VERSION ""

NS_ :

BS_:

BU_: PowertrainControlModule AtmosphericSensor SafetyRestraintSystem2 Aftertreatment_2_GasOutlet Aftertreatment_2_GasIntake DieselPartFilterControl Turbocharger SafetyRestraintSystem1 CabDisplay2 Aftertreatment_1_GasOutlet Aftertreatment_1_GasIntake OnBoardDataLogger OffBoardDiagnosticTool2 OffBoardDiagnosticTool1 FileServer ParkingBrakeController SeatController2 FanDriveController SteeringColumnUnit CommunicationUnitRadio CommunicationUnitSatellite CommunicationUnitCellular PropulsionBatteryCharger ChassisController2 ChassisController1 EngineValveControl AuxiliaryHeater2 AuxiliaryHeater1 ClutchUnit RampControl InformationSystem1 SuspensionSystemController2 OilSensor VehicleDynamicStability ExhaustEmissionController TransmissionDisplay2 TransmissionDisplay1 ClimateControl2 WaterPumpController RearAxleSteeringController LightingOperatorControl SeatController1 IgnitionController2 IgnitionController1 TirePressureController CabController2 CabController1 PneumaticSystemController SuspensionSystemController1 HydraulicPumpController EnduranceBrakingSystem RetarderExhaustEngine2 OnBoardDiagnosticUnit HeadwayController RetarderExhaustEngine1 CabDisplay1 ManagementComputer VirtualTerminal OffVehicleGateway PowerTakeOffFront HitchControl AuxiliaryValveControl BodyController TractorTrailerBridge1 StarterSystem ElectricalSystem VehicleSecurity VehicleNavigation AerodynamicControl ElectricalChargingSystem ClimateControl1 TripRecorder InstrumentCluster SuspensionDriveAxle2 SuspensionDriveAxle1 SuspensionSteerAxle SteeringController FuelSystem CruiseControl RetarderDriveline RetarderEngine BrakesDriveAxle2 BrakesDriveAxle1 BrakesSystemController BrakesSteerAxle AxleDrive2 AxleDrive1 AxleSteering PowerTakeOff ShiftConsoleSecondary ShiftConsolePrimary Transmission2 Transmission1 Engine2 Engine1

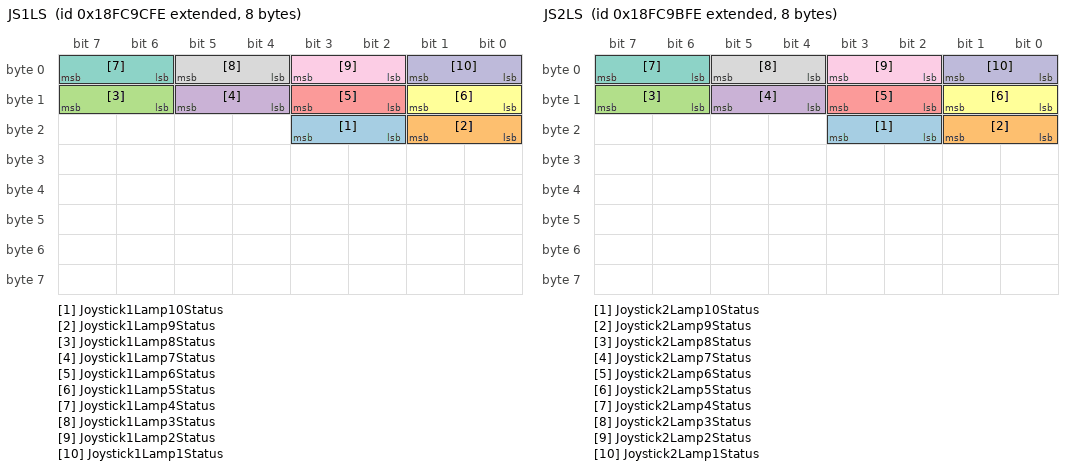
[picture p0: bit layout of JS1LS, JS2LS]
BO_ 2566692094 JS1LS: 8 Vector__XXX
 SG_ Joystick1Lamp10Status : 18|2@1+ (1,0) [0|3] "" Vector__XXX
 SG_ Joystick1Lamp9Status : 16|2@1+ (1,0) [0|3] "" Vector__XXX
 SG_ Joystick1Lamp8Status : 14|2@1+ (1,0) [0|3] "" Vector__XXX
 SG_ Joystick1Lamp7Status : 12|2@1+ (1,0) [0|3] "" Vector__XXX
 SG_ Joystick1Lamp6Status : 10|2@1+ (1,0) [0|3] "" Vector__XXX
 SG_ Joystick1Lamp5Status : 8|2@1+ (1,0) [0|3] "" Vector__XXX
 SG_ Joystick1Lamp4Status : 6|2@1+ (1,0) [0|3] "" Vector__XXX
 SG_ Joystick1Lamp3Status : 4|2@1+ (1,0) [0|3] "" Vector__XXX
 SG_ Joystick1Lamp2Status : 2|2@1+ (1,0) [0|3] "" Vector__XXX
 SG_ Joystick1Lamp1Status : 0|2@1+ (1,0) [0|3] "" Vector__XXX

BO_ 2566691838 JS2LS: 8 Vector__XXX
 SG_ Joystick2Lamp10Status : 18|2@1+ (1,0) [0|3] "" Vector__XXX
 SG_ Joystick2Lamp9Status : 16|2@1+ (1,0) [0|3] "" Vector__XXX
 SG_ Joystick2Lamp8Status : 14|2@1+ (1,0) [0|3] "" Vector__XXX
 SG_ Joystick2Lamp7Status : 12|2@1+ (1,0) [0|3] "" Vector__XXX
 SG_ Joystick2Lamp6Status : 10|2@1+ (1,0) [0|3] "" Vector__XXX
 SG_ Joystick2Lamp5Status : 8|2@1+ (1,0) [0|3] "" Vector__XXX
 SG_ Joystick2Lamp4Status : 6|2@1+ (1,0) [0|3] "" Vector__XXX
 SG_ Joystick2Lamp3Status : 4|2@1+ (1,0) [0|3] "" Vector__XXX
 SG_ Joystick2Lamp2Status : 2|2@1+ (1,0) [0|3] "" Vector__XXX
 SG_ Joystick2Lamp1Status : 0|2@1+ (1,0) [0|3] "" Vector__XXX

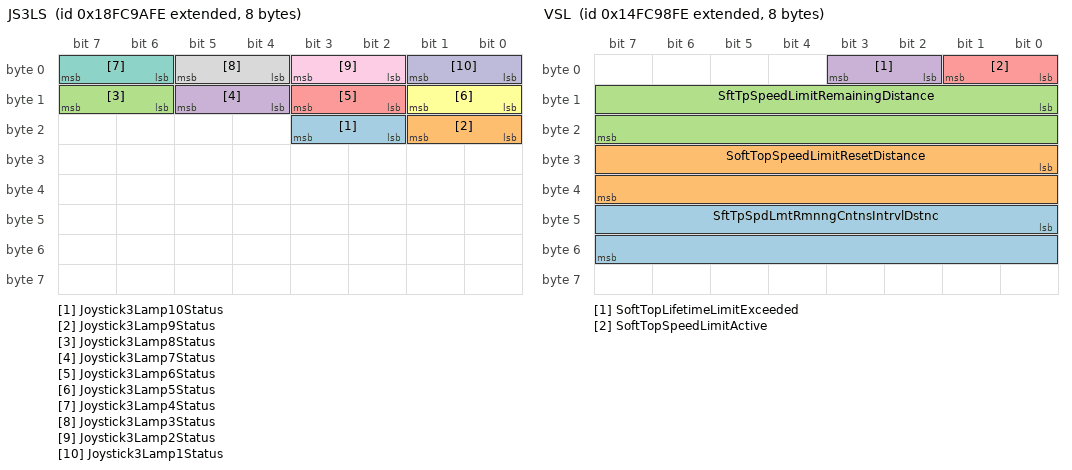
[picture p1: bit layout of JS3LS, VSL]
BO_ 2566691582 JS3LS: 8 Vector__XXX
 SG_ Joystick3Lamp10Status : 18|2@1+ (1,0) [0|3] "" Vector__XXX
 SG_ Joystick3Lamp9Status : 16|2@1+ (1,0) [0|3] "" Vector__XXX
 SG_ Joystick3Lamp8Status : 14|2@1+ (1,0) [0|3] "" Vector__XXX
 SG_ Joystick3Lamp7Status : 12|2@1+ (1,0) [0|3] "" Vector__XXX
 SG_ Joystick3Lamp6Status : 10|2@1+ (1,0) [0|3] "" Vector__XXX
 SG_ Joystick3Lamp5Status : 8|2@1+ (1,0) [0|3] "" Vector__XXX
 SG_ Joystick3Lamp4Status : 6|2@1+ (1,0) [0|3] "" Vector__XXX
 SG_ Joystick3Lamp3Status : 4|2@1+ (1,0) [0|3] "" Vector__XXX
 SG_ Joystick3Lamp2Status : 2|2@1+ (1,0) [0|3] "" Vector__XXX
 SG_ Joystick3Lamp1Status : 0|2@1+ (1,0) [0|3] "" Vector__XXX

BO_ 2566691326 AUI: 8 Vector__XXX
 SG_ AssemblyUnitIdentification : 8|8@1+ (1,0) [0|255] "" Vector__XXX
 SG_ NmbrOfAssmblyUntIdntfctionFields : 0|8@1+ (1,0) [0|250] "" Vector__XXX

BO_ 2499582206 VSL: 8 Vector__XXX
 SG_ SftTpSpdLmtRmnngCntnsIntrvlDstnc : 40|16@1+ (1,0) [0|64255] "km" Vector__XXX
 SG_ SoftTopSpeedLimitResetDistance : 24|16@1+ (1,0) [0|64255] "km" Vector__XXX
 SG_ SftTpSpeedLimitRemainingDistance : 8|16@1+ (1,0) [0|64255] "km" Vector__XXX
 SG_ SoftTopLifetimeLimitExceeded : 2|2@1+ (1,0) [0|3] "" Vector__XXX
 SG_ SoftTopSpeedLimitActive : 0|2@1+ (1,0) [0|3] "" Vector__XXX

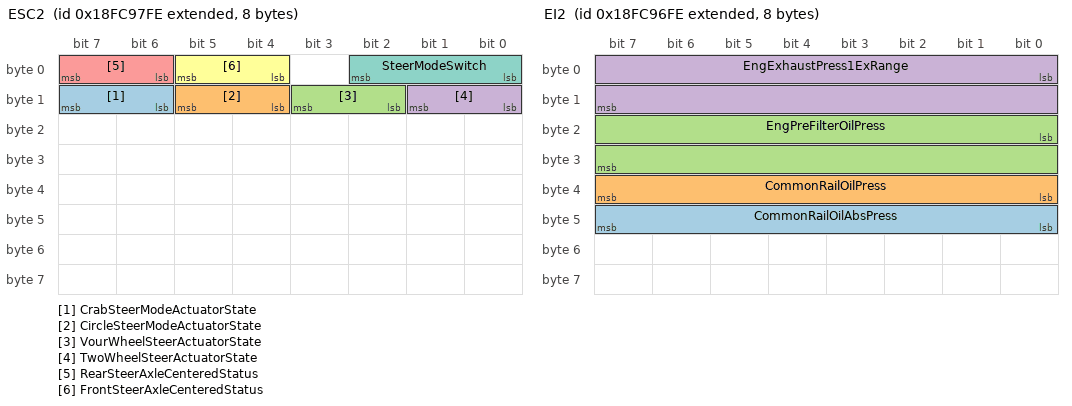
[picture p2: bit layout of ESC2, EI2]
BO_ 2566690814 ESC2: 8 Vector__XXX
 SG_ CrabSteerModeActuatorState : 14|2@1+ (1,0) [0|3] "" Vector__XXX
 SG_ CircleSteerModeActuatorState : 12|2@1+ (1,0) [0|3] "" Vector__XXX
 SG_ VourWheelSteerActuatorState : 10|2@1+ (1,0) [0|3] "" Vector__XXX
 SG_ TwoWheelSteerActuatorState : 8|2@1+ (1,0) [0|3] "" Vector__XXX
 SG_ RearSteerAxleCenteredStatus : 6|2@1+ (1,0) [0|3] "" Vector__XXX
 SG_ FrontSteerAxleCenteredStatus : 4|2@1+ (1,0) [0|3] "" Vector__XXX
 SG_ SteerModeSwitch : 0|3@1+ (1,0) [0|7] "" Vector__XXX

BO_ 2566690558 EI2: 8 Vector__XXX
 SG_ CommonRailOilAbsPress : 40|8@1+ (4,0) [0|1000] "kPa" Vector__XXX
 SG_ CommonRailOilPress : 32|8@1+ (4,0) [0|1000] "kPa" Vector__XXX
 SG_ EngPreFilterOilPress : 16|16@1+ (0.1,0) [0|6425.5] "kPa" Vector__XXX
 SG_ EngExhaustPress1ExRange : 0|16@1+ (0.125,0) [0|8031.875] "kPa" Vector__XXX

BO_ 2365363710 ECPMSI: 8 Vector__XXX
 SG_ EngCylPrssMonitor2PreliminaryFMI : 8|5@1+ (1,0) [0|31] "" Vector__XXX
 SG_ EngCylPrssMonitor1PreliminaryFMI : 0|5@1+ (1,0) [0|31] "" Vector__XXX

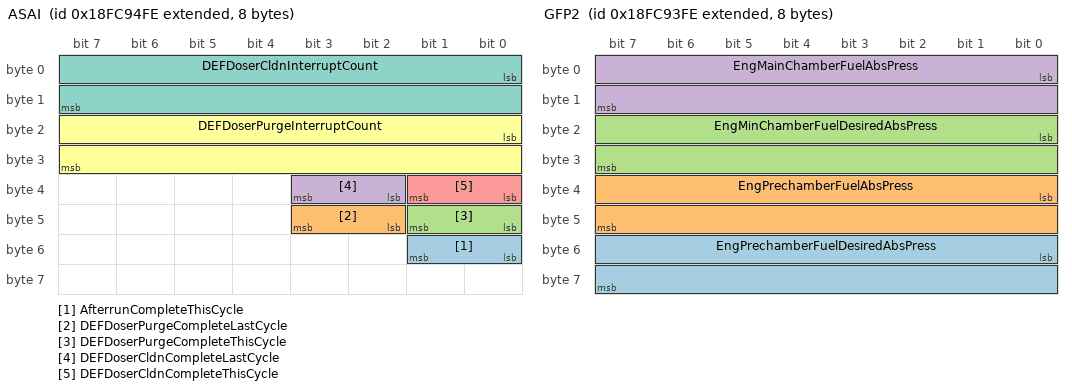
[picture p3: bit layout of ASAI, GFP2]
BO_ 2566690046 ASAI: 8 Vector__XXX
 SG_ AfterrunCompleteThisCycle : 48|2@1+ (1,0) [0|3] "" Vector__XXX
 SG_ DEFDoserPurgeCompleteLastCycle : 42|2@1+ (1,0) [0|3] "" Vector__XXX
 SG_ DEFDoserPurgeCompleteThisCycle : 40|2@1+ (1,0) [0|3] "" Vector__XXX
 SG_ DEFDoserCldnCompleteLastCycle : 34|2@1+ (1,0) [0|3] "" Vector__XXX
 SG_ DEFDoserCldnCompleteThisCycle : 32|2@1+ (1,0) [0|3] "" Vector__XXX
 SG_ DEFDoserPurgeInterruptCount : 16|16@1+ (1,0) [0|64255] "" Vector__XXX
 SG_ DEFDoserCldnInterruptCount : 0|16@1+ (1,0) [0|64255] "" Vector__XXX

BO_ 2566689790 GFP2: 8 Vector__XXX
 SG_ EngPrechamberFuelDesiredAbsPress : 48|16@1+ (0.1,0) [0|6425.5] "kPa" Vector__XXX
 SG_ EngPrechamberFuelAbsPress : 32|16@1+ (0.1,0) [0|6425.5] "kPa" Vector__XXX
 SG_ EngMinChamberFuelDesiredAbsPress : 16|16@1+ (0.1,0) [0|6425.5] "kPa" Vector__XXX
 SG_ EngMainChamberFuelAbsPress : 0|16@1+ (0.1,0) [0|6425.5] "kPa" Vector__XXX

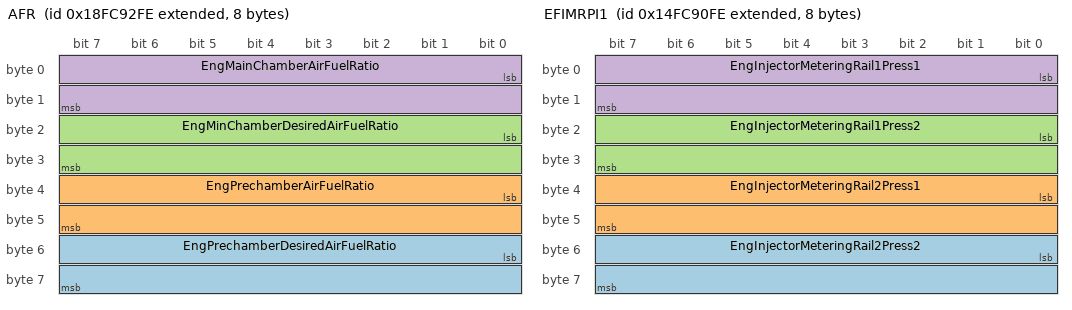
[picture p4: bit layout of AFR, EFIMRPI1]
BO_ 2566689534 AFR: 8 Vector__XXX
 SG_ EngPrechamberDesiredAirFuelRatio : 48|16@1+ (0.001,0) [0|64.255] "" Vector__XXX
 SG_ EngPrechamberAirFuelRatio : 32|16@1+ (0.001,0) [0|64.255] "" Vector__XXX
 SG_ EngMinChamberDesiredAirFuelRatio : 16|16@1+ (0.001,0) [0|64.255] "" Vector__XXX
 SG_ EngMainChamberAirFuelRatio : 0|16@1+ (0.001,0) [0|64.255] "" Vector__XXX

BO_ 2566689278 EEN: 8 Vector__XXX
 SG_ EngExhaustDesiredNOx : 16|16@1+ (0.05,-200) [-200|3012.75] "ppm" Vector__XXX
 SG_ EngExhaustNOx : 0|16@1+ (0.05,-200) [-200|3012.75] "ppm" Vector__XXX

BO_ 2499580158 EFIMRPI1: 8 Vector__XXX
 SG_ EngInjectorMeteringRail2Press2 : 48|16@1+ (0.00390625,0) [0|250.996] "MPa" Vector__XXX
 SG_ EngInjectorMeteringRail2Press1 : 32|16@1+ (0.00390625,0) [0|250.996] "MPa" Vector__XXX
 SG_ EngInjectorMeteringRail1Press2 : 16|16@1+ (0.00390625,0) [0|250.996] "MPa" Vector__XXX
 SG_ EngInjectorMeteringRail1Press1 : 0|16@1+ (0.00390625,0) [0|250.996] "MPa" Vector__XXX

BO_ 2432471038 AF3: 8 Vector__XXX
 SG_ GasFuelAccumulatorTemp : 24|8@1+ (1,-40) [-40|210] "°C" Vector__XXX
 SG_ EngFuelVaporizer1DischargeTemp : 16|8@1+ (1,-40) [-40|210] "°C" Vector__XXX
 SG_ EngGasFuelSupplyPress : 0|16@1+ (0.00390625,0) [0|250.996] "MPa" Vector__XXX

BO_ 2566688510 CFF: 8 Vector__XXX

BO_ 2566688254 PII: 8 Vector__XXX
 SG_ ProductIdentificationModel : 16|8@1+ (1,0) [0|0] "" Vector__XXX
 SG_ ProductIdentificationBrand : 8|8@1+ (1,0) [0|0] "" Vector__XXX
 SG_ ProductIdentificationCode : 0|8@1+ (1,0) [0|0] "" Vector__XXX

BO_ 2364567038 EGFVSOAC5: 8 Vector__XXX
 SG_ EngGsFlVlve20StartOfActuationCmd : 48|16@1+ (0.0078125,-400) [-400|101.99] "deg" Vector__XXX
 SG_ EngGsFlVlve19StartOfActuationCmd : 32|16@1+ (0.0078125,-400) [-400|101.99] "deg" Vector__XXX
 SG_ EngGsFlVlve18StartOfActuationCmd : 16|16@1+ (0.0078125,-400) [-400|101.99] "deg" Vector__XXX
 SG_ EngGsFlVlve17StartOfActuationCmd : 0|16@1+ (0.0078125,-400) [-400|101.99] "deg" Vector__XXX

BO_ 2364566782 EGFVSOAC4: 8 Vector__XXX
 SG_ EngGsFlVlve16StartOfActuationCmd : 48|16@1+ (0.0078125,-400) [-400|101.99] "deg" Vector__XXX
 SG_ EngGsFlVlve15StartOfActuationCmd : 32|16@1+ (0.0078125,-400) [-400|101.99] "deg" Vector__XXX
 SG_ EngGsFlVlve14StartOfActuationCmd : 16|16@1+ (0.0078125,-400) [-400|101.99] "deg" Vector__XXX
 SG_ EngGsFlVlve13StartOfActuationCmd : 0|16@1+ (0.0078125,-400) [-400|101.99] "deg" Vector__XXX

BO_ 2364566526 EGFVSOAC3: 8 Vector__XXX
 SG_ EngGsFlVlve12StartOfActuationCmd : 48|16@1+ (0.0078125,-400) [-400|101.99] "deg" Vector__XXX
 SG_ EngGsFlVlve11StartOfActuationCmd : 32|16@1+ (0.0078125,-400) [-400|101.99] "deg" Vector__XXX
 SG_ EngGsFlVlve10StartOfActuationCmd : 16|16@1+ (0.0078125,-400) [-400|101.99] "deg" Vector__XXX
 SG_ EngGsFlValve9StartOfActuationCmd : 0|16@1+ (0.0078125,-400) [-400|101.99] "deg" Vector__XXX

BO_ 2364566270 EGFVSOAC2: 8 Vector__XXX
 SG_ EngGsFlValve8StartOfActuationCmd : 48|16@1+ (0.0078125,-400) [-400|101.99] "deg" Vector__XXX
 SG_ EngGsFlValve7StartOfActuationCmd : 32|16@1+ (0.0078125,-400) [-400|101.99] "deg" Vector__XXX
 SG_ EngGsFlValve6StartOfActuationCmd : 16|16@1+ (0.0078125,-400) [-400|101.99] "deg" Vector__XXX
 SG_ EngGsFlValve5StartOfActuationCmd : 0|16@1+ (0.0078125,-400) [-400|101.99] "deg" Vector__XXX

BO_ 2364566014 EGFVSOAC1: 8 Vector__XXX
 SG_ EngGsFlValve4StartOfActuationCmd : 48|16@1+ (0.0078125,-400) [-400|101.99] "deg" Vector__XXX
 SG_ EngGsFlValve3StartOfActuationCmd : 32|16@1+ (0.0078125,-400) [-400|101.99] "deg" Vector__XXX
 SG_ EngGsFlValve2StartOfActuationCmd : 16|16@1+ (0.0078125,-400) [-400|101.99] "deg" Vector__XXX
 SG_ EngGsFlValve1StartOfActuationCmd : 0|16@1+ (0.0078125,-400) [-400|101.99] "deg" Vector__XXX

BO_ 2364565758 EGFVDC5: 8 Vector__XXX
 SG_ EngGasFuelValve20DurationCmd : 48|16@1+ (2,0) [0|128510] "µs" Vector__XXX
 SG_ EngGasFuelValve19DurationCmd : 32|16@1+ (2,0) [0|128510] "µs" Vector__XXX
 SG_ EngGasFuelValve18DurationCmd : 16|16@1+ (2,0) [0|128510] "µs" Vector__XXX
 SG_ EngGasFuelValve17DurationCmd : 0|16@1+ (2,0) [0|128510] "µs" Vector__XXX

BO_ 2364565502 EGFVDC4: 8 Vector__XXX
 SG_ EngGasFuelValve16DurationCmd : 48|16@1+ (2,0) [0|128510] "µs" Vector__XXX
 SG_ EngGasFuelValve15DurationCmd : 32|16@1+ (2,0) [0|128510] "µs" Vector__XXX
 SG_ EngGasFuelValve14DurationCmd : 16|16@1+ (2,0) [0|128510] "µs" Vector__XXX
 SG_ EngGasFuelValve13DurationCmd : 0|16@1+ (2,0) [0|128510] "µs" Vector__XXX

BO_ 2364565246 EGFVDC3: 8 Vector__XXX
 SG_ EngGasFuelValve12DurationCmd : 48|16@1+ (2,0) [0|128510] "µs" Vector__XXX
 SG_ EngGasFuelValve11DurationCmd : 32|16@1+ (2,0) [0|128510] "µs" Vector__XXX
 SG_ EngGasFuelValve10DurationCmd : 16|16@1+ (2,0) [0|128510] "µs" Vector__XXX
 SG_ EngGasFuelValve9DurationCmd : 0|16@1+ (2,0) [0|128510] "µs" Vector__XXX

BO_ 2364564990 EGFVDC2: 8 Vector__XXX
 SG_ EngGasFuelValve8DurationCmd : 48|16@1+ (2,0) [0|128510] "µs" Vector__XXX
 SG_ EngGasFuelValve7DurationCmd : 32|16@1+ (2,0) [0|128510] "µs" Vector__XXX
 SG_ EngGasFuelValve6DurationCmd : 16|16@1+ (2,0) [0|128510] "µs" Vector__XXX
 SG_ EngGasFuelValve5DurationCmd : 0|16@1+ (2,0) [0|128510] "µs" Vector__XXX

BO_ 2364564734 EGFVDC1: 8 Vector__XXX
 SG_ EngGasFuelValve4DurationCmd : 48|16@1+ (2,0) [0|128510] "µs" Vector__XXX
 SG_ EngGasFuelValve3DurationCmd : 32|16@1+ (2,0) [0|128510] "µs" Vector__XXX
 SG_ EngGasFuelValve2DurationCmd : 16|16@1+ (2,0) [0|128510] "µs" Vector__XXX
 SG_ EngGasFuelValve1DurationCmd : 0|16@1+ (2,0) [0|128510] "µs" Vector__XXX

BO_ 2364564478 GFI5: 8 Vector__XXX
 SG_ EngGsFlVlvNmnlStrtOfActuationCmd : 16|16@1+ (0.0078125,-400) [-400|101.99] "deg" Vector__XXX
 SG_ EngGsFuelValveNominalDurationCmd : 0|16@1+ (2,0) [0|128510] "µs" Vector__XXX

BO_ 2297455358 ETC12: 8 Vector__XXX
 SG_ TransDirectionalOutputShaftSpeed : 32|16@1+ (1,-32127) [-32127|32128] "rpm" Vector__XXX
 SG_ TransHydrostaticLoop2Press : 16|16@1+ (1,0) [0|64255] "kPa" Vector__XXX
 SG_ TransHydrostaticLoop1Press : 0|16@1+ (1,0) [0|64255] "kPa" Vector__XXX

BO_ 2498781694 ECCAI20: 8 Vector__XXX
 SG_ EngCyl20AvrageCombustionDuration : 48|16@1+ (0.0078125,0) [0|501.99] "deg" Vector__XXX
 SG_ EngCyl20AvrgCntrOfCmbstionTiming : 32|16@1+ (0.0078125,-250) [-250|250.992] "deg" Vector__XXX
 SG_ EngCyl20AvrgStrtOfCmbstionTiming : 16|16@1+ (0.0078125,-250) [-250|250.992] "deg" Vector__XXX
 SG_ EngCyl20IndctdMeanEffectivePress : 0|16@1+ (0.0001220703125,-1) [-1|6.84362793] "MPa" Vector__XXX

BO_ 2498781438 ECCAI19: 8 Vector__XXX
 SG_ EngCyl19AvrageCombustionDuration : 48|16@1+ (0.0078125,0) [0|501.99] "deg" Vector__XXX
 SG_ EngCyl19AvrgCntrOfCmbstionTiming : 32|16@1+ (0.0078125,-250) [-250|250.992] "deg" Vector__XXX
 SG_ EngCyl19AvrgStrtOfCmbstionTiming : 16|16@1+ (0.0078125,-250) [-250|250.992] "deg" Vector__XXX
 SG_ EngCyl19IndctdMeanEffectivePress : 0|16@1+ (0.0001220703125,-1) [-1|6.84362793] "MPa" Vector__XXX

BO_ 2498781182 ECCAI18: 8 Vector__XXX
 SG_ EngCyl18AvrageCombustionDuration : 48|16@1+ (0.0078125,0) [0|501.99] "deg" Vector__XXX
 SG_ EngCyl18AvrgCntrOfCmbstionTiming : 32|16@1+ (0.0078125,-250) [-250|250.992] "deg" Vector__XXX
 SG_ EngCyl18AvrgStrtOfCmbstionTiming : 16|16@1+ (0.0078125,-250) [-250|250.992] "deg" Vector__XXX
 SG_ EngCyl18IndctdMeanEffectivePress : 0|16@1+ (0.0001220703125,-1) [-1|6.84362793] "MPa" Vector__XXX

BO_ 2498780926 ECCAI17: 8 Vector__XXX
 SG_ EngCyl17AvrageCombustionDuration : 48|16@1+ (0.0078125,0) [0|501.99] "deg" Vector__XXX
 SG_ EngCyl17AvrgCntrOfCmbstionTiming : 32|16@1+ (0.0078125,-250) [-250|250.992] "deg" Vector__XXX
 SG_ EngCyl17AvrgStrtOfCmbstionTiming : 16|16@1+ (0.0078125,-250) [-250|250.992] "deg" Vector__XXX
 SG_ EngCyl17IndctdMeanEffectivePress : 0|16@1+ (0.0001220703125,-1) [-1|6.84362793] "MPa" Vector__XXX

BO_ 2498780670 ECCAI16: 8 Vector__XXX
 SG_ EngCyl16AvrageCombustionDuration : 48|16@1+ (0.0078125,0) [0|501.99] "deg" Vector__XXX
 SG_ EngCyl16AvrgCntrOfCmbstionTiming : 32|16@1+ (0.0078125,-250) [-250|250.992] "deg" Vector__XXX
 SG_ EngCyl16AvrgStrtOfCmbstionTiming : 16|16@1+ (0.0078125,-250) [-250|250.992] "deg" Vector__XXX
 SG_ EngCyl16IndctdMeanEffectivePress : 0|16@1+ (0.0001220703125,-1) [-1|6.84362793] "MPa" Vector__XXX

BO_ 2498780414 ECCAI15: 8 Vector__XXX
 SG_ EngCyl15AvrageCombustionDuration : 48|16@1+ (0.0078125,0) [0|501.99] "deg" Vector__XXX
 SG_ EngCyl15AvrgCntrOfCmbstionTiming : 32|16@1+ (0.0078125,-250) [-250|250.992] "deg" Vector__XXX
 SG_ EngCyl15AvrgStrtOfCmbstionTiming : 16|16@1+ (0.0078125,-250) [-250|250.992] "deg" Vector__XXX
 SG_ EngCyl15IndctdMeanEffectivePress : 0|16@1+ (0.0001220703125,-1) [-1|6.84362793] "MPa" Vector__XXX

BO_ 2498780158 ECCAI14: 8 Vector__XXX
 SG_ EngCyl14AvrageCombustionDuration : 48|16@1+ (0.0078125,0) [0|501.99] "deg" Vector__XXX
 SG_ EngCyl14AvrgCntrOfCmbstionTiming : 32|16@1+ (0.0078125,-250) [-250|250.992] "deg" Vector__XXX
 SG_ EngCyl14AvrgStrtOfCmbstionTiming : 16|16@1+ (0.0078125,-250) [-250|250.992] "deg" Vector__XXX
 SG_ EngCyl14IndctdMeanEffectivePress : 0|16@1+ (0.0001220703125,-1) [-1|6.84362793] "MPa" Vector__XXX

BO_ 2498779902 ECCAI13: 8 Vector__XXX
 SG_ EngCyl13AvrageCombustionDuration : 48|16@1+ (0.0078125,0) [0|501.99] "deg" Vector__XXX
 SG_ EngCyl13AvrgCntrOfCmbstionTiming : 32|16@1+ (0.0078125,-250) [-250|250.992] "deg" Vector__XXX
 SG_ EngCyl13AvrgStrtOfCmbstionTiming : 16|16@1+ (0.0078125,-250) [-250|250.992] "deg" Vector__XXX
 SG_ EngCyl13IndctdMeanEffectivePress : 0|16@1+ (0.0001220703125,-1) [-1|6.84362793] "MPa" Vector__XXX

BO_ 2498779646 ECCAI12: 8 Vector__XXX
 SG_ EngCyl12AvrageCombustionDuration : 48|16@1+ (0.0078125,0) [0|501.99] "deg" Vector__XXX
 SG_ EngCyl12AvrgCntrOfCmbstionTiming : 32|16@1+ (0.0078125,-250) [-250|250.992] "deg" Vector__XXX
 SG_ EngCyl12AvrgStrtOfCmbstionTiming : 16|16@1+ (0.0078125,-250) [-250|250.992] "deg" Vector__XXX
 SG_ EngCyl12IndctdMeanEffectivePress : 0|16@1+ (0.0001220703125,-1) [-1|6.84362793] "MPa" Vector__XXX

BO_ 2498779390 ECCAI11: 8 Vector__XXX
 SG_ EngCyl11AvrageCombustionDuration : 48|16@1+ (0.0078125,0) [0|501.99] "deg" Vector__XXX
 SG_ EngCyl11AvrgCntrOfCmbstionTiming : 32|16@1+ (0.0078125,-250) [-250|250.992] "deg" Vector__XXX
 SG_ EngCyl11AvrgStrtOfCmbstionTiming : 16|16@1+ (0.0078125,-250) [-250|250.992] "deg" Vector__XXX
 SG_ EngCyl11IndctdMeanEffectivePress : 0|16@1+ (0.0001220703125,-1) [-1|6.84362793] "MPa" Vector__XXX

BO_ 2498779134 ECCAI10: 8 Vector__XXX
 SG_ EngCyl10AvrageCombustionDuration : 48|16@1+ (0.0078125,0) [0|501.99] "deg" Vector__XXX
 SG_ EngCyl10AvrgCntrOfCmbstionTiming : 32|16@1+ (0.0078125,-250) [-250|250.992] "deg" Vector__XXX
 SG_ EngCyl10AvrgStrtOfCmbstionTiming : 16|16@1+ (0.0078125,-250) [-250|250.992] "deg" Vector__XXX
 SG_ EngCyl10IndctdMeanEffectivePress : 0|16@1+ (0.0001220703125,-1) [-1|6.84362793] "MPa" Vector__XXX

BO_ 2498778878 ECCAI9: 8 Vector__XXX
 SG_ EngCyl9AverageCombustionDuration : 48|16@1+ (0.0078125,0) [0|501.99] "deg" Vector__XXX
 SG_ EngCyl9AvrgCntrOfCmbustionTiming : 32|16@1+ (0.0078125,-250) [-250|250.992] "deg" Vector__XXX
 SG_ EngCyl9AvrgStrtOfCmbustionTiming : 16|16@1+ (0.0078125,-250) [-250|250.992] "deg" Vector__XXX
 SG_ EngCyl9IndctedMeanEffectivePress : 0|16@1+ (0.0001220703125,-1) [-1|6.84362793] "MPa" Vector__XXX

BO_ 2566757118 EBS24: 8 Vector__XXX

BO_ 2559246078 RGE12: 8 Vector__XXX

BO_ 2559180542 RGE24: 8 Vector__XXX

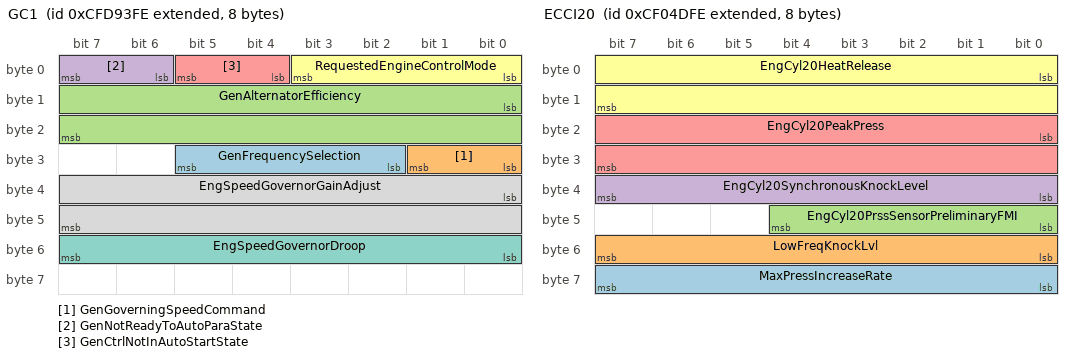
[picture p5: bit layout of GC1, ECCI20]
BO_ 2365428734 GC1: 8 Vector__XXX
 SG_ GenFrequencySelection : 26|4@1+ (1,0) [0|15] "" Vector__XXX
 SG_ GenGoverningSpeedCommand : 24|2@1+ (1,0) [0|3] "" Vector__XXX
 SG_ GenAlternatorEfficiency : 8|16@1+ (0.0025,0) [0|100] "%" Vector__XXX
 SG_ GenNotReadyToAutoParaState : 6|2@1+ (1,0) [0|3] "" Vector__XXX
 SG_ GenCtrlNotInAutoStartState : 4|2@1+ (1,0) [0|3] "" Vector__XXX
 SG_ RequestedEngineControlMode : 0|4@1+ (1,0) [0|15] "" Vector__XXX
 SG_ EngSpeedGovernorDroop : 48|8@1+ (0.04,0) [0|10] "%" Vector__XXX
 SG_ EngSpeedGovernorGainAdjust : 32|16@1+ (1,-32128) [-32128|32127] "" Vector__XXX

BO_ 2566702846 DM57: 8 Vector__XXX
 SG_ EngOBDWarmUpSequence : 0|2@1+ (1,0) [0|3] "" Vector__XXX

BO_ 2566703102 DM56: 208 Vector__XXX
 SG_ CertificationEngineFamilyName : 64|64@1+ (1,0) [0|255] "" Vector__XXX
 SG_ ModelYear : 0|64@1+ (1,0) [0|255] "" Vector__XXX

BO_ 2566705918 DM54: 22 Vector__XXX
 SG_ DTC1 : 16|32@1+ (1,0) [0|4294967295] "" Vector__XXX
 SG_ FlashProtectLamp : 8|2@1+ (1,0) [0|3] "" Vector__XXX
 SG_ FlashAmberWarningLamp : 10|2@1+ (1,0) [0|3] "" Vector__XXX
 SG_ FlashRedStopLamp : 12|2@1+ (1,0) [0|3] "" Vector__XXX
 SG_ FlashMalfuncIndicatorLamp : 14|2@1+ (1,0) [0|3] "" Vector__XXX
 SG_ ProtectLampStatus : 0|2@1+ (1,0) [0|3] "" Vector__XXX
 SG_ AmberWarningLampStatus : 2|2@1+ (1,0) [0|3] "" Vector__XXX
 SG_ RedStopLampState : 4|2@1+ (1,0) [0|3] "" Vector__XXX
 SG_ MalfunctionIndicatorLampStatus : 6|2@1+ (1,0) [0|3] "" Vector__XXX
 SG_ DTC5 : 144|32@1+ (1,0) [0|4294967295] "" Vector__XXX
 SG_ DTC4 : 112|32@1+ (1,0) [0|4294967295] "" Vector__XXX
 SG_ DTC3 : 80|32@1+ (1,0) [0|4294967295] "" Vector__XXX
 SG_ DTC2 : 48|32@1+ (1,0) [0|4294967295] "" Vector__XXX

BO_ 2566705662 DM53: 22 Vector__XXX
 SG_ DTC1 : 16|32@1+ (1,0) [0|4294967295] "" Vector__XXX
 SG_ FlashProtectLamp : 8|2@1+ (1,0) [0|3] "" Vector__XXX
 SG_ FlashAmberWarningLamp : 10|2@1+ (1,0) [0|3] "" Vector__XXX
 SG_ FlashRedStopLamp : 12|2@1+ (1,0) [0|3] "" Vector__XXX
 SG_ FlashMalfuncIndicatorLamp : 14|2@1+ (1,0) [0|3] "" Vector__XXX
 SG_ ProtectLampStatus : 0|2@1+ (1,0) [0|3] "" Vector__XXX
 SG_ AmberWarningLampStatus : 2|2@1+ (1,0) [0|3] "" Vector__XXX
 SG_ RedStopLampState : 4|2@1+ (1,0) [0|3] "" Vector__XXX
 SG_ MalfunctionIndicatorLampStatus : 6|2@1+ (1,0) [0|3] "" Vector__XXX
 SG_ DTC5 : 144|32@1+ (1,0) [0|4294967295] "" Vector__XXX
 SG_ DTC4 : 112|32@1+ (1,0) [0|4294967295] "" Vector__XXX
 SG_ DTC3 : 80|32@1+ (1,0) [0|4294967295] "" Vector__XXX
 SG_ DTC2 : 48|32@1+ (1,0) [0|4294967295] "" Vector__XXX

BO_ 2566706174 DM55: 0 Vector__XXX

BO_ 2349465342 SRASI: 8 Vector__XXX
 SG_ StaticRollAngleStatus : 8|3@1+ (1,0) [0|7] "" Vector__XXX
 SG_ StaticRollAngle : 0|8@1+ (1,-125) [-90|90] "deg" Vector__XXX

BO_ 2498777086 ECCAI2: 8 Vector__XXX
 SG_ EngCyl2AverageCombustionDuration : 48|16@1+ (0.0078125,0) [0|501.99] "deg" Vector__XXX
 SG_ EngCyl2AvrgCntrOfCmbustionTiming : 32|16@1+ (0.0078125,-250) [-250|250.992] "deg" Vector__XXX
 SG_ EngCyl2AvrgStrtOfCmbustionTiming : 16|16@1+ (0.0078125,-250) [-250|250.992] "deg" Vector__XXX
 SG_ EngCyl2IndctedMeanEffectivePress : 0|16@1+ (0.0001220703125,-1) [-1|6.84362793] "MPa" Vector__XXX

BO_ 2498776830 ECCAI1: 8 Vector__XXX
 SG_ EngCyl1AverageCombustionDuration : 48|16@1+ (0.0078125,0) [0|501.99] "deg" Vector__XXX
 SG_ EngCyl1AvrgCntrOfCmbustionTiming : 32|16@1+ (0.0078125,-250) [-250|250.992] "deg" Vector__XXX
 SG_ EngCyl1AvrgStrtOfCmbustionTiming : 16|16@1+ (0.0078125,-250) [-250|250.992] "deg" Vector__XXX
 SG_ EngCyl1IndctedMeanEffectivePress : 0|16@1+ (0.0001220703125,-1) [-1|6.84362793] "MPa" Vector__XXX

BO_ 2364558846 ECCI20: 8 Vector__XXX
 SG_ MaxPressIncreaseRate : 56|8@1+ (16,0) [0|4000] "kPa/deg crank angle" Vector__XXX
 SG_ LowFreqKnockLvl : 48|8@1+ (1,0) [0|250] "%" Vector__XXX
 SG_ EngCyl20PrssSensorPreliminaryFMI : 40|5@1+ (1,0) [0|31] "" Vector__XXX
 SG_ EngCyl20SynchronousKnockLevel : 32|8@1+ (1,0) [0|250] "%" Vector__XXX
 SG_ EngCyl20PeakPress : 16|16@1+ (0.0009765625,0) [0|62.74902344] "MPa" Vector__XXX
 SG_ EngCyl20HeatRelease : 0|16@1+ (0.0001220703125,-1) [-1|6.84362793] "kJ/l" Vector__XXX

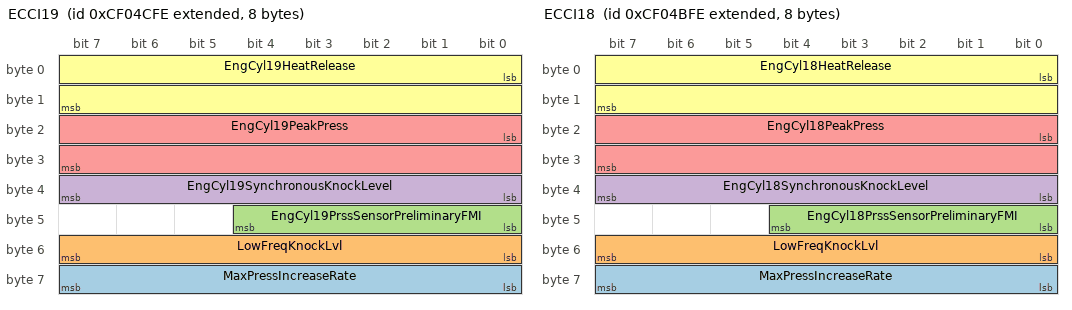
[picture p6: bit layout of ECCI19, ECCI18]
BO_ 2364558590 ECCI19: 8 Vector__XXX
 SG_ MaxPressIncreaseRate : 56|8@1+ (16,0) [0|4000] "kPa/deg crank angle" Vector__XXX
 SG_ LowFreqKnockLvl : 48|8@1+ (1,0) [0|250] "%" Vector__XXX
 SG_ EngCyl19PrssSensorPreliminaryFMI : 40|5@1+ (1,0) [0|31] "" Vector__XXX
 SG_ EngCyl19SynchronousKnockLevel : 32|8@1+ (1,0) [0|250] "%" Vector__XXX
 SG_ EngCyl19PeakPress : 16|16@1+ (0.0009765625,0) [0|62.74902344] "MPa" Vector__XXX
 SG_ EngCyl19HeatRelease : 0|16@1+ (0.0001220703125,-1) [-1|6.84362793] "kJ/l" Vector__XXX

BO_ 2364558334 ECCI18: 8 Vector__XXX
 SG_ MaxPressIncreaseRate : 56|8@1+ (16,0) [0|4000] "kPa/deg crank angle" Vector__XXX
 SG_ LowFreqKnockLvl : 48|8@1+ (1,0) [0|250] "%" Vector__XXX
 SG_ EngCyl18PrssSensorPreliminaryFMI : 40|5@1+ (1,0) [0|31] "" Vector__XXX
 SG_ EngCyl18SynchronousKnockLevel : 32|8@1+ (1,0) [0|250] "%" Vector__XXX
 SG_ EngCyl18PeakPress : 16|16@1+ (0.0009765625,0) [0|62.74902344] "MPa" Vector__XXX
 SG_ EngCyl18HeatRelease : 0|16@1+ (0.0001220703125,-1) [-1|6.84362793] "kJ/l" Vector__XXX

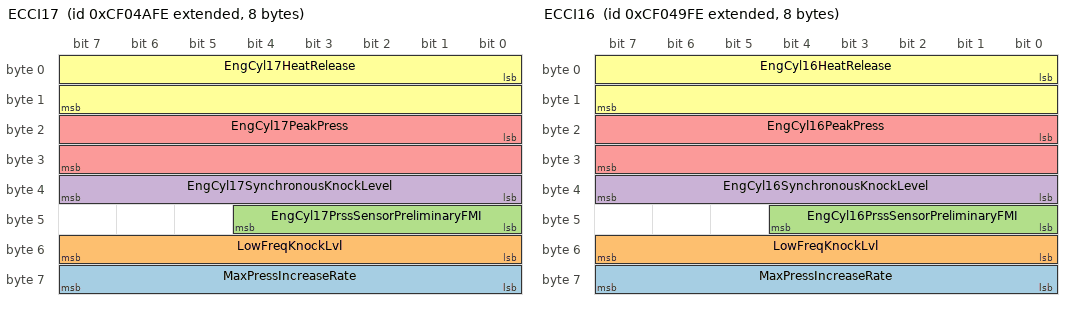
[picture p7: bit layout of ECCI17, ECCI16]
BO_ 2364558078 ECCI17: 8 Vector__XXX
 SG_ MaxPressIncreaseRate : 56|8@1+ (16,0) [0|4000] "kPa/deg crank angle" Vector__XXX
 SG_ LowFreqKnockLvl : 48|8@1+ (1,0) [0|250] "%" Vector__XXX
 SG_ EngCyl17PrssSensorPreliminaryFMI : 40|5@1+ (1,0) [0|31] "" Vector__XXX
 SG_ EngCyl17SynchronousKnockLevel : 32|8@1+ (1,0) [0|250] "%" Vector__XXX
 SG_ EngCyl17PeakPress : 16|16@1+ (0.0009765625,0) [0|62.74902344] "MPa" Vector__XXX
 SG_ EngCyl17HeatRelease : 0|16@1+ (0.0001220703125,-1) [-1|6.84362793] "kJ/l" Vector__XXX

BO_ 2364557822 ECCI16: 8 Vector__XXX
 SG_ MaxPressIncreaseRate : 56|8@1+ (16,0) [0|4000] "kPa/deg crank angle" Vector__XXX
 SG_ LowFreqKnockLvl : 48|8@1+ (1,0) [0|250] "%" Vector__XXX
 SG_ EngCyl16PrssSensorPreliminaryFMI : 40|5@1+ (1,0) [0|31] "" Vector__XXX
 SG_ EngCyl16SynchronousKnockLevel : 32|8@1+ (1,0) [0|250] "%" Vector__XXX
 SG_ EngCyl16PeakPress : 16|16@1+ (0.0009765625,0) [0|62.74902344] "MPa" Vector__XXX
 SG_ EngCyl16HeatRelease : 0|16@1+ (0.0001220703125,-1) [-1|6.84362793] "kJ/l" Vector__XXX

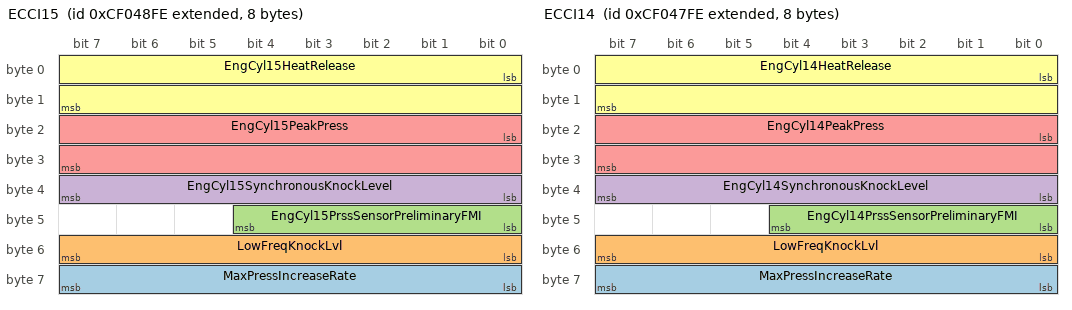
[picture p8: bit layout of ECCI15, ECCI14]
BO_ 2364557566 ECCI15: 8 Vector__XXX
 SG_ MaxPressIncreaseRate : 56|8@1+ (16,0) [0|4000] "kPa/deg crank angle" Vector__XXX
 SG_ LowFreqKnockLvl : 48|8@1+ (1,0) [0|250] "%" Vector__XXX
 SG_ EngCyl15PrssSensorPreliminaryFMI : 40|5@1+ (1,0) [0|31] "" Vector__XXX
 SG_ EngCyl15SynchronousKnockLevel : 32|8@1+ (1,0) [0|250] "%" Vector__XXX
 SG_ EngCyl15PeakPress : 16|16@1+ (0.0009765625,0) [0|62.74902344] "MPa" Vector__XXX
 SG_ EngCyl15HeatRelease : 0|16@1+ (0.0001220703125,-1) [-1|6.84362793] "kJ/l" Vector__XXX

BO_ 2364557310 ECCI14: 8 Vector__XXX
 SG_ MaxPressIncreaseRate : 56|8@1+ (16,0) [0|4000] "kPa/deg crank angle" Vector__XXX
 SG_ LowFreqKnockLvl : 48|8@1+ (1,0) [0|250] "%" Vector__XXX
 SG_ EngCyl14PrssSensorPreliminaryFMI : 40|5@1+ (1,0) [0|31] "" Vector__XXX
 SG_ EngCyl14SynchronousKnockLevel : 32|8@1+ (1,0) [0|250] "%" Vector__XXX
 SG_ EngCyl14PeakPress : 16|16@1+ (0.0009765625,0) [0|62.74902344] "MPa" Vector__XXX
 SG_ EngCyl14HeatRelease : 0|16@1+ (0.0001220703125,-1) [-1|6.84362793] "kJ/l" Vector__XXX

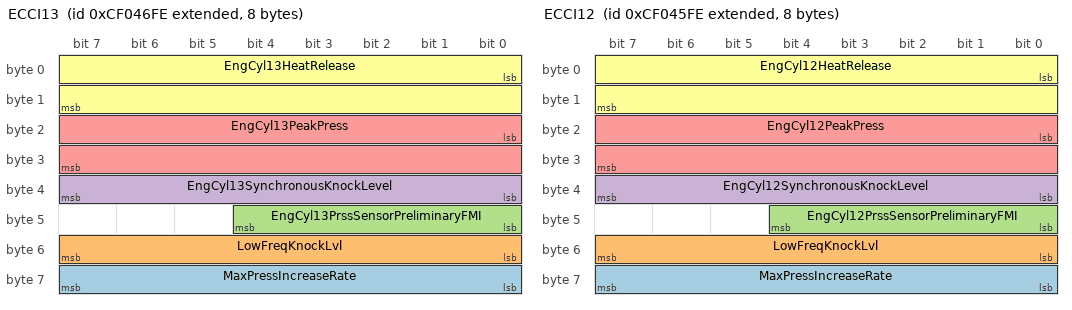
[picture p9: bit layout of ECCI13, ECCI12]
BO_ 2364557054 ECCI13: 8 Vector__XXX
 SG_ MaxPressIncreaseRate : 56|8@1+ (16,0) [0|4000] "kPa/deg crank angle" Vector__XXX
 SG_ LowFreqKnockLvl : 48|8@1+ (1,0) [0|250] "%" Vector__XXX
 SG_ EngCyl13PrssSensorPreliminaryFMI : 40|5@1+ (1,0) [0|31] "" Vector__XXX
 SG_ EngCyl13SynchronousKnockLevel : 32|8@1+ (1,0) [0|250] "%" Vector__XXX
 SG_ EngCyl13PeakPress : 16|16@1+ (0.0009765625,0) [0|62.74902344] "MPa" Vector__XXX
 SG_ EngCyl13HeatRelease : 0|16@1+ (0.0001220703125,-1) [-1|6.84362793] "kJ/l" Vector__XXX

BO_ 2364556798 ECCI12: 8 Vector__XXX
 SG_ MaxPressIncreaseRate : 56|8@1+ (16,0) [0|4000] "kPa/deg crank angle" Vector__XXX
 SG_ LowFreqKnockLvl : 48|8@1+ (1,0) [0|250] "%" Vector__XXX
 SG_ EngCyl12PrssSensorPreliminaryFMI : 40|5@1+ (1,0) [0|31] "" Vector__XXX
 SG_ EngCyl12SynchronousKnockLevel : 32|8@1+ (1,0) [0|250] "%" Vector__XXX
 SG_ EngCyl12PeakPress : 16|16@1+ (0.0009765625,0) [0|62.74902344] "MPa" Vector__XXX
 SG_ EngCyl12HeatRelease : 0|16@1+ (0.0001220703125,-1) [-1|6.84362793] "kJ/l" Vector__XXX

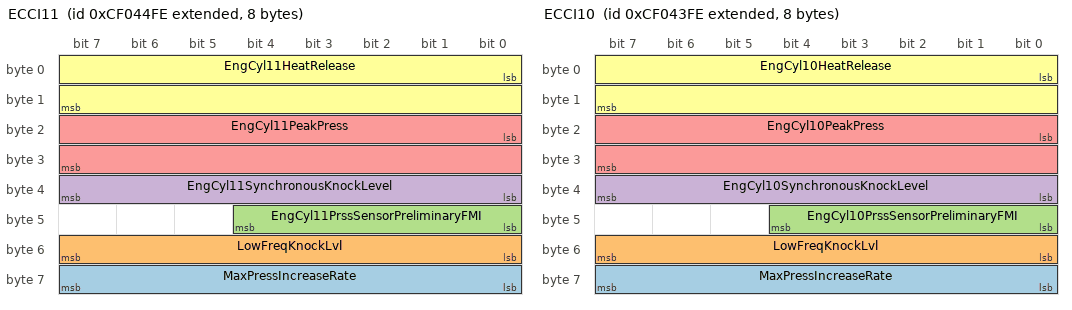
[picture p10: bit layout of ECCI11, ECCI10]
BO_ 2364556542 ECCI11: 8 Vector__XXX
 SG_ MaxPressIncreaseRate : 56|8@1+ (16,0) [0|4000] "kPa/deg crank angle" Vector__XXX
 SG_ LowFreqKnockLvl : 48|8@1+ (1,0) [0|250] "%" Vector__XXX
 SG_ EngCyl11PrssSensorPreliminaryFMI : 40|5@1+ (1,0) [0|31] "" Vector__XXX
 SG_ EngCyl11SynchronousKnockLevel : 32|8@1+ (1,0) [0|250] "%" Vector__XXX
 SG_ EngCyl11PeakPress : 16|16@1+ (0.0009765625,0) [0|62.74902344] "MPa" Vector__XXX
 SG_ EngCyl11HeatRelease : 0|16@1+ (0.0001220703125,-1) [-1|6.84362793] "kJ/l" Vector__XXX

BO_ 2364556286 ECCI10: 8 Vector__XXX
 SG_ MaxPressIncreaseRate : 56|8@1+ (16,0) [0|4000] "kPa/deg crank angle" Vector__XXX
 SG_ LowFreqKnockLvl : 48|8@1+ (1,0) [0|250] "%" Vector__XXX
 SG_ EngCyl10PrssSensorPreliminaryFMI : 40|5@1+ (1,0) [0|31] "" Vector__XXX
 SG_ EngCyl10SynchronousKnockLevel : 32|8@1+ (1,0) [0|250] "%" Vector__XXX
 SG_ EngCyl10PeakPress : 16|16@1+ (0.0009765625,0) [0|62.74902344] "MPa" Vector__XXX
 SG_ EngCyl10HeatRelease : 0|16@1+ (0.0001220703125,-1) [-1|6.84362793] "kJ/l" Vector__XXX

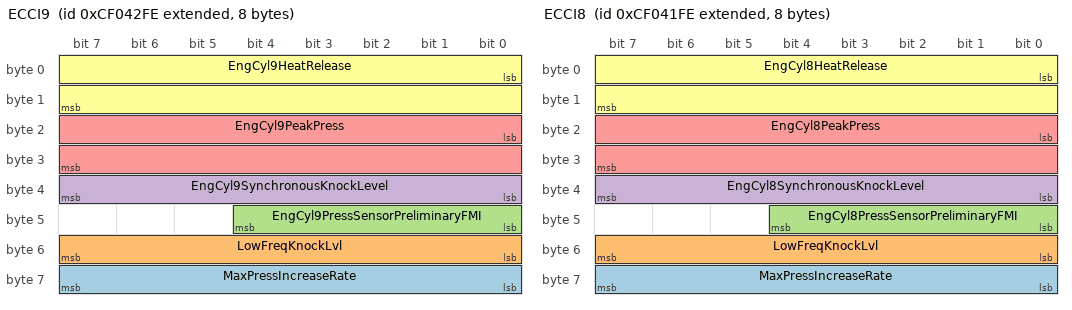
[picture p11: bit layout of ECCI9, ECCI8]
BO_ 2364556030 ECCI9: 8 Vector__XXX
 SG_ MaxPressIncreaseRate : 56|8@1+ (16,0) [0|4000] "kPa/deg crank angle" Vector__XXX
 SG_ LowFreqKnockLvl : 48|8@1+ (1,0) [0|250] "%" Vector__XXX
 SG_ EngCyl9PressSensorPreliminaryFMI : 40|5@1+ (1,0) [0|31] "" Vector__XXX
 SG_ EngCyl9SynchronousKnockLevel : 32|8@1+ (1,0) [0|250] "%" Vector__XXX
 SG_ EngCyl9PeakPress : 16|16@1+ (0.0009765625,0) [0|62.74902344] "MPa" Vector__XXX
 SG_ EngCyl9HeatRelease : 0|16@1+ (0.0001220703125,-1) [-1|6.84362793] "kJ/l" Vector__XXX

BO_ 2364555774 ECCI8: 8 Vector__XXX
 SG_ MaxPressIncreaseRate : 56|8@1+ (16,0) [0|4000] "kPa/deg crank angle" Vector__XXX
 SG_ LowFreqKnockLvl : 48|8@1+ (1,0) [0|250] "%" Vector__XXX
 SG_ EngCyl8PressSensorPreliminaryFMI : 40|5@1+ (1,0) [0|31] "" Vector__XXX
 SG_ EngCyl8SynchronousKnockLevel : 32|8@1+ (1,0) [0|250] "%" Vector__XXX
 SG_ EngCyl8PeakPress : 16|16@1+ (0.0009765625,0) [0|62.74902344] "MPa" Vector__XXX
 SG_ EngCyl8HeatRelease : 0|16@1+ (0.0001220703125,-1) [-1|6.84362793] "kJ/l" Vector__XXX

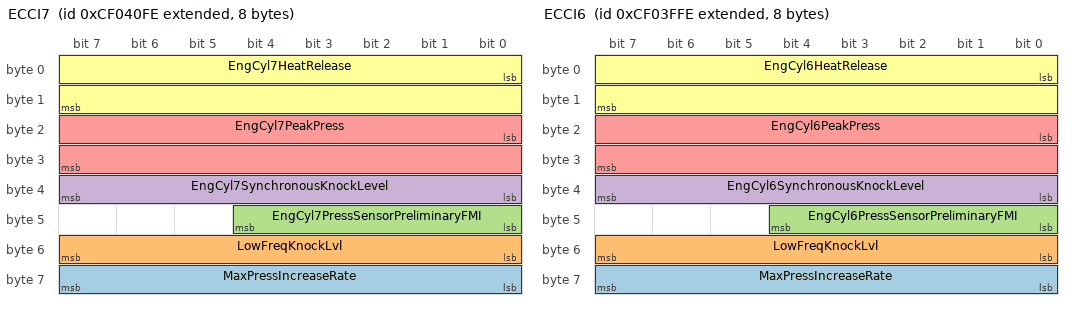
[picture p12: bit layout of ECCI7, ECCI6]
BO_ 2364555518 ECCI7: 8 Vector__XXX
 SG_ MaxPressIncreaseRate : 56|8@1+ (16,0) [0|4000] "kPa/deg crank angle" Vector__XXX
 SG_ LowFreqKnockLvl : 48|8@1+ (1,0) [0|250] "%" Vector__XXX
 SG_ EngCyl7PressSensorPreliminaryFMI : 40|5@1+ (1,0) [0|31] "" Vector__XXX
 SG_ EngCyl7SynchronousKnockLevel : 32|8@1+ (1,0) [0|250] "%" Vector__XXX
 SG_ EngCyl7PeakPress : 16|16@1+ (0.0009765625,0) [0|62.74902344] "MPa" Vector__XXX
 SG_ EngCyl7HeatRelease : 0|16@1+ (0.0001220703125,-1) [-1|6.84362793] "kJ/l" Vector__XXX

BO_ 2364555262 ECCI6: 8 Vector__XXX
 SG_ MaxPressIncreaseRate : 56|8@1+ (16,0) [0|4000] "kPa/deg crank angle" Vector__XXX
 SG_ LowFreqKnockLvl : 48|8@1+ (1,0) [0|250] "%" Vector__XXX
 SG_ EngCyl6PressSensorPreliminaryFMI : 40|5@1+ (1,0) [0|31] "" Vector__XXX
 SG_ EngCyl6SynchronousKnockLevel : 32|8@1+ (1,0) [0|250] "%" Vector__XXX
 SG_ EngCyl6PeakPress : 16|16@1+ (0.0009765625,0) [0|62.74902344] "MPa" Vector__XXX
 SG_ EngCyl6HeatRelease : 0|16@1+ (0.0001220703125,-1) [-1|6.84362793] "kJ/l" Vector__XXX

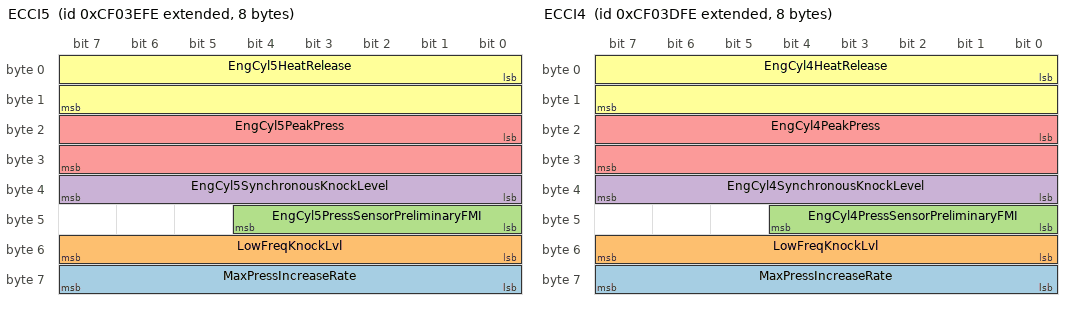
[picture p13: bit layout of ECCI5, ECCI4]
BO_ 2364555006 ECCI5: 8 Vector__XXX
 SG_ MaxPressIncreaseRate : 56|8@1+ (16,0) [0|4000] "kPa/deg crank angle" Vector__XXX
 SG_ LowFreqKnockLvl : 48|8@1+ (1,0) [0|250] "%" Vector__XXX
 SG_ EngCyl5PressSensorPreliminaryFMI : 40|5@1+ (1,0) [0|31] "" Vector__XXX
 SG_ EngCyl5SynchronousKnockLevel : 32|8@1+ (1,0) [0|250] "%" Vector__XXX
 SG_ EngCyl5PeakPress : 16|16@1+ (0.0009765625,0) [0|62.74902344] "MPa" Vector__XXX
 SG_ EngCyl5HeatRelease : 0|16@1+ (0.0001220703125,-1) [-1|6.84362793] "kJ/l" Vector__XXX

BO_ 2364554750 ECCI4: 8 Vector__XXX
 SG_ MaxPressIncreaseRate : 56|8@1+ (16,0) [0|4000] "kPa/deg crank angle" Vector__XXX
 SG_ LowFreqKnockLvl : 48|8@1+ (1,0) [0|250] "%" Vector__XXX
 SG_ EngCyl4PressSensorPreliminaryFMI : 40|5@1+ (1,0) [0|31] "" Vector__XXX
 SG_ EngCyl4SynchronousKnockLevel : 32|8@1+ (1,0) [0|250] "%" Vector__XXX
 SG_ EngCyl4PeakPress : 16|16@1+ (0.0009765625,0) [0|62.74902344] "MPa" Vector__XXX
 SG_ EngCyl4HeatRelease : 0|16@1+ (0.0001220703125,-1) [-1|6.84362793] "kJ/l" Vector__XXX

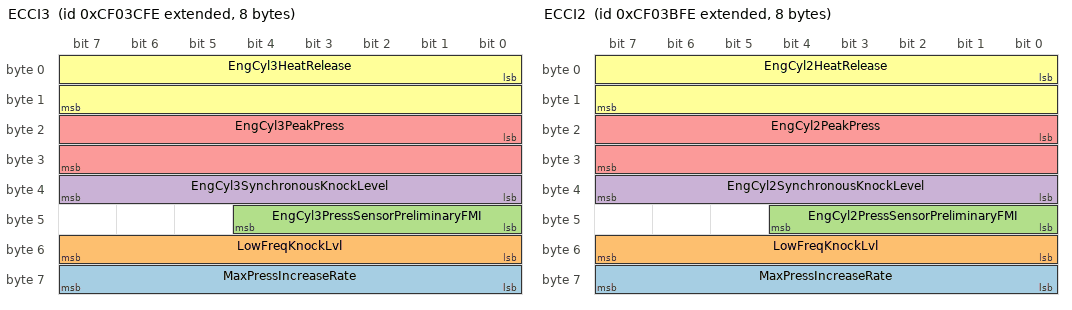
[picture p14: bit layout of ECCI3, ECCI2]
BO_ 2364554494 ECCI3: 8 Vector__XXX
 SG_ MaxPressIncreaseRate : 56|8@1+ (16,0) [0|4000] "kPa/deg crank angle" Vector__XXX
 SG_ LowFreqKnockLvl : 48|8@1+ (1,0) [0|250] "%" Vector__XXX
 SG_ EngCyl3PressSensorPreliminaryFMI : 40|5@1+ (1,0) [0|31] "" Vector__XXX
 SG_ EngCyl3SynchronousKnockLevel : 32|8@1+ (1,0) [0|250] "%" Vector__XXX
 SG_ EngCyl3PeakPress : 16|16@1+ (0.0009765625,0) [0|62.74902344] "MPa" Vector__XXX
 SG_ EngCyl3HeatRelease : 0|16@1+ (0.0001220703125,-1) [-1|6.84362793] "kJ/l" Vector__XXX

BO_ 2364554238 ECCI2: 8 Vector__XXX
 SG_ MaxPressIncreaseRate : 56|8@1+ (16,0) [0|4000] "kPa/deg crank angle" Vector__XXX
 SG_ LowFreqKnockLvl : 48|8@1+ (1,0) [0|250] "%" Vector__XXX
 SG_ EngCyl2PressSensorPreliminaryFMI : 40|5@1+ (1,0) [0|31] "" Vector__XXX
 SG_ EngCyl2SynchronousKnockLevel : 32|8@1+ (1,0) [0|250] "%" Vector__XXX
 SG_ EngCyl2PeakPress : 16|16@1+ (0.0009765625,0) [0|62.74902344] "MPa" Vector__XXX
 SG_ EngCyl2HeatRelease : 0|16@1+ (0.0001220703125,-1) [-1|6.84362793] "kJ/l" Vector__XXX

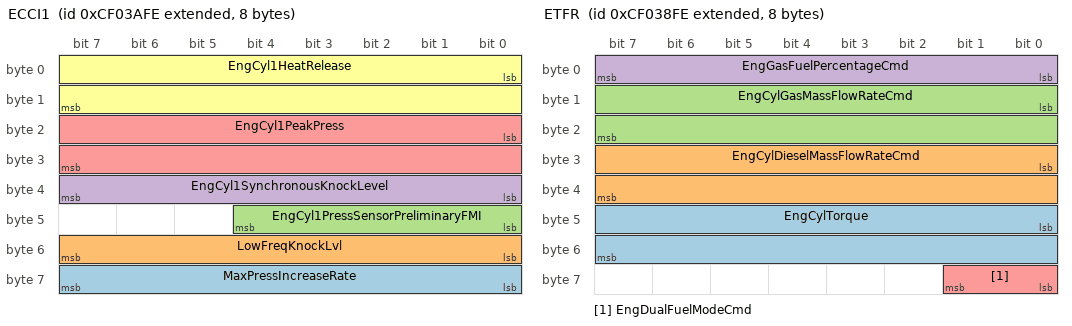
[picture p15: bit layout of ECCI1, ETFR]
BO_ 2364553982 ECCI1: 8 Vector__XXX
 SG_ MaxPressIncreaseRate : 56|8@1+ (16,0) [0|4000] "kPa/deg crank angle" Vector__XXX
 SG_ LowFreqKnockLvl : 48|8@1+ (1,0) [0|250] "%" Vector__XXX
 SG_ EngCyl1PressSensorPreliminaryFMI : 40|5@1+ (1,0) [0|31] "" Vector__XXX
 SG_ EngCyl1SynchronousKnockLevel : 32|8@1+ (1,0) [0|100] "%" Vector__XXX
 SG_ EngCyl1PeakPress : 16|16@1+ (0.0009765625,0) [0|62.74902344] "MPa" Vector__XXX
 SG_ EngCyl1HeatRelease : 0|16@1+ (0.0001220703125,-1) [-1|6.84362793] "kJ/l" Vector__XXX

BO_ 2364553726 EASI: 8 Vector__XXX
 SG_ EngTotalIntakeMassAirFlowRate : 16|16@1+ (0.0009765625,0) [0|62.74902344] "kg/s" Vector__XXX
 SG_ EngDesiredAirFuelRatio : 0|16@1+ (0.001,0) [0|64.255] "" Vector__XXX

BO_ 2364553470 ETFR: 8 Vector__XXX
 SG_ EngCylTorque : 40|16@1+ (1,0) [0|64255] "Nm" Vector__XXX
 SG_ EngCylDieselMassFlowRateCmd : 24|16@1+ (6.103515625E-005,0) [0|3.921813965] "kg/s" Vector__XXX
 SG_ EngCylGasMassFlowRateCmd : 8|16@1+ (6.103515625E-005,0) [0|3.921813965] "kg/s" Vector__XXX
 SG_ EngGasFuelPercentageCmd : 0|8@1+ (0.5,0) [0|100] "%" Vector__XXX
 SG_ EngDualFuelModeCmd : 56|2@1+ (1,0) [0|100] "" Vector__XXX

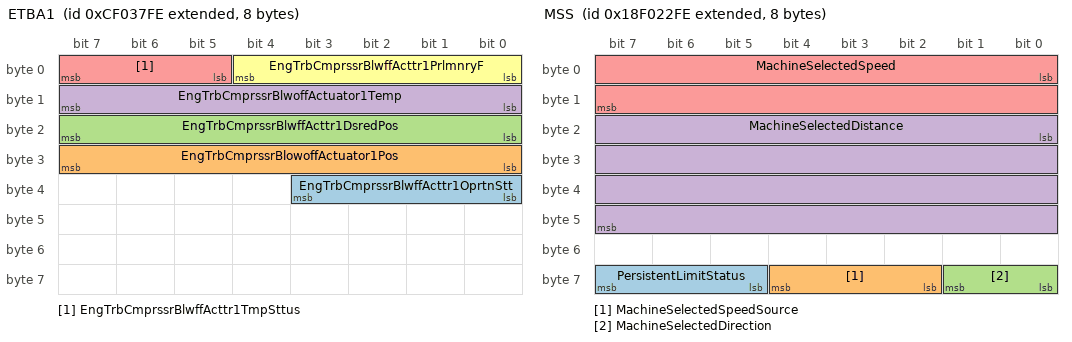
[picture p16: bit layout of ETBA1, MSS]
BO_ 2364553214 ETBA1: 8 Vector__XXX
 SG_ EngTrbCmprssrBlwffActtr1OprtnStt : 32|4@1+ (1,0) [0|15] "" Vector__XXX
 SG_ EngTrbCmprssrBlowoffActuator1Pos : 24|8@1+ (0.4,0) [0|100] "%" Vector__XXX
 SG_ EngTrbCmprssrBlwffActtr1DsredPos : 16|8@1+ (0.4,0) [0|100] "%" Vector__XXX
 SG_ EngTrbCmprssrBlwoffActuator1Temp : 8|8@1+ (1,-40) [-40|210] "°C" Vector__XXX
 SG_ EngTrbCmprssrBlwffActtr1TmpSttus : 5|3@1+ (1,0) [0|7] "" Vector__XXX
 SG_ EngTrbCmprssrBlwffActtr1PrlmnryF : 0|5@1+ (1,0) [0|31] "" Vector__XXX

BO_ 2565874430 MSS: 8 Vector__XXX
 SG_ PersistentLimitStatus : 61|3@1+ (1,0) [0|0] "" Vector__XXX
 SG_ MachineSelectedSpeedSource : 58|3@1+ (1,0) [0|0] "" Vector__XXX
 SG_ MachineSelectedDirection : 56|2@1+ (1,0) [0|0] "" Vector__XXX
 SG_ MachineSelectedDistance : 16|32@1+ (1,0) [0|0] "" Vector__XXX
 SG_ MachineSelectedSpeed : 0|16@1+ (1,0) [0|0] "" Vector__XXX

BO_ 2565873918 EBS25: 8 Vector__XXX

BO_ 2565873662 EBS26: 8 Vector__XXX

BO_ 2364546814 GC2: 8 Vector__XXX
 SG_ GeneratorGoverningBias : 0|16@1+ (0.004,-125) [-125|125] "%" Vector__XXX

BO_ 2565872638 GPM17: 8 Vector__XXX

BO_ 2565340926 VT21: 8 Vector__XXX

BO_ 2565275390 VT12: 8 Vector__XXX

BO_ 2566767614 EEC15: 8 Vector__XXX
 SG_ AccelPedal2Channel3 : 24|8@1+ (0.4,0) [0|100] "%" Vector__XXX
 SG_ AccelPedal2Channel2 : 16|8@1+ (0.4,0) [0|100] "%" Vector__XXX
 SG_ AccelPedal1Channel3 : 8|8@1+ (0.4,0) [0|100] "%" Vector__XXX
 SG_ AccelPedal1Channel2 : 0|8@1+ (0.4,0) [0|100] "%" Vector__XXX

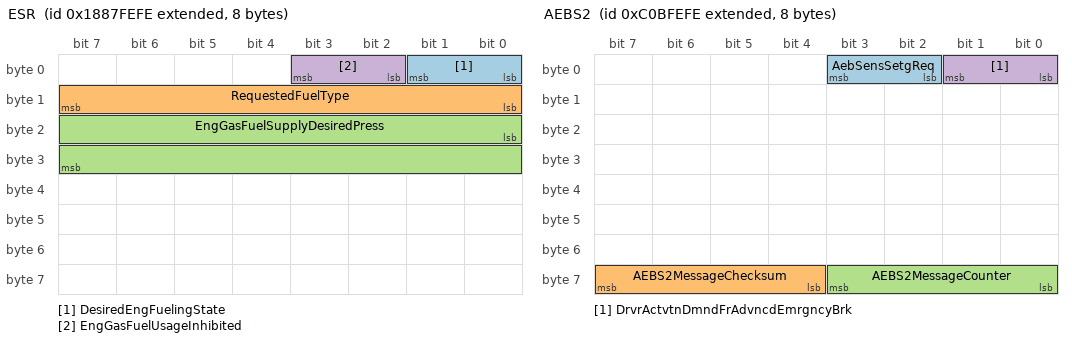
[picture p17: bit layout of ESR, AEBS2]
BO_ 2559049470 ESR: 8 Vector__XXX
 SG_ DesiredEngFuelingState : 0|2@1+ (1,0) [0|3] "" Vector__XXX
 SG_ RequestedFuelType : 8|8@1+ (1,0) [0|255] "" Vector__XXX
 SG_ EngGasFuelSupplyDesiredPress : 16|16@1+ (0.5,0) [0|32127.5] "kPa" Vector__XXX
 SG_ EngGasFuelUsageInhibited : 2|2@1+ (1,0) [0|3] "" Vector__XXX

BO_ 2349596414 AEBS2: 8 Vector__XXX
 SG_ AebSensSetgReq : 2|2@1+ (1,0) [0|3] "" Vector__XXX
 SG_ AEBS2MessageChecksum : 60|4@1+ (1,0) [0|15] "" Vector__XXX
 SG_ AEBS2MessageCounter : 56|4@1+ (1,0) [0|15] "" Vector__XXX
 SG_ DrvrActvtnDmndFrAdvncdEmrgncyBrk : 0|2@1+ (1,0) [0|3] "" Vector__XXX

BO_ 2563702526 KWP3: 8 Vector__XXX

BO_ 2563636990 KWP4: 8 Vector__XXX

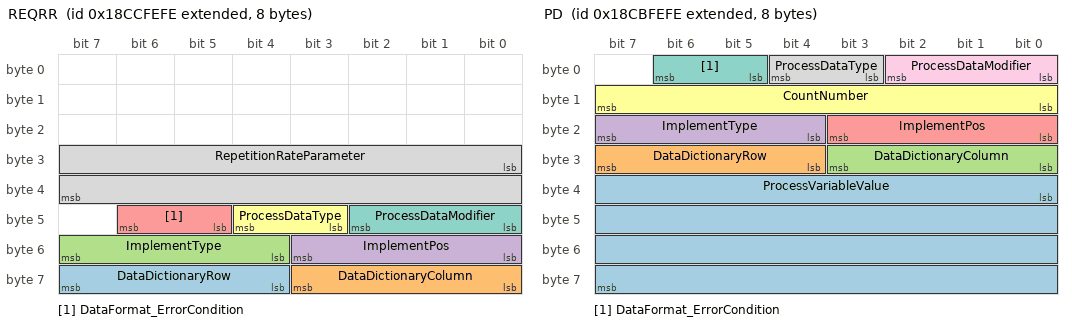
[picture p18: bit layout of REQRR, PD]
BO_ 2563571454 REQRR: 8 Vector__XXX
 SG_ DataDictionaryRow : 60|4@1+ (1,0) [0|0] "" Vector__XXX
 SG_ DataDictionaryColumn : 56|4@1+ (1,0) [0|0] "" Vector__XXX
 SG_ ImplementType : 52|4@1+ (1,0) [0|0] "" Vector__XXX
 SG_ ImplementPos : 48|4@1+ (1,0) [0|0] "" Vector__XXX
 SG_ DataFormat_ErrorCondition : 45|2@1+ (1,0) [0|0] "" Vector__XXX
 SG_ ProcessDataType : 43|2@1+ (1,0) [0|0] "" Vector__XXX
 SG_ ProcessDataModifier : 40|3@1+ (1,0) [0|0] "" Vector__XXX
 SG_ RepetitionRateParameter : 24|16@1+ (1,0) [0|0] "" Vector__XXX

BO_ 2563505918 PD: 8 Vector__XXX
 SG_ ProcessVariableValue : 32|32@1+ (1,0) [0|0] "" Vector__XXX
 SG_ DataDictionaryRow : 28|4@1+ (1,0) [0|0] "" Vector__XXX
 SG_ DataDictionaryColumn : 24|4@1+ (1,0) [0|0] "" Vector__XXX
 SG_ ImplementType : 20|4@1+ (1,0) [0|0] "" Vector__XXX
 SG_ ImplementPos : 16|4@1+ (1,0) [0|0] "" Vector__XXX
 SG_ CountNumber : 8|8@1+ (1,0) [0|0] "" Vector__XXX
 SG_ DataFormat_ErrorCondition : 5|2@1+ (1,0) [0|0] "" Vector__XXX
 SG_ ProcessDataType : 3|2@1+ (1,0) [0|0] "" Vector__XXX
 SG_ ProcessDataModifier : 0|3@1+ (1,0) [0|0] "" Vector__XXX

BO_ 2563309310 ETPCM: 8 Vector__XXX

BO_ 2563243774 ETPDT: 8 Vector__XXX

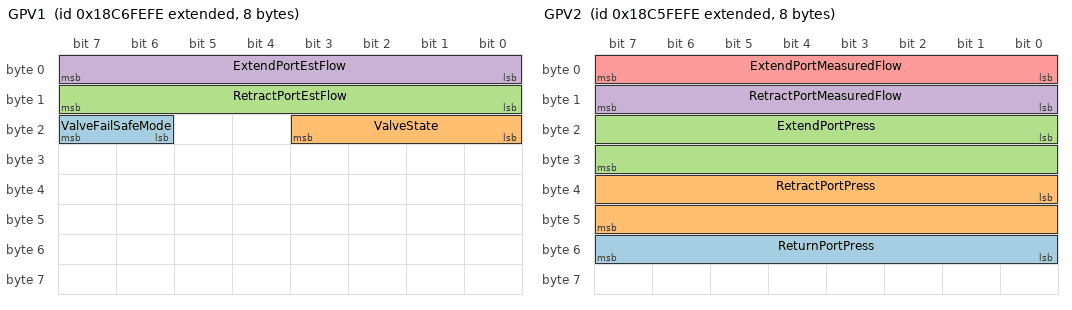
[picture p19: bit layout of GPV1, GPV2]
BO_ 2563178238 GPV1: 8 Vector__XXX
 SG_ ValveFailSafeMode : 22|2@1+ (1,0) [0|0] "" Vector__XXX
 SG_ ValveState : 16|4@1+ (1,0) [0|0] "" Vector__XXX
 SG_ RetractPortEstFlow : 8|8@1+ (1,0) [0|0] "" Vector__XXX
 SG_ ExtendPortEstFlow : 0|8@1+ (1,0) [0|0] "" Vector__XXX

BO_ 2563112702 GPV2: 8 Vector__XXX
 SG_ ReturnPortPress : 48|8@1+ (1,0) [0|0] "" Vector__XXX
 SG_ RetractPortPress : 32|16@1+ (1,0) [0|0] "" Vector__XXX
 SG_ ExtendPortPress : 16|16@1+ (1,0) [0|0] "" Vector__XXX
 SG_ RetractPortMeasuredFlow : 8|8@1+ (1,0) [0|0] "" Vector__XXX
 SG_ ExtendPortMeasuredFlow : 0|8@1+ (1,0) [0|0] "" Vector__XXX

BO_ 2563047166 GPV3: 8 Vector__XXX
 SG_ PortFlowCmd : 0|8@1+ (1,0) [0|0] "" Vector__XXX

BO_ 2562785022 PCM16: 8 Vector__XXX

BO_ 2562719486 PCM15: 8 Vector__XXX

BO_ 2562653950 PCM14: 8 Vector__XXX

BO_ 2562588414 PCM13: 8 Vector__XXX

BO_ 2562522878 PCM12: 8 Vector__XXX

BO_ 2562457342 PCM11: 8 Vector__XXX

BO_ 2562391806 PCM10: 8 Vector__XXX

BO_ 2562326270 PCM9: 8 Vector__XXX

BO_ 2562260734 PCM8: 8 Vector__XXX

BO_ 2562195198 PCM7: 8 Vector__XXX

BO_ 2562129662 PCM6: 8 Vector__XXX

BO_ 2562064126 PCM5: 8 Vector__XXX

BO_ 2561998590 PCM4: 8 Vector__XXX

BO_ 2561933054 PCM3: 8 Vector__XXX

BO_ 2561867518 PCM2: 8 Vector__XXX

BO_ 2561801982 PCM1: 8 Vector__XXX

BO_ 2561736446 CIM: 8 Vector__XXX

BO_ 2561670910 PLM: 8 Vector__XXX

BO_ 2561539838 GSC: 8 Vector__XXX

BO_ 2561474302 GMS: 8 Vector__XXX

BO_ 2561408766 FSC: 8 Vector__XXX

BO_ 2560294654 GPM18: 8 Vector__XXX

CM_ BO_ 2566692094 "Joystick 1 Lamp Status
Feedback message to report the actual status of lamps on Joystick 1";
CM_ SG_ 2566692094 Joystick1Lamp10Status "Report the actual value of Joystick 1 Lamp 10

00 - Off
01 - On
10 - Flashing
11 - Not available";
CM_ SG_ 2566692094 Joystick1Lamp9Status "Report the actual value of Joystick 1 Lamp 9

00 - Off
01 - On
10 - Flashing
11 - Not available";
CM_ SG_ 2566692094 Joystick1Lamp8Status "Report the actual value of Joystick 1 Lamp 8

00 - Off
01 - On
10 - Flashing
11 - Not available";
CM_ SG_ 2566692094 Joystick1Lamp7Status "Report the actual value of Joystick 1 Lamp 7

00 - Off
01 - On
10 - Flashing
11 - Not available";
CM_ SG_ 2566692094 Joystick1Lamp6Status "Report the actual value of Joystick 1 Lamp 6

00 - Off
01 - On
10 - Flashing
11 - Not available";
CM_ SG_ 2566692094 Joystick1Lamp5Status "Report the actual value of Joystick 1 Lamp 5

00 - Off
01 - On
10 - Flashing
11 - Not available";
CM_ SG_ 2566692094 Joystick1Lamp4Status "Report the actual value of Joystick 1 Lamp 4

00 - Off
01 - On
10 - Flashing
11 - Not available";
CM_ SG_ 2566692094 Joystick1Lamp3Status "Report the actual value of Joystick 1 Lamp 3

00 - Off
01 - On
10 - Flashing
11 - Not available";
CM_ SG_ 2566692094 Joystick1Lamp2Status "Report the actual value of Joystick 1 Lamp 2

00 - Off
01 - On
10 - Flashing
11 - Not available";
CM_ SG_ 2566692094 Joystick1Lamp1Status "Report the actual value of Joystick 1 Lamp 1

00 - Off
01 - On
10 - Flashing
11 - Not available";
CM_ BO_ 2566691838 "Joystick 2 Lamp Status
Feedback message to report the actual status of lamps on Joystick 2";
CM_ SG_ 2566691838 Joystick2Lamp10Status "Report the actual value of Joystick 2 Lamp 10

00 - Off
01 - On
10 - Flashing
11 - Not available";
CM_ SG_ 2566691838 Joystick2Lamp9Status "Report the actual value of Joystick 2 Lamp 9

00 - Off
01 - On
10 - Flashing
11 - Not available";
CM_ SG_ 2566691838 Joystick2Lamp8Status "Report the actual value of Joystick 2 Lamp 8

00 - Off
01 - On
10 - Flashing
11 - Not available";
CM_ SG_ 2566691838 Joystick2Lamp7Status "Report the actual value of Joystick 2 Lamp 7

00 - Off
01 - On
10 - Flashing
11 - Not available";
CM_ SG_ 2566691838 Joystick2Lamp6Status "Report the actual value of Joystick 2 Lamp 6

00 - Off
01 - On
10 - Flashing
11 - Not available";
CM_ SG_ 2566691838 Joystick2Lamp5Status "Report the actual value of Joystick 2 Lamp 5

00 - Off
01 - On
10 - Flashing
11 - Not available";
CM_ SG_ 2566691838 Joystick2Lamp4Status "Report the actual value of Joystick 2 Lamp 4

00 - Off
01 - On
10 - Flashing
11 - Not available";
CM_ SG_ 2566691838 Joystick2Lamp3Status "Report the actual value of Joystick 2 Lamp 3

00 - Off
01 - On
10 - Flashing
11 - Not available";
CM_ SG_ 2566691838 Joystick2Lamp2Status "Report the actual value of Joystick 2 Lamp 2

00 - Off
01 - On
10 - Flashing
11 - Not available";
CM_ SG_ 2566691838 Joystick2Lamp1Status "Report the actual value of Joystick 2 Lamp 1

00 - Off
01 - On
10 - Flashing
11 - Not available";
CM_ BO_ 2566691582 "Joystick 3 Lamp Status
Feedback message to report the actual status of lamps on Joystick 3";
CM_ SG_ 2566691582 Joystick3Lamp10Status "Report the actual value of Joystick 3 Lamp 10

00 - Off
01 - On
10 - Flashing
11 - Not available";
CM_ SG_ 2566691582 Joystick3Lamp9Status "Report the actual value of Joystick 3 Lamp 9

00 - Off
01 - On
10 - Flashing
11 - Not available";
CM_ SG_ 2566691582 Joystick3Lamp8Status "Report the actual value of Joystick 3 Lamp 8

00 - Off
01 - On
10 - Flashing
11 - Not available";
CM_ SG_ 2566691582 Joystick3Lamp7Status "Report the actual value of Joystick 3 Lamp 7

00 - Off
01 - On
10 - Flashing
11 - Not available";
CM_ SG_ 2566691582 Joystick3Lamp6Status "Report the actual value of Joystick 3 Lamp 6

00 - Off
01 - On
10 - Flashing
11 - Not available";
CM_ SG_ 2566691582 Joystick3Lamp5Status "Report the actual value of Joystick 3 Lamp 5

00 - Off
01 - On
10 - Flashing
11 - Not available";
CM_ SG_ 2566691582 Joystick3Lamp4Status "Report the actual value of Joystick 3 Lamp 4

00 - Off
01 - On
10 - Flashing
11 - Not available";
CM_ SG_ 2566691582 Joystick3Lamp3Status "Report the actual value of Joystick 3 Lamp 3

00 - Off
01 - On
10 - Flashing
11 - Not available";
CM_ SG_ 2566691582 Joystick3Lamp2Status "Report the actual value of Joystick 3 Lamp 2

00 - Off
01 - On
10 - Flashing
11 - Not available";
CM_ SG_ 2566691582 Joystick3Lamp1Status "Report the actual value of Joystick 3 Lamp 1

00 - Off
01 - On
10 - Flashing
11 - Not available";
CM_ BO_ 2566691326 "Assembly Unit Identification
Used to transmit the identification of the assemblies fitted onto a component.
NOTE - The assembly unit identification field is variable in length. An ASCII '*' is used as a delimiter to separate multiple ...";
CM_ SG_ 2566691326 AssemblyUnitIdentification "A combination of alphanumeric characters representing the Identification number of an assembly unit installed on a component.  Multiple assembly unit IDs can be transmitted by appropriately setting Number of Assembly Unit Identification Fields (SPN ...";
CM_ SG_ 2566691326 NmbrOfAssmblyUntIdntfctionFields "Number of Assembly Unit Identification designators represented in the Assembly Unit Identification parameter group.";
CM_ BO_ 2499582206 "Vehicle Speed Limiter
Vehicle speed limiter information, including Soft Top Speed Limit information";
CM_ SG_ 2499582206 SftTpSpdLmtRmnngCntnsIntrvlDstnc "Indicates the remaining distance that the vehicle can continuously travel at the Soft Top Speed Limit.  This parameter will decrement while the Soft Top Speed Limit Active (SPN 6370) is 1 and will reset to its maximum allowed value when the Soft Top ...";
CM_ SG_ 2499582206 SoftTopSpeedLimitResetDistance "This parameter will decrement as long as the vehicle is moving. When this parameter reaches 0, it will be reset to its maximum value and continue to decrement.";
CM_ SG_ 2499582206 SftTpSpeedLimitRemainingDistance "Indicates the remaining distance that the vehicle can travel at the Soft Top Speed Limit within the larger reset window. The reset window may be distance (possibly indicated by SPN 6373), time, or something else as determined by the manufacturer.
 ...";
CM_ SG_ 2499582206 SoftTopLifetimeLimitExceeded "Greenhouse Gas Regulations limit the overall distance that Soft Top Speed can be used in relation to the total distance traveled. This parameter indicates the allowable ratio has been exceeded and Soft Top Speed is unavailable. It will become ...";
CM_ SG_ 2499582206 SoftTopSpeedLimitActive "Indicates that the current Maximum Vehicle Speed Limit (SPN 74) has been temporarily increased to the Soft Top Speed Limit. Under certain conditions, the legal speed limit allowed by the Greenhouse Gas Regulations can be increased to a speed ...";
CM_ BO_ 2566690814 "Electronic Steering Control 2
Group containing parameters relevant to the electronic control of an all wheel steering system, allowing the selection and actuation of different steer modes";
CM_ SG_ 2566690814 CrabSteerModeActuatorState "Signal which indicates the current state of the actuator that control the crab steering mode

00 - Crab Steer Mode actuator inactive
01 - Crab Steer Mode actuator active
10 - Error
11 - Not Available";
CM_ SG_ 2566690814 CircleSteerModeActuatorState "Signal which indicates the current state of the actuator that control the circle steering mode

00 - Circle Steer Mode actuator inactive
01 - Circle Steer Mode actuator active
10 - Error
11 - Not Available";
CM_ SG_ 2566690814 VourWheelSteerActuatorState "Signal which indicates the current state of the actuator that control the 4 wheel steering mode

00 - 4 Wheel Steer actuator inactive
01 - 4 Wheel Steer actuator active
10 - Error
11 - Not Available";
CM_ SG_ 2566690814 TwoWheelSteerActuatorState "The current state of the actuator that control the 2 wheel steering mode

00 - 2 Wheel Steer actuator inactive
01 - 2 Wheel Steer actuator active
10 - Error
11 - Not Available";
CM_ SG_ 2566690814 RearSteerAxleCenteredStatus "The status of the rear steering axle being centered. The axle is centered if the axle's centerline is parallel to the vehicle's X-axis, where the vehicle's X-axis is as defined in SAE J670
00 - Rear Axle Centered
01 - Rear Axle Not Centered
10 - ...";
CM_ SG_ 2566690814 FrontSteerAxleCenteredStatus "The status of the front steering axle being centered. The axle is centered if the axle's centerline is parallel to the vehicle's X-axis, where the vehicle's X-axis is as defined in SAE J670
00 - Front Axle Centered
01 - Front Axle Not Centered
10 ...";
CM_ SG_ 2566690814 SteerModeSwitch "Switch used as an input to the electronic steering controller to determine the operator's requested steering mode
000 - 2 Wheel Steer Mode
001 - Circle Steer Mode
011 - Crab Steer Mode
100-101 - Reserved for future use
110 - Error
111 - Not ...";
CM_ BO_ 2566690558 "Engine Information 2
Second PGN conveying engine information.";
CM_ SG_ 2566690558 CommonRailOilAbsPress "Absolute pressure of oil in common rail's lubrication system as provided by oil pump.";
CM_ SG_ 2566690558 CommonRailOilPress "Gage pressure of oil in common rail's lubrication system as provided by oil pump.";
CM_ SG_ 2566690558 EngPreFilterOilPress "Gage pressure of the engine oil before the oil reaches the oil filter. See SPN 1208 for alternate resolution.";
CM_ SG_ 2566690558 EngExhaustPress1ExRange "Gage pressure of the exhaust gasses as measured at the turbine intake of the turbocharger. This SPN to be used for inline engines or exhaust bank 1 of multiple bank engines.  

See SPN 1209 for alternate resolution.";
CM_ BO_ 2365363710 "Engine Cylinder Pressure Monitor Status Information
Used to trasmit the status information of Cylinder Pressure Monitor Unit.";
CM_ SG_ 2365363710 EngCylPrssMonitor2PreliminaryFMI "Used to identify the applicable J1939-73 FMI detected in the Engine Cylinder Pressure Monitor 2.  When there is no failure FMI 31 is sent. In the case of multiple failures the most severe is communicated.";
CM_ SG_ 2365363710 EngCylPrssMonitor1PreliminaryFMI "Used to identify the applicable J1939-73 FMI detected in the Engine Cylinder Pressure Monitor 1.  When there is no failure FMI 31 is sent. In the case of multiple failures the most severe is communicated.";
CM_ BO_ 2566690046 "Aftertreatment System Abuse Information
Current status of aftertreatment system cooldown and purge routines.";
CM_ SG_ 2566690046 AfterrunCompleteThisCycle "Indication of after-run routine completion in the current power cycle.
'Complete This Cycle' parameters are used to indicate to the engine controller that is powering the aftertreatment controller via relay that it is ok to remove power.
00 - Not ...";
CM_ SG_ 2566690046 DEFDoserPurgeCompleteLastCycle "Indication of purge routine completion in the previous power cycle
00 - Not complete
01 - Complete
10 - Error
11 - Not Supported
Note:  One purpose for tracking the status of the Diesel Exhaust Fluid doser purge on the previous cycle is related ...";
CM_ SG_ 2566690046 DEFDoserPurgeCompleteThisCycle "Indication of purge routine completion in the current power cycle.
'Complete This Cycle' parameters are used to indicate to the engine controller that is powering the aftertreatment controller via relay that it is ok to remove power.
00 - Not ...";
CM_ SG_ 2566690046 DEFDoserCldnCompleteLastCycle "Indication of cooldown routine completion in the previous power cycle.
00 - Not complete
01 - Complete
10 - Error
11 - Not Supported
Note:  One purpose for tracking the status of the Diesel Exhaust Fluid doser purge on the previous cycle is ...";
CM_ SG_ 2566690046 DEFDoserCldnCompleteThisCycle "Indication of cooldown routine completion in the current power cycle.
'Complete This Cycle' parameters are used to indicate to the engine controller that is powering the aftertreatment controller via relay that it is ok to remove power.
00 - Not ...";
CM_ SG_ 2566690046 DEFDoserPurgeInterruptCount "Non-volatile record of the number of interrupted purge routines since the last clear event.  The counter shall be reset by PGN 56832 request.";
CM_ SG_ 2566690046 DEFDoserCldnInterruptCount "Non-volatile record of the number of interrupted cooldown routines since the last clear event.  The counter shall be reset by PGN 56832 request.";
CM_ BO_ 2566689790 "Gaseous Fuel Pressure 2
Information on Gas fuel pressure";
CM_ SG_ 2566689790 EngPrechamberFuelDesiredAbsPress "Desired absolute pressure of the gaseous fuel in the separate cylinder pre-chamber rail. This parameter is intended for applications with pre and main chamber fuel systems, which report the pressure of more than one type of fuel.";
CM_ SG_ 2566689790 EngPrechamberFuelAbsPress "Absolute pressure of the gaseous fuel for the separate cylinder pre-chamber rail. This parameter is intended for applications, which use a pre and main chamber fuel systems, which report the pressure of more than one type of fuel.";
CM_ SG_ 2566689790 EngMinChamberFuelDesiredAbsPress "Desired absolute pressure of the gaseous fuel for the main chamber of the cylinder. This parameter is intended for applications with pre and main chamber fuel systems, which report the pressure of more than one type of fuel.Engine";
CM_ SG_ 2566689790 EngMainChamberFuelAbsPress "Absolute pressure of the gaseous fuel for the main chamber of the cylinder. This parameter is intended for applications, which use a pre and main chamber fuel systems, which report the pressure of more than one type of fuel.";
CM_ BO_ 2566689534 "Air Fuel Ratio
This PGN provides Air Fuel Ratio Information";
CM_ SG_ 2566689534 EngPrechamberDesiredAirFuelRatio "Desired air to fuel ratio of the charge entering the cylinder prechamber.";
CM_ SG_ 2566689534 EngPrechamberAirFuelRatio "Actual air to fuel ratio of the charge entering the cylinder prechamber.";
CM_ SG_ 2566689534 EngMinChamberDesiredAirFuelRatio "Desired air to fuel ratio of the charge entering the cylinder main chamber.";
CM_ SG_ 2566689534 EngMainChamberAirFuelRatio "Actual air to fuel ratio of the charge entering the cylinder main chamber.";
CM_ BO_ 2566689278 "Engine Exhaust NOx
This PGN provides cumulative Exhaust NOx information for engines using multiple sensors.";
CM_ SG_ 2566689278 EngExhaustDesiredNOx "Desired NOx concentration in the engine exhaust, prior to any aftertreatment of the exhaust.";
CM_ SG_ 2566689278 EngExhaustNOx "Calculated NOx concentration for the total engine exhaust, prior to any aftertreatment of the exhaust.  This parameter is primarily intended for engines that have separate NOx sensors in separate exhaust manifolds, but the engine does not have an ...";
CM_ BO_ 2499580158 "Engine Fuel Injector Metering Rail Pressure Information 1
Used to transmit the rail pressure information as measured by different rail pressure sensors.";
CM_ SG_ 2499580158 EngInjectorMeteringRail2Press2 "The pressure of fuel measured by second rail pressure sensor in the metering rail 2 as delivered from the supply pump to the injector metering intake.
Note:  This is for the rail pressure from the 2nd rail pressure sensor.  This may be different ...";
CM_ SG_ 2499580158 EngInjectorMeteringRail2Press1 "The pressure of fuel measured by first rail pressure sensor in the metering rail 2 as delivered from the supply pump to the injector metering intake.
Note:  This is for the rail pressure from the 1st rail pressure sensor.  This may be different ...";
CM_ SG_ 2499580158 EngInjectorMeteringRail1Press2 "The pressure of fuel measured by the second rail pressure sensor in the primary, or first, metering rail as delivered from the supply pump to the injector metering intake.
Note:  This is for the rail pressure from the 2nd rail pressure sensor ...";
CM_ SG_ 2499580158 EngInjectorMeteringRail1Press1 "The pressure of fuel measured by first rail pressure sensor in the primary, or first, metering rail as delivered from the supply pump to the injector metering intake.
Note:  This is for the rail pressure from the 1st rail pressure sensor.  This may ...";
CM_ BO_ 2432471038 "Alternate Fuel 3";
CM_ SG_ 2432471038 GasFuelAccumulatorTemp "Gaseous fuel temperature at the outlet of the Gas Filter.";
CM_ SG_ 2432471038 EngFuelVaporizer1DischargeTemp "The temperature of the fuel in its gaseous state at the outlet of the first fuel vaporizer";
CM_ SG_ 2432471038 EngGasFuelSupplyPress "Pressure of gaseous fuel supply to fuel metering device in systems where the pressure range defined for SPN 159 is not sufficient.";
CM_ BO_ 2566688510 "Control Function Functionalities
This message identifies all the functionalities, functionality generation and functionality options, supported by this control function.";
CM_ BO_ 2566688254 "Product Identification Information
Used by a Control Function to provide information in which product the Control Function is mounted.";
CM_ SG_ 2566688254 ProductIdentificationModel "The Product Identification Model specifies a unique product within a Brand.

Examples of Models are:
For Electronic components: SG2600, BT, ICC 230.
For Balers: Big Baler 230AB, XC 130 CV.
For Sprayers: 238i, 1962i, Explorer D.
Etc.";
CM_ SG_ 2566688254 ProductIdentificationBrand "The Product Identification Brand specifies the brand of a product.
 
The combination of the Product Identification Code and the Product Identification Brand shall make the product unique in the world.";
CM_ SG_ 2566688254 ProductIdentificationCode "The Product Identification Code as assigned by the manufacturer corresponds with the identification number on the type plate of a product. For vehicles this number may be the same as the VIN (Vehicle Identification Number) . For stand alone systems ...";
CM_ BO_ 2364567038 "Engine Gaseous Fuel Valve Start of Actuation Command 5
Used to transmit the gaseous fuel valve start of activation command information for valve 17 to valve 20.";
CM_ SG_ 2364567038 EngGsFlVlve20StartOfActuationCmd "The angle, relative to the TDC of cylinder 20, with 0 being the TDC before the power stroke commences, at the which gaseous fuel valve 20 is activated to open.
Timings after TDC are referred with positive values and timings before TDC are referred ...";
CM_ SG_ 2364567038 EngGsFlVlve19StartOfActuationCmd "The angle, relative to the TDC of cylinder 19, with 0 being the TDC before the power stroke commences, at the which gaseous fuel valve 19 is activated to open.
Timings after TDC are referred with positive values and timings before TDC are referred ...";
CM_ SG_ 2364567038 EngGsFlVlve18StartOfActuationCmd "The angle, relative to the TDC of cylinder 18, with 0 being the TDC before the power stroke commences, at the which gaseous fuel valve 18 is activated to open.
Timings after TDC are referred with positive values and timings before TDC are referred ...";
CM_ SG_ 2364567038 EngGsFlVlve17StartOfActuationCmd "The angle, relative to the TDC of cylinder 17, with 0 being the TDC before the power stroke commences, at the which gaseous fuel valve 17 is activated to open.
Timings after TDC are referred with positive values and timings before TDC are referred ...";
CM_ BO_ 2364566782 "Engine Gaseous Fuel Valve Start of Actuation Command 4
Used to transmit the gaseous fuel valve start of activation command information for valve 13 to valve 16.";
CM_ SG_ 2364566782 EngGsFlVlve16StartOfActuationCmd "The angle, relative to the TDC of cylinder 16, with 0 being the TDC before the power stroke commences, at the which gaseous fuel valve 16 is activated to open.
Timings after TDC are referred with positive values and timings before TDC are referred ...";
CM_ SG_ 2364566782 EngGsFlVlve15StartOfActuationCmd "The angle, relative to the TDC of cylinder 15, with 0 being the TDC before the power stroke commences, at the which gaseous fuel valve 15 is activated to open.
Timings after TDC are referred with positive values and timings before TDC are referred ...";
CM_ SG_ 2364566782 EngGsFlVlve14StartOfActuationCmd "The angle, relative to the TDC of cylinder 14, with 0 being the TDC before the power stroke commences, at the which gaseous fuel valve 14 is activated to open.
Timings after TDC are referred with positive values and timings before TDC are referred ...";
CM_ SG_ 2364566782 EngGsFlVlve13StartOfActuationCmd "The angle, relative to the TDC of cylinder 13, with 0 being the TDC before the power stroke commences, at the which gaseous fuel valve 13 is activated to open.
Timings after TDC are referred with positive values and timings before TDC are referred ...";
CM_ BO_ 2364566526 "Engine Gaseous Fuel Valve Start of Actuation Command 3
Used to transmit the gaseous fuel valve start of activation command information for valve 9 to valve 12.";
CM_ SG_ 2364566526 EngGsFlVlve12StartOfActuationCmd "The angle, relative to the TDC of cylinder 12, with 0 being the TDC before the power stroke commences, at the which gaseous fuel valve 12 is activated to open.
Timings after TDC are referred with positive values and timings before TDC are referred ...";
CM_ SG_ 2364566526 EngGsFlVlve11StartOfActuationCmd "The angle, relative to the TDC of cylinder 11, with 0 being the TDC before the power stroke commences, at the which gaseous fuel valve 11 is activated to open.
Timings after TDC are referred with positive values and timings before TDC are referred ...";
CM_ SG_ 2364566526 EngGsFlVlve10StartOfActuationCmd "The angle, relative to the TDC of cylinder 10, with 0 being the TDC before the power stroke commences, at the which gaseous fuel valve 10 is activated to open.
Timings after TDC are referred with positive values and timings before TDC are referred ...";
CM_ SG_ 2364566526 EngGsFlValve9StartOfActuationCmd "The angle, relative to the TDC of cylinder 9, with 0 being the TDC before the power stroke commences, at the which gaseous fuel valve 9 is activated to open.
Timings after TDC are referred with positive values and timings before TDC are referred ...";
CM_ BO_ 2364566270 "Engine Gaseous Fuel Valve Start of Actuation Command 2
Used to transmit the gaseous fuel valve start of activation command information for valve 5 to valve 8.";
CM_ SG_ 2364566270 EngGsFlValve8StartOfActuationCmd "The angle, relative to the TDC of cylinder 8, with 0 being the TDC before the power stroke commences, at the which gaseous fuel valve 8 is activated to open.
Timings after TDC are referred with positive values and timings before TDC are referred ...";
CM_ SG_ 2364566270 EngGsFlValve7StartOfActuationCmd "The angle, relative to the TDC of cylinder 7, with 0 being the TDC before the power stroke commences, at the which gaseous fuel valve 7 is activated to open.
Timings after TDC are referred with positive values and timings before TDC are referred ...";
CM_ SG_ 2364566270 EngGsFlValve6StartOfActuationCmd "The angle, relative to the TDC of cylinder 6, with 0 being the TDC before the power stroke commences, at the which gaseous fuel valve 6 is activated to open.
Timings after TDC are referred with positive values and timings before TDC are referred ...";
CM_ SG_ 2364566270 EngGsFlValve5StartOfActuationCmd "The angle, relative to the TDC of cylinder 5, with 0 being the TDC before the power stroke commences, at the which gaseous fuel valve 5 is activated to open.
Timings after TDC are referred with positive values and timings before TDC are referred ...";
CM_ BO_ 2364566014 "Engine Gaseous Fuel Valve Start of Actuation Command 1
Used to transmit the gaseous fuel valve start of activation command information for valve 1 to valve 4.";
CM_ SG_ 2364566014 EngGsFlValve4StartOfActuationCmd "The angle, relative to the TDC of cylinder 4, with 0 being the TDC before the power stroke commences, at the which gaseous fuel valve 4 is activated to open.
Timings after TDC are referred with positive values and timings before TDC are referred ...";
CM_ SG_ 2364566014 EngGsFlValve3StartOfActuationCmd "The angle, relative to the TDC of cylinder 3, with 0 being the TDC before the power stroke commences, at the which gaseous fuel valve 3 is activated to open.
Timings after TDC are referred with positive values and timings before TDC are referred ...";
CM_ SG_ 2364566014 EngGsFlValve2StartOfActuationCmd "The angle, relative to the TDC of cylinder 2, with 0 being the TDC before the power stroke commences, at the which gaseous fuel valve 2 is activated to open.
Timings after TDC are referred with positive values and timings before TDC are referred ...";
CM_ SG_ 2364566014 EngGsFlValve1StartOfActuationCmd "The angle, relative to the TDC of cylinder 1, with 0 being the TDC before the power stroke commences, at the which gaseous fuel valve 1 is activated to open.
Timings after TDC are referred with positive values and timings before TDC are referred ...";
CM_ BO_ 2364565758 "Engine Gaseous Fuel Valve Duration Command 5
Used to transmit the gaseous fuel valve duration command information for valve 17 to valve 20.";
CM_ SG_ 2364565758 EngGasFuelValve20DurationCmd "Amount of time the gaseous fuel valve 20 is activated.";
CM_ SG_ 2364565758 EngGasFuelValve19DurationCmd "Amount of time the gaseous fuel valve 19 is activated.";
CM_ SG_ 2364565758 EngGasFuelValve18DurationCmd "Amount of time the gaseous fuel valve 18 is activated.";
CM_ SG_ 2364565758 EngGasFuelValve17DurationCmd "Amount of time the gaseous fuel valve 17 is activated.";
CM_ BO_ 2364565502 "Engine Gaseous Fuel Valve Duration Command 4
Used to transmit the gaseous fuel valve duration command information for valve 13 to valve 16.";
CM_ SG_ 2364565502 EngGasFuelValve16DurationCmd "Amount of time the gaseous fuel valve 16 is activated.";
CM_ SG_ 2364565502 EngGasFuelValve15DurationCmd "Amount of time the gaseous fuel valve 15 is activated.";
CM_ SG_ 2364565502 EngGasFuelValve14DurationCmd "Amount of time the gaseous fuel valve 14 is activated.";
CM_ SG_ 2364565502 EngGasFuelValve13DurationCmd "Amount of time the gaseous fuel valve 13 is activated.";
CM_ BO_ 2364565246 "Engine Gaseous Fuel Valve Duration Command 3
Used to transmit the gaseous fuel valve duration command information for valve 9 to valve 12.";
CM_ SG_ 2364565246 EngGasFuelValve12DurationCmd "Amount of time the gaseous fuel valve 12 is activated.";
CM_ SG_ 2364565246 EngGasFuelValve11DurationCmd "Amount of time the gaseous fuel valve 11 is activated.";
CM_ SG_ 2364565246 EngGasFuelValve10DurationCmd "Amount of time the gaseous fuel valve 10 is activated.";
CM_ SG_ 2364565246 EngGasFuelValve9DurationCmd "Amount of time the gaseous fuel valve 9 is activated.";
CM_ BO_ 2364564990 "Engine Gaseous Fuel Valve Duration Command 2
Used to transmit the gaseous fuel valve duration command information for valve 5 to valve 8.";
CM_ SG_ 2364564990 EngGasFuelValve8DurationCmd "Amount of time the gaseous fuel valve 8 is activated.";
CM_ SG_ 2364564990 EngGasFuelValve7DurationCmd "Amount of time the gaseous fuel valve 7 is activated.";
CM_ SG_ 2364564990 EngGasFuelValve6DurationCmd "Amount of time the gaseous fuel valve 6 is activated.";
CM_ SG_ 2364564990 EngGasFuelValve5DurationCmd "Amount of time the gaseous fuel valve 5 is activated.";
CM_ BO_ 2364564734 "Engine Gaseous Fuel Valve Duration Command 1
Used to transmit the gaseous fuel valve duration command information for valve 1 to valve 4.";
CM_ SG_ 2364564734 EngGasFuelValve4DurationCmd "Amount of time the gaseous fuel valve 4 is activated.";
CM_ SG_ 2364564734 EngGasFuelValve3DurationCmd "Amount of time the gaseous fuel valve 3 is activated.";
CM_ SG_ 2364564734 EngGasFuelValve2DurationCmd "Amount of time the gaseous fuel valve 2 is activated.";
CM_ SG_ 2364564734 EngGasFuelValve1DurationCmd "Amount of time the gaseous fuel valve 1 is activated.";
CM_ BO_ 2364564478 "Fuel Information 5 (Gaseous)
Used to transmit the gaseous fuel valve command information.";
CM_ SG_ 2364564478 EngGsFlVlvNmnlStrtOfActuationCmd "The angle, relative to the TDC of each cylinder, with 0 being the TDC before the power stroke commences, at the which gaseous fuel valves are activated to open.  It's a nominal value used for all the gaseous fuel valves in the engine.
Timings after ...";
CM_ SG_ 2364564478 EngGsFuelValveNominalDurationCmd "Amount of time the gaseous fuel valves are activated.  It's a nominal value used for all the gaseous fuel valves in the engine.

Note: Please see SPNs 6658 - 6677 for duration command for each gaseous fuel valves";
CM_ BO_ 2297455358 "Electronic Transmission Controller #12
Electronic Transmission Controller #12";
CM_ SG_ 2297455358 TransDirectionalOutputShaftSpeed "The rotational velocity and direction of the output shaft. Positive values are used for forward vehicle motion, negative values for reverse vehicle motion.

SPN 191 should be used when direction is not used.";
CM_ SG_ 2297455358 TransHydrostaticLoop2Press "Oil pressure in the transmission hydrostatic loop #2 between the pump and motor.";
CM_ SG_ 2297455358 TransHydrostaticLoop1Press "Oil pressure in the transmission hydrostatic loop #1 between the pump and motor.";
CM_ BO_ 2498781694 "Engine Cylinder 20 Combustion Average Information
Used to transmit the average of combustion parameters of Engine Cylinder 20.
This PGN is transmitted at a defined ratio of the engine speed. The transmission rate is dependent on
SPN 6394 - Number ...";
CM_ SG_ 2498781694 EngCyl20AvrageCombustionDuration "Average duration of combustion calculated over defined number of combustion cycles for engine cylinder 20 with reference to the crank angle.  Combustion duration is the difference between end of combustion and start of combustion expressed, in this ...";
CM_ SG_ 2498781694 EngCyl20AvrgCntrOfCmbstionTiming "Average timing calculated over defined number of combustion cycles for the center of combustion in engine cylinder 20 with reference to the crank angle.  Center of Combustion is used to indicate the combustion efficiency.  When the combustion ...";
CM_ SG_ 2498781694 EngCyl20AvrgStrtOfCmbstionTiming "Average start of combustion timing calculated over defined number of combustion cycles for engine cylinder 20 with reference to the crank angle.  When the combustion happens after the TDC (Top Dead Center) of this cylinder, the timing is referred in ...";
CM_ SG_ 2498781694 EngCyl20IndctdMeanEffectivePress "Average cylinder pressure calculated over defined number of combustion cycles for engine cylinder 20.  Negative range is to cover thermodynamic behavior during misfire.";
CM_ BO_ 2498781438 "Engine Cylinder 19 Combustion Average Information
Used to transmit the average of combustion parameters of Engine Cylinder 19.
This PGN is transmitted at a defined ratio of the engine speed. The transmission rate is dependent on
SPN 6394 - Number ...";
CM_ SG_ 2498781438 EngCyl19AvrageCombustionDuration "Average duration of combustion calculated over defined number of combustion cycles for engine cylinder 19 with reference to the crank angle.  Combustion duration is the difference between end of combustion and start of combustion expressed, in this ...";
CM_ SG_ 2498781438 EngCyl19AvrgCntrOfCmbstionTiming "Average timing calculated over defined number of combustion cycles for the center of combustion in engine cylinder 19 with reference to the crank angle.  Center of Combustion is used to indicate the combustion efficiency.  When the combustion ...";
CM_ SG_ 2498781438 EngCyl19AvrgStrtOfCmbstionTiming "Average start of combustion timing calculated over defined number of combustion cycles for engine cylinder 19 with reference to the crank angle.  When the combustion happens after the TDC (Top Dead Center) of this cylinder, the timing is referred in ...";
CM_ SG_ 2498781438 EngCyl19IndctdMeanEffectivePress "Average cylinder pressure calculated over defined number of combustion cycles for engine cylinder 19.  Negative range is to cover thermodynamic behavior during misfire.";
CM_ BO_ 2498781182 "Engine Cylinder 18 Combustion Average Information
Used to transmit the average of combustion parameters of Engine Cylinder 18.
This PGN is transmitted at a defined ratio of the engine speed. The transmission rate is dependent on
SPN 6394 - Number ...";
CM_ SG_ 2498781182 EngCyl18AvrageCombustionDuration "Average duration of combustion calculated over defined number of combustion cycles for engine cylinder 18 with reference to the crank angle.  Combustion duration is the difference between end of combustion and start of combustion expressed, in this ...";
CM_ SG_ 2498781182 EngCyl18AvrgCntrOfCmbstionTiming "Average timing calculated over defined number of combustion cycles for the center of combustion in engine cylinder 18 with reference to the crank angle.  Center of Combustion is used to indicate the combustion efficiency.  When the combustion ...";
CM_ SG_ 2498781182 EngCyl18AvrgStrtOfCmbstionTiming "Average start of combustion timing calculated over defined number of combustion cycles for engine cylinder 18 with reference to the crank angle.  When the combustion happens after the TDC (Top Dead Center) of this cylinder, the timing is referred in ...";
CM_ SG_ 2498781182 EngCyl18IndctdMeanEffectivePress "Average cylinder pressure calculated over defined number of combustion cycles for engine cylinder 18.  Negative range is to cover thermodynamic behavior during misfire.";
CM_ BO_ 2498780926 "Engine Cylinder 17 Combustion Average Information
Used to transmit the average of combustion parameters of Engine Cylinder 17.
This PGN is transmitted at a defined ratio of the engine speed. The transmission rate is dependent on
SPN 6394 - Number ...";
CM_ SG_ 2498780926 EngCyl17AvrageCombustionDuration "Average duration of combustion calculated over defined number of combustion cycles for engine cylinder 17 with reference to the crank angle.  Combustion duration is the difference between end of combustion and start of combustion expressed, in this ...";
CM_ SG_ 2498780926 EngCyl17AvrgCntrOfCmbstionTiming "Average timing calculated over defined number of combustion cycles for the center of combustion in engine cylinder 17 with reference to the crank angle.  Center of Combustion is used to indicate the combustion efficiency.  When the combustion ...";
CM_ SG_ 2498780926 EngCyl17AvrgStrtOfCmbstionTiming "Average start of combustion timing calculated over defined number of combustion cycles for engine cylinder 17 with reference to the crank angle.  When the combustion happens after the TDC (Top Dead Center) of this cylinder, the timing is referred in ...";
CM_ SG_ 2498780926 EngCyl17IndctdMeanEffectivePress "Average cylinder pressure calculated over defined number of combustion cycles for engine cylinder 17.  Negative range is to cover thermodynamic behavior during misfire.";
CM_ BO_ 2498780670 "Engine Cylinder 16 Combustion Average Information
Used to transmit the average of combustion parameters of Engine Cylinder 16.
This PGN is transmitted at a defined ratio of the engine speed. The transmission rate is dependent on
SPN 6394 - Number ...";
CM_ SG_ 2498780670 EngCyl16AvrageCombustionDuration "Average duration of combustion calculated over defined number of combustion cycles for engine cylinder 16 with reference to the crank angle.  Combustion duration is the difference between end of combustion and start of combustion expressed, in this ...";
CM_ SG_ 2498780670 EngCyl16AvrgCntrOfCmbstionTiming "Average timing calculated over defined number of combustion cycles for the center of combustion in engine cylinder 16 with reference to the crank angle.  Center of Combustion is used to indicate the combustion efficiency.  When the combustion ...";
CM_ SG_ 2498780670 EngCyl16AvrgStrtOfCmbstionTiming "Average start of combustion timing calculated over defined number of combustion cycles for engine cylinder 16 with reference to the crank angle.  When the combustion happens after the TDC (Top Dead Center) of this cylinder, the timing is referred in ...";
CM_ SG_ 2498780670 EngCyl16IndctdMeanEffectivePress "Average cylinder pressure calculated over defined number of combustion cycles for engine cylinder 16.  Negative range is to cover thermodynamic behavior during misfire.";
CM_ BO_ 2498780414 "Engine Cylinder 15 Combustion Average Information
Used to transmit the average of combustion parameters of Engine Cylinder 15.
This PGN is transmitted at a defined ratio of the engine speed. The transmission rate is dependent on
SPN 6394 - Number ...";
CM_ SG_ 2498780414 EngCyl15AvrageCombustionDuration "Average duration of combustion calculated over defined number of combustion cycles for engine cylinder 15 with reference to the crank angle.  Combustion duration is the difference between end of combustion and start of combustion expressed, in this ...";
CM_ SG_ 2498780414 EngCyl15AvrgCntrOfCmbstionTiming "Average timing calculated over defined number of combustion cycles for the center of combustion in engine cylinder 15 with reference to the crank angle.  Center of Combustion is used to indicate the combustion efficiency.  When the combustion ...";
CM_ SG_ 2498780414 EngCyl15AvrgStrtOfCmbstionTiming "Average start of combustion timing calculated over defined number of combustion cycles for engine cylinder 15 with reference to the crank angle.  When the combustion happens after the TDC (Top Dead Center) of this cylinder, the timing is referred in ...";
CM_ SG_ 2498780414 EngCyl15IndctdMeanEffectivePress "Average cylinder pressure calculated over defined number of combustion cycles for engine cylinder 15.  Negative range is to cover thermodynamic behavior during misfire.";
CM_ BO_ 2498780158 "Engine Cylinder 14 Combustion Average Information
Used to transmit the average of combustion parameters of Engine Cylinder 14.
This PGN is transmitted at a defined ratio of the engine speed. The transmission rate is dependent on
SPN 6394 - Number ...";
CM_ SG_ 2498780158 EngCyl14AvrageCombustionDuration "Average duration of combustion calculated over defined number of combustion cycles for engine cylinder 14 with reference to the crank angle.  Combustion duration is the difference between end of combustion and start of combustion expressed, in this ...";
CM_ SG_ 2498780158 EngCyl14AvrgCntrOfCmbstionTiming "Average timing calculated over defined number of combustion cycles for the center of combustion in engine cylinder 14 with reference to the crank angle.  Center of Combustion is used to indicate the combustion efficiency.  When the combustion ...";
CM_ SG_ 2498780158 EngCyl14AvrgStrtOfCmbstionTiming "Average start of combustion timing calculated over defined number of combustion cycles for engine cylinder 14 with reference to the crank angle.  When the combustion happens after the TDC (Top Dead Center) of this cylinder, the timing is referred in ...";
CM_ SG_ 2498780158 EngCyl14IndctdMeanEffectivePress "Average cylinder pressure calculated over defined number of combustion cycles for engine cylinder 14.  Negative range is to cover thermodynamic behavior during misfire.";
CM_ BO_ 2498779902 "Engine Cylinder 13 Combustion Average Information
Used to transmit the average of combustion parameters of Engine Cylinder 13.
This PGN is transmitted at a defined ratio of the engine speed. The transmission rate is dependent on
SPN 6394 - Number ...";
CM_ SG_ 2498779902 EngCyl13AvrageCombustionDuration "Average duration of combustion calculated over defined number of combustion cycles for engine cylinder 13 with reference to the crank angle.  Combustion duration is the difference between end of combustion and start of combustion expressed, in this ...";
CM_ SG_ 2498779902 EngCyl13AvrgCntrOfCmbstionTiming "Average timing calculated over defined number of combustion cycles for the center of combustion in engine cylinder 13 with reference to the crank angle.  Center of Combustion is used to indicate the combustion efficiency.  When the combustion ...";
CM_ SG_ 2498779902 EngCyl13AvrgStrtOfCmbstionTiming "Average start of combustion timing calculated over defined number of combustion cycles for engine cylinder 13 with reference to the crank angle.  When the combustion happens after the TDC (Top Dead Center) of this cylinder, the timing is referred in ...";
CM_ SG_ 2498779902 EngCyl13IndctdMeanEffectivePress "Average cylinder pressure calculated over defined number of combustion cycles for engine cylinder 13.  Negative range is to cover thermodynamic behavior during misfire.";
CM_ BO_ 2498779646 "Engine Cylinder 12 Combustion Average Information
Used to transmit the average of combustion parameters of Engine Cylinder 12.
This PGN is transmitted at a defined ratio of the engine speed. The transmission rate is dependent on
SPN 6394 - Number ...";
CM_ SG_ 2498779646 EngCyl12AvrageCombustionDuration "Average duration of combustion calculated over defined number of combustion cycles for engine cylinder 12 with reference to the crank angle.  Combustion duration is the difference between end of combustion and start of combustion expressed, in this ...";
CM_ SG_ 2498779646 EngCyl12AvrgCntrOfCmbstionTiming "Average timing calculated over defined number of combustion cycles for the center of combustion in engine cylinder 12 with reference to the crank angle.  Center of Combustion is used to indicate the combustion efficiency.  When the combustion ...";
CM_ SG_ 2498779646 EngCyl12AvrgStrtOfCmbstionTiming "Average start of combustion timing calculated over defined number of combustion cycles for engine cylinder 12 with reference to the crank angle.  When the combustion happens after the TDC (Top Dead Center) of this cylinder, the timing is referred in ...";
CM_ SG_ 2498779646 EngCyl12IndctdMeanEffectivePress "Average cylinder pressure calculated over defined number of combustion cycles for engine cylinder 12.  Negative range is to cover thermodynamic behavior during misfire.";
CM_ BO_ 2498779390 "Engine Cylinder 11 Combustion Average Information
Used to transmit the average of combustion parameters of Engine Cylinder 11.
This PGN is transmitted at a defined ratio of the engine speed. The transmission rate is dependent on
SPN 6394 - Number ...";
CM_ SG_ 2498779390 EngCyl11AvrageCombustionDuration "Average duration of combustion calculated over defined number of combustion cycles for engine cylinder 11 with reference to the crank angle.  Combustion duration is the difference between end of combustion and start of combustion expressed, in this ...";
CM_ SG_ 2498779390 EngCyl11AvrgCntrOfCmbstionTiming "Average timing calculated over defined number of combustion cycles for the center of combustion in engine cylinder 11 with reference to the crank angle.  Center of Combustion is used to indicate the combustion efficiency.  When the combustion ...";
CM_ SG_ 2498779390 EngCyl11AvrgStrtOfCmbstionTiming "Average start of combustion timing calculated over defined number of combustion cycles for engine cylinder 11 with reference to the crank angle.  When the combustion happens after the TDC (Top Dead Center) of this cylinder, the timing is referred in ...";
CM_ SG_ 2498779390 EngCyl11IndctdMeanEffectivePress "Average cylinder pressure calculated over defined number of combustion cycles for engine cylinder 11.  Negative range is to cover thermodynamic behavior during misfire.";
CM_ BO_ 2498779134 "Engine Cylinder 10 Combustion Average Information
Used to transmit the average of combustion parameters of Engine Cylinder 10.
This PGN is transmitted at a defined ratio of the engine speed. The transmission rate is dependent on
SPN 6394 - Number ...";
CM_ SG_ 2498779134 EngCyl10AvrageCombustionDuration "Average duration of combustion calculated over defined number of combustion cycles for engine cylinder 10 with reference to the crank angle.  Combustion duration is the difference between end of combustion and start of combustion expressed, in this ...";
CM_ SG_ 2498779134 EngCyl10AvrgCntrOfCmbstionTiming "Average timing calculated over defined number of combustion cycles for the center of combustion in engine cylinder 10 with reference to the crank angle.  Center of Combustion is used to indicate the combustion efficiency.  When the combustion ...";
CM_ SG_ 2498779134 EngCyl10AvrgStrtOfCmbstionTiming "Average start of combustion timing calculated over defined number of combustion cycles for engine cylinder 10 with reference to the crank angle.  When the combustion happens after the TDC (Top Dead Center) of this cylinder, the timing is referred in ...";
CM_ SG_ 2498779134 EngCyl10IndctdMeanEffectivePress "Average cylinder pressure calculated over defined number of combustion cycles for engine cylinder 10.  Negative range is to cover thermodynamic behavior during misfire.";
CM_ BO_ 2498778878 "Engine Cylinder 9 Combustion Average Information
Used to transmit the average of combustion parameters of Engine Cylinder 9.
This PGN is transmitted at a defined ratio of the engine speed. The transmission rate is dependent on
SPN 6394 - Number ...";
CM_ SG_ 2498778878 EngCyl9AverageCombustionDuration "Average duration of combustion calculated over defined number of combustion cycles for engine cylinder 9 with reference to the crank angle.  Combustion duration is the difference between end of combustion and start of combustion expressed, in this ...";
CM_ SG_ 2498778878 EngCyl9AvrgCntrOfCmbustionTiming "Average timing calculated over defined number of combustion cycles for the center of combustion in engine cylinder 9 with reference to the crank angle.  Center of Combustion is used to indicate the combustion efficiency.  When the combustion happens ...";
CM_ SG_ 2498778878 EngCyl9AvrgStrtOfCmbustionTiming "Average start of combustion timing calculated over defined number of combustion cycles for engine cylinder 9 with reference to the crank angle.  When the combustion happens after the TDC (Top Dead Center) of this cylinder, the timing is referred in ...";
CM_ SG_ 2498778878 EngCyl9IndctedMeanEffectivePress "Average cylinder pressure calculated over defined number of combustion cycles for engine cylinder 9.  Negative range is to cover thermodynamic behavior during misfire.";
CM_ BO_ 2566757118 "Electronic Brake System #2/4
Message to transmit data of the towed vehicle to the towing vehicle. See ISO 11992-3.";
CM_ BO_ 2559246078 "Running Gear Equipment #1/2
Message to transmit data of the towing vehicle to the towed vehicle. See ISO 11992-2.";
CM_ BO_ 2559180542 "Running Gear Equipment #2/4
Message to transmit data of the towed vehicle to the towing vehicle. See ISO 11992-2.";
CM_ BO_ 2365428734 "Generator Control 1
Message for the generator set control to change or report the status of the generator system.";
CM_ SG_ 2365428734 GenFrequencySelection "Command from user and/or generator control system for the genset (engine) to target operations for 50 Hz, 60 Hz, or 400 Hz.

0000 = 50 Hz
0001 = 60 Hz
0010 = 400 Hz
0011 - 1101 = SAE Reserved
1110 = Unknown
1111= Don't care /take no action";
CM_ SG_ 2365428734 GenGoverningSpeedCommand "Command from user and/or generator control system for the genset (engine) to govern to low idle or rated base speed setpoints.  If this method of engine control is used, then the PGN 0 (TSC1) is not expected to be received by the engine controller ...";
CM_ SG_ 2365428734 GenAlternatorEfficiency "Measured, calculated, and/or estimated operating efficiency of the generator alternator.  Percentage reflects ratio of power output divided by power input, multiplied by 100.";
CM_ SG_ 2365428734 GenNotReadyToAutoParaState "This parameter indicates whether or not all systems required to start the engine and close to the bus are prepared to operate automatically. If not, the generator is not ready to automatically parallel, and the status parameter is in the ACTIVE ...";
CM_ SG_ 2365428734 GenCtrlNotInAutoStartState "This parameter indicates whether or not the generator set is in a condition to automatically start up and provide power. If not, this status parameter is in the ACTIVE state.
00 = inactive (ready to start automatically)
01 = active (not ready to ...";
CM_ SG_ 2365428734 RequestedEngineControlMode "This parameter is used to request a change to the engine control mode.  This is a status parameter.
Bit state 0000 = Normal Engine Shutdown
Bit state 0001 = Rapid Engine Shutdown
Bit state 0010 = Emergency Engine Shutdown
Bit state 0011 = Normal ...";
CM_ SG_ 2365428734 EngSpeedGovernorDroop "This is the percent speed droop adjustment relative to rated speed setpoint. The Engine Speed Droop is equal to the following equation:
100*[(Engine Speed at no load - Engine Speed at full rated load)/ (Engine Speed at full rated load)].
The ...";
CM_ SG_ 2365428734 EngSpeedGovernorGainAdjust "This parameter is used to adjust multiple gains at same time to attain engine stability across a broader range of applications.  

-32128 is least responsive
0 is normal
+32127 is most responsive";
CM_ BO_ 2566702846 "OBD Information";
CM_ SG_ 2566702846 EngOBDWarmUpSequence "Engine warm-up as defined by the applicable region's regulatory agency.  In the US, 'Engine OBD Warm-up' or 'Warm-up cycle' means sufficient vehicle operation such that coolant temperature rises by at least 22.2 °C (40 °F) from engine starting and ...";
CM_ BO_ 2566703102 "Engine Emissions Certification Information";
CM_ SG_ 2566703102 CertificationEngineFamilyName "The regulated family name per the applicable region's certification agency.  For engines certified in the US, this shall be the 12-character engine family name or test group as defined by EPA.  Up to 200 characters may be used.  The characters are ...";
CM_ SG_ 2566703102 ModelYear "The compliance model year of the OBD system of the engine and or vehicle.  For example in the US, this is associated with either a vehicle model year or an engine model year, depending on how the emissions and OBD are certified.  This message shall ...";
CM_ BO_ 2566705918 "Previously Active Service Only DTCs";
CM_ SG_ 2566705918 DTC1 "Diagnostic Trouble Code";
CM_ SG_ 2566705918 FlashProtectLamp "This parameter provides the capability to flash the engine protect lamp


00 - Slow Flash (1 Hz, 50 % duty cycle)
01 - Fast Flash (2 Hz or faster, 50% duty cycle)
10 - Reserved
11 - Unavailable / Do Not Flash";
CM_ SG_ 2566705918 FlashAmberWarningLamp "This parameter provides the capability to flash the AWL

00 - Slow Flash (1 Hz, 50 % duty cycle)
01 - Fast Flash (2 Hz or faster, 50% duty cycle)
10 - Reserved
11 - Unavailable / Do Not Flash";
CM_ SG_ 2566705918 FlashRedStopLamp "This parameter provides the capability to flash the RSL


00 - Slow Flash (1 Hz, 50 % duty cycle)
01 - Fast Flash (2 Hz or faster, 50% duty cycle)
10 - Reserved
11 - Unavailable / Do Not Flash";
CM_ SG_ 2566705918 FlashMalfuncIndicatorLamp "This parameter provides the capability to flash the MIL
00 - Slow Flash (1 Hz, 50 % duty cycle)
01 - Fast Flash (2 Hz or faster, 50% duty cycle)
10 - Class C DTC
11 - Unavailable / Do Not Flash
Note:  State 10 is for WWH OBD discriminatory ...";
CM_ SG_ 2566705918 ProtectLampStatus "This lamp is used to relay trouble code information that is reporting a problem with a vehicle system that is most probably not electronic subsystem related. For instance, engine coolant temperature is exceeding its prescribed temperature range.
00 ...";
CM_ SG_ 2566705918 AmberWarningLampStatus "This lamp is used to relay trouble code information that is reporting a problem with the vehicle system but the vehicle need not be immediately stopped. 

00     Lamp Off
01     Lamp On
10     Reserved
11     Not available";
CM_ SG_ 2566705918 RedStopLampState "This lamp is used to relay trouble code information that is of a severe enough condition that it warrants stopping the vehicle.

00     Lamp Off
01     Lamp On
10     Reserved
11     Not available";
CM_ SG_ 2566705918 MalfunctionIndicatorLampStatus "A lamp used to relay only emissions-related trouble code information. This lamp is only illuminated when there is an emission-related trouble code active.
00     Lamp Off
01     Lamp On
10     Short MIL for WWH OBD
11     Not available
Note ...";
CM_ SG_ 2566705918 DTC5 "Diagnostic Trouble Code";
CM_ SG_ 2566705918 DTC4 "Diagnostic Trouble Code";
CM_ SG_ 2566705918 DTC3 "Diagnostic Trouble Code";
CM_ SG_ 2566705918 DTC2 "Diagnostic Trouble Code";
CM_ BO_ 2566705662 "Active Service Only DTCs";
CM_ SG_ 2566705662 DTC1 "Diagnostic Trouble Code";
CM_ SG_ 2566705662 FlashProtectLamp "This parameter provides the capability to flash the engine protect lamp


00 - Slow Flash (1 Hz, 50 % duty cycle)
01 - Fast Flash (2 Hz or faster, 50% duty cycle)
10 - Reserved
11 - Unavailable / Do Not Flash";
CM_ SG_ 2566705662 FlashAmberWarningLamp "This parameter provides the capability to flash the AWL

00 - Slow Flash (1 Hz, 50 % duty cycle)
01 - Fast Flash (2 Hz or faster, 50% duty cycle)
10 - Reserved
11 - Unavailable / Do Not Flash";
CM_ SG_ 2566705662 FlashRedStopLamp "This parameter provides the capability to flash the RSL


00 - Slow Flash (1 Hz, 50 % duty cycle)
01 - Fast Flash (2 Hz or faster, 50% duty cycle)
10 - Reserved
11 - Unavailable / Do Not Flash";
CM_ SG_ 2566705662 FlashMalfuncIndicatorLamp "This parameter provides the capability to flash the MIL
00 - Slow Flash (1 Hz, 50 % duty cycle)
01 - Fast Flash (2 Hz or faster, 50% duty cycle)
10 - Class C DTC
11 - Unavailable / Do Not Flash
Note:  State 10 is for WWH OBD discriminatory ...";
CM_ SG_ 2566705662 ProtectLampStatus "This lamp is used to relay trouble code information that is reporting a problem with a vehicle system that is most probably not electronic subsystem related. For instance, engine coolant temperature is exceeding its prescribed temperature range.
00 ...";
CM_ SG_ 2566705662 AmberWarningLampStatus "This lamp is used to relay trouble code information that is reporting a problem with the vehicle system but the vehicle need not be immediately stopped. 

00     Lamp Off
01     Lamp On
10     Reserved
11     Not available";
CM_ SG_ 2566705662 RedStopLampState "This lamp is used to relay trouble code information that is of a severe enough condition that it warrants stopping the vehicle.

00     Lamp Off
01     Lamp On
10     Reserved
11     Not available";
CM_ SG_ 2566705662 MalfunctionIndicatorLampStatus "A lamp used to relay only emissions-related trouble code information. This lamp is only illuminated when there is an emission-related trouble code active.
00     Lamp Off
01     Lamp On
10     Short MIL for WWH OBD
11     Not available
Note ...";
CM_ SG_ 2566705662 DTC5 "Diagnostic Trouble Code";
CM_ SG_ 2566705662 DTC4 "Diagnostic Trouble Code";
CM_ SG_ 2566705662 DTC3 "Diagnostic Trouble Code";
CM_ SG_ 2566705662 DTC2 "Diagnostic Trouble Code";
CM_ BO_ 2566706174 "Diagnostic Data Clear/Reset for All Service Only DTCs
All of the diagnostic information pertaining to the active service only diagnostic trouble codes and previously active diagnostic trouble codes should be erased as well as the DTCs.";
CM_ BO_ 2349465342 "Static Roll Angle Sensor Information
Contains Static Roll Angle Data and Status of the Static Roll Angle Sensor";
CM_ SG_ 2349465342 StaticRollAngleStatus "Status of the transmitted roll angle data.

000 = Sensor Busy
001 = Sensor OK
010 = Sensor Defect
011 = Sensor Reboots
100 = Angle Data Invalid
101 = Reserved
110 = Error
111 = Not available";
CM_ SG_ 2349465342 StaticRollAngle "The measured static roll angle between the vehicle y-axis and the ground plane about the X-axis.  The sign of the roll angle is determined in accordance to the right-hand rule about the X-axis, as specified in SAE J670.  Roll angle is the same for ...";
CM_ BO_ 2498777086 "Engine Cylinder 2 Combustion Average Information
Used to transmit the average of combustion parameters of Engine Cylinder 2.
This PGN is transmitted at a defined ratio of the engine speed. The transmission rate is dependent on
SPN 6394 - Number ...";
CM_ SG_ 2498777086 EngCyl2AverageCombustionDuration "Average duration of combustion calculated over defined number of combustion cycles for engine cylinder 2 with reference to the crank angle.  Combustion duration is the difference between end of combustion and start of combustion expressed, in this ...";
CM_ SG_ 2498777086 EngCyl2AvrgCntrOfCmbustionTiming "Average timing calculated over defined number of combustion cycles for the center of combustion in engine cylinder 2 with reference to the crank angle.  Center of Combustion is used to indicate the combustion efficiency.  When the combustion happens ...";
CM_ SG_ 2498777086 EngCyl2AvrgStrtOfCmbustionTiming "Average start of combustion timing calculated over defined number of combustion cycles for engine cylinder 2 with reference to the crank angle.  When the combustion happens after the TDC (Top Dead Center) of this cylinder, the timing is referred in ...";
CM_ SG_ 2498777086 EngCyl2IndctedMeanEffectivePress "Average cylinder pressure calculated over defined number of combustion cycles for engine cylinder 2.  Negative range is to cover thermodynamic behavior during misfire.";
CM_ BO_ 2498776830 "Engine Cylinder 1 Combustion Average Information
Used to transmit the average of combustion parameters of Engine Cylinder 1.
This PGN is transmitted at a defined ratio of the engine speed. The transmission rate is dependent on
SPN 6394 - Number ...";
CM_ SG_ 2498776830 EngCyl1AverageCombustionDuration "Average duration of combustion calculated over defined number of combustion cycles for engine cylinder 1 with reference to the crank angle.  Combustion duration is the difference between end of combustion and start of combustion expressed, in this ...";
CM_ SG_ 2498776830 EngCyl1AvrgCntrOfCmbustionTiming "Average timing calculated over defined number of combustion cycles for the center of combustion in engine cylinder 1 with reference to the crank angle.  Center of Combustion is used to indicate the combustion efficiency.  When the combustion happens ...";
CM_ SG_ 2498776830 EngCyl1AvrgStrtOfCmbustionTiming "Average start of combustion timing calculated over defined number of combustion cycles for engine cylinder 1 with reference to the crank angle.  When the combustion happens after the TDC (Top Dead Center) of this cylinder, the timing is referred in ...";
CM_ SG_ 2498776830 EngCyl1IndctedMeanEffectivePress "Average cylinder pressure calculated over defined number of combustion cycles for engine cylinder 1.   Negative range is to cover thermodynamic behavior during misfire.";
CM_ BO_ 2364558846 "Engine Cylinder 20 Combustion Information
Used to communicate combustion information of Engine Cylinder 20. The PGN is transmitted at the end of every combustion in Cylinder 20.";
CM_ SG_ 2364558846 MaxPressIncreaseRate "The maximum slope, in degrees of crank angle, of the pressure increase in engine cylinder 20 during the combustion cycle.";
CM_ SG_ 2364558846 LowFreqKnockLvl "Indicates the level of low frequency knock for engine cylinder 20. This knock occurs at frequencies below the typical knock level reported on SPNs 1371 & 6474.  The level of low frequency knock is reported using a relative scale where 0% is least ...";
CM_ SG_ 2364558846 EngCyl20PrssSensorPreliminaryFMI "Used to identify the applicable J1939-73 FMI detected in the engine cylinder 20 pressure sensor.  When there is no failure FMI 31 is sent. In the case of multiple failures the most severe is communicated.";
CM_ SG_ 2364558846 EngCyl20SynchronousKnockLevel "Used to indicate the level of knock for engine cylinder 20. The level of knock is reported using a relative scale where 0% is least level of knock, and increasing levels indicate more knock until 100% indicates the most severe level of knock allowed ...";
CM_ SG_ 2364558846 EngCyl20PeakPress "Peak pressure in engine cylinder 20 in combustion cycle.";
CM_ SG_ 2364558846 EngCyl20HeatRelease "The amount of heat produced during combustion in engine cylinder 20.  The negative range is to cover thermodynamic behavior during misfire.";
CM_ BO_ 2364558590 "Engine Cylinder 19 Combustion Information
Used to communicate combustion information of Engine Cylinder 19. The PGN is transmitted at the end of every combustion in Cylinder 19.";
CM_ SG_ 2364558590 MaxPressIncreaseRate "The maximum slope, in degrees of crank angle, of the pressure increase in engine cylinder 19 during the combustion cycle.";
CM_ SG_ 2364558590 LowFreqKnockLvl "Indicates the level of low frequency knock for engine cylinder 19. This knock occurs at frequencies below the typical knock level reported on SPNs 1370 & 6470.  The level of low frequency knock is reported using a relative scale where 0% is least ...";
CM_ SG_ 2364558590 EngCyl19PrssSensorPreliminaryFMI "Used to identify the applicable J1939-73 FMI detected in the engine cylinder 19 pressure sensor.  When there is no failure FMI 31 is sent. In the case of multiple failures the most severe is communicated.";
CM_ SG_ 2364558590 EngCyl19SynchronousKnockLevel "Used to indicate the level of knock for engine cylinder 19. The level of knock is reported using a relative scale where 0% is least level of knock, and increasing levels indicate more knock until 100% indicates the most severe level of knock allowed ...";
CM_ SG_ 2364558590 EngCyl19PeakPress "Peak pressure in engine cylinder 19 in combustion cycle.";
CM_ SG_ 2364558590 EngCyl19HeatRelease "The amount of heat produced during combustion in engine cylinder 19.  The negative range is to cover thermodynamic behavior during misfire.";
CM_ BO_ 2364558334 "Engine Cylinder 18 Combustion Information
Used to communicate combustion information of Engine Cylinder 18. The PGN is transmitted at the end of every combustion in Cylinder 18.";
CM_ SG_ 2364558334 MaxPressIncreaseRate "The maximum slope, in degrees of crank angle, of the pressure increase in engine cylinder 18 during the combustion cycle.";
CM_ SG_ 2364558334 LowFreqKnockLvl "Indicates the level of low frequency knock for engine cylinder 18. This knock occurs at frequencies below the typical knock level reported on SPNs 1369 & 6466.  The level of low frequency knock is reported using a relative scale where 0% is least ...";
CM_ SG_ 2364558334 EngCyl18PrssSensorPreliminaryFMI "Used to identify the applicable J1939-73 FMI detected in the engine cylinder 18 pressure sensor.  When there is no failure FMI 31 is sent. In the case of multiple failures the most severe is communicated.";
CM_ SG_ 2364558334 EngCyl18SynchronousKnockLevel "Used to indicate the level of knock for engine cylinder 18. The level of knock is reported using a relative scale where 0% is least level of knock, and increasing levels indicate more knock until 100% indicates the most severe level of knock allowed ...";
CM_ SG_ 2364558334 EngCyl18PeakPress "Peak pressure in engine cylinder 18 in combustion cycle.";
CM_ SG_ 2364558334 EngCyl18HeatRelease "The amount of heat produced during combustion in engine cylinder 18.  The negative range is to cover thermodynamic behavior during misfire.";
CM_ BO_ 2364558078 "Engine Cylinder 17 Combustion Information
Used to communicate combustion information of Engine Cylinder 17. The PGN is transmitted at the end of every combustion in Cylinder 17.";
CM_ SG_ 2364558078 MaxPressIncreaseRate "The maximum slope, in degrees of crank angle, of the pressure increase in engine cylinder 17 during the combustion cycle.";
CM_ SG_ 2364558078 LowFreqKnockLvl "Indicates the level of low frequency knock for engine cylinder 17. This knock occurs at frequencies below the typical knock level reported on SPNs 1368 & 6462.  The level of low frequency knock is reported using a relative scale where 0% is least ...";
CM_ SG_ 2364558078 EngCyl17PrssSensorPreliminaryFMI "Used to identify the applicable J1939-73 FMI detected in the engine cylinder 17 pressure sensor.  When there is no failure FMI 31 is sent. In the case of multiple failures the most severe is communicated.";
CM_ SG_ 2364558078 EngCyl17SynchronousKnockLevel "Used to indicate the level of knock for engine cylinder 17. The level of knock is reported using a relative scale where 0% is least level of knock, and increasing levels indicate more knock until 100% indicates the most severe level of knock allowed ...";
CM_ SG_ 2364558078 EngCyl17PeakPress "Peak pressure in engine cylinder 17 in combustion cycle.";
CM_ SG_ 2364558078 EngCyl17HeatRelease "The amount of heat produced during combustion in engine cylinder 17.  The negative range is to cover thermodynamic behavior during misfire.";
CM_ BO_ 2364557822 "Engine Cylinder 16 Combustion Information
Used to communicate combustion information of Engine Cylinder 16. The PGN is transmitted at the end of every combustion in Cylinder 16.";
CM_ SG_ 2364557822 MaxPressIncreaseRate "The maximum slope, in degrees of crank angle, of the pressure increase in engine cylinder 16 during the combustion cycle.";
CM_ SG_ 2364557822 LowFreqKnockLvl "Indicates the level of low frequency knock for engine cylinder 16. This knock occurs at frequencies below the typical knock level reported on SPNs 1367 & 6458.  The level of low frequency knock is reported using a relative scale where 0% is least ...";
CM_ SG_ 2364557822 EngCyl16PrssSensorPreliminaryFMI "Used to identify the applicable J1939-73 FMI detected in the engine cylinder 16 pressure sensor.  When there is no failure FMI 31 is sent. In the case of multiple failures the most severe is communicated.";
CM_ SG_ 2364557822 EngCyl16SynchronousKnockLevel "Used to indicate the level of knock for engine cylinder 16. The level of knock is reported using a relative scale where 0% is least level of knock, and increasing levels indicate more knock until 100% indicates the most severe level of knock allowed ...";
CM_ SG_ 2364557822 EngCyl16PeakPress "Peak pressure in engine cylinder 16 in combustion cycle.";
CM_ SG_ 2364557822 EngCyl16HeatRelease "The amount of heat produced during combustion in engine cylinder 16.  The negative range is to cover thermodynamic behavior during misfire.";
CM_ BO_ 2364557566 "Engine Cylinder 15 Combustion Information
Used to communicate combustion information of Engine Cylinder 15. The PGN is transmitted at the end of every combustion in Cylinder 15.";
CM_ SG_ 2364557566 MaxPressIncreaseRate "The maximum slope, in degrees of crank angle, of the pressure increase in engine cylinder 15 during the combustion cycle.";
CM_ SG_ 2364557566 LowFreqKnockLvl "Indicates the level of low frequency knock for engine cylinder 15. This knock occurs at frequencies below the typical knock level reported on SPNs 1366 & 6454.  The level of low frequency knock is reported using a relative scale where 0% is least ...";
CM_ SG_ 2364557566 EngCyl15PrssSensorPreliminaryFMI "Used to identify the applicable J1939-73 FMI detected in the engine cylinder 15 pressure sensor.  When there is no failure FMI 31 is sent. In the case of multiple failures the most severe is communicated.";
CM_ SG_ 2364557566 EngCyl15SynchronousKnockLevel "Used to indicate the level of knock for engine cylinder 15. The level of knock is reported using a relative scale where 0% is least level of knock, and increasing levels indicate more knock until 100% indicates the most severe level of knock allowed ...";
CM_ SG_ 2364557566 EngCyl15PeakPress "Peak pressure in engine cylinder 15 in combustion cycle.";
CM_ SG_ 2364557566 EngCyl15HeatRelease "The amount of heat produced during combustion in engine cylinder 15.  The negative range is to cover thermodynamic behavior during misfire.";
CM_ BO_ 2364557310 "Engine Cylinder 14 Combustion Information
Used to communicate combustion information of Engine Cylinder 14. The PGN is transmitted at the end of every combustion in Cylinder 14.";
CM_ SG_ 2364557310 MaxPressIncreaseRate "The maximum slope, in degrees of crank angle, of the pressure increase in engine cylinder 14 during the combustion cycle.";
CM_ SG_ 2364557310 LowFreqKnockLvl "Indicates the level of low frequency knock for engine cylinder 14. This knock occurs at frequencies below the typical knock level reported on SPNs 1365 & 6450.  The level of low frequency knock is reported using a relative scale where 0% is least ...";
CM_ SG_ 2364557310 EngCyl14PrssSensorPreliminaryFMI "Used to identify the applicable J1939-73 FMI detected in the engine cylinder 14 pressure sensor.  When there is no failure FMI 31 is sent. In the case of multiple failures the most severe is communicated.";
CM_ SG_ 2364557310 EngCyl14SynchronousKnockLevel "Used to indicate the level of knock for engine cylinder 14. The level of knock is reported using a relative scale where 0% is least level of knock, and increasing levels indicate more knock until 100% indicates the most severe level of knock allowed ...";
CM_ SG_ 2364557310 EngCyl14PeakPress "Peak pressure in engine cylinder 14 in combustion cycle.";
CM_ SG_ 2364557310 EngCyl14HeatRelease "The amount of heat produced during combustion in engine cylinder 14.  The negative range is to cover thermodynamic behavior during misfire.";
CM_ BO_ 2364557054 "Engine Cylinder 13 Combustion Information
Used to communicate combustion information of Engine Cylinder 13. The PGN is transmitted at the end of every combustion in Cylinder 13.";
CM_ SG_ 2364557054 MaxPressIncreaseRate "The maximum slope, in degrees of crank angle, of the pressure increase in engine cylinder 13 during the combustion cycle.";
CM_ SG_ 2364557054 LowFreqKnockLvl "Indicates the level of low frequency knock for engine cylinder 13. This knock occurs at frequencies below the typical knock level reported on SPNs 1364 & 6446.  The level of low frequency knock is reported using a relative scale where 0% is least ...";
CM_ SG_ 2364557054 EngCyl13PrssSensorPreliminaryFMI "Used to identify the applicable J1939-73 FMI detected in the engine cylinder 13 pressure sensor.  When there is no failure FMI 31 is sent. In the case of multiple failures the most severe is communicated.";
CM_ SG_ 2364557054 EngCyl13SynchronousKnockLevel "Used to indicate the level of knock for engine cylinder 13. The level of knock is reported using a relative scale where 0% is least level of knock, and increasing levels indicate more knock until 100% indicates the most severe level of knock allowed ...";
CM_ SG_ 2364557054 EngCyl13PeakPress "Peak pressure in engine cylinder 13 in combustion cycle.";
CM_ SG_ 2364557054 EngCyl13HeatRelease "The amount of heat produced during combustion in engine cylinder 13.  The negative range is to cover thermodynamic behavior during misfire.";
CM_ BO_ 2364556798 "Engine Cylinder 12 Combustion Information
Used to communicate combustion information of Engine Cylinder 12. The PGN is transmitted at the end of every combustion in Cylinder 12.";
CM_ SG_ 2364556798 MaxPressIncreaseRate "The maximum slope, in degrees of crank angle, of the pressure increase in engine cylinder 12 during the combustion cycle.";
CM_ SG_ 2364556798 LowFreqKnockLvl "Indicates the level of low frequency knock for engine cylinder 12. This knock occurs at frequencies below the typical knock level reported on SPNs 1363 & 6442.  The level of low frequency knock is reported using a relative scale where 0% is least ...";
CM_ SG_ 2364556798 EngCyl12PrssSensorPreliminaryFMI "Used to identify the applicable J1939-73 FMI detected in the engine cylinder 12 pressure sensor.  When there is no failure FMI 31 is sent. In the case of multiple failures the most severe is communicated.";
CM_ SG_ 2364556798 EngCyl12SynchronousKnockLevel "Used to indicate the level of knock for engine cylinder 12. The level of knock is reported using a relative scale where 0% is least level of knock, and increasing levels indicate more knock until 100% indicates the most severe level of knock allowed ...";
CM_ SG_ 2364556798 EngCyl12PeakPress "Peak pressure in engine cylinder 12 in combustion cycle.";
CM_ SG_ 2364556798 EngCyl12HeatRelease "The amount of heat produced during combustion in engine cylinder 12.  The negative range is to cover thermodynamic behavior during misfire.";
CM_ BO_ 2364556542 "Engine Cylinder 11 Combustion Information
Used to communicate combustion information of Engine Cylinder 11. The PGN is transmitted at the end of every combustion in Cylinder 11.";
CM_ SG_ 2364556542 MaxPressIncreaseRate "The maximum slope, in degrees of crank angle, of the pressure increase in engine cylinder 11 during the combustion cycle.";
CM_ SG_ 2364556542 LowFreqKnockLvl "Indicates the level of low frequency knock for engine cylinder 11. This knock occurs at frequencies below the typical knock level reported on SPNs 1362 & 6438.  The level of low frequency knock is reported using a relative scale where 0% is least ...";
CM_ SG_ 2364556542 EngCyl11PrssSensorPreliminaryFMI "Used to identify the applicable J1939-73 FMI detected in the engine cylinder 11 pressure sensor.  When there is no failure FMI 31 is sent. In the case of multiple failures the most severe is communicated.";
CM_ SG_ 2364556542 EngCyl11SynchronousKnockLevel "Used to indicate the level of knock for engine cylinder 11. The level of knock is reported using a relative scale where 0% is least level of knock, and increasing levels indicate more knock until 100% indicates the most severe level of knock allowed ...";
CM_ SG_ 2364556542 EngCyl11PeakPress "Peak pressure in engine cylinder 11 in combustion cycle.";
CM_ SG_ 2364556542 EngCyl11HeatRelease "The amount of heat produced during combustion in engine cylinder 11.  The negative range is to cover thermodynamic behavior during misfire.";
CM_ BO_ 2364556286 "Engine Cylinder 10 Combustion Information
Used to communicate combustion information of Engine Cylinder 10. The PGN is transmitted at the end of every combustion in Cylinder 10.";
CM_ SG_ 2364556286 MaxPressIncreaseRate "The maximum slope, in degrees of crank angle, of the pressure increase in engine cylinder 10 during the combustion cycle.";
CM_ SG_ 2364556286 LowFreqKnockLvl "Indicates the level of low frequency knock for engine cylinder 10. This knock occurs at frequencies below the typical knock level reported on SPNs 1361 & 6434.  The level of low frequency knock is reported using a relative scale where 0% is least ...";
CM_ SG_ 2364556286 EngCyl10PrssSensorPreliminaryFMI "Used to identify the applicable J1939-73 FMI detected in the engine cylinder 10 pressure sensor.  When there is no failure FMI 31 is sent. In the case of multiple failures the most severe is communicated.";
CM_ SG_ 2364556286 EngCyl10SynchronousKnockLevel "Used to indicate the level of knock for engine cylinder 10. The level of knock is reported using a relative scale where 0% is least level of knock, and increasing levels indicate more knock until 100% indicates the most severe level of knock allowed ...";
CM_ SG_ 2364556286 EngCyl10PeakPress "Peak pressure in engine cylinder 10 in combustion cycle.";
CM_ SG_ 2364556286 EngCyl10HeatRelease "The amount of heat produced during combustion in engine cylinder 10.  The negative range is to cover thermodynamic behavior during misfire.";
CM_ BO_ 2364556030 "Engine Cylinder 9 Combustion Information
Used to communicate combustion information of Engine Cylinder 9. The PGN is transmitted at the end of every combustion in Cylinder 9.";
CM_ SG_ 2364556030 MaxPressIncreaseRate "The maximum slope, in degrees of crank angle, of the pressure increase in engine cylinder 9 during the combustion cycle.";
CM_ SG_ 2364556030 LowFreqKnockLvl "Indicates the level of low frequency knock for engine cylinder 9. This knock occurs at frequencies below the typical knock level reported on SPNs 1360 & 6430.  The level of low frequency knock is reported using a relative scale where 0% is least ...";
CM_ SG_ 2364556030 EngCyl9PressSensorPreliminaryFMI "Used to identify the applicable J1939-73 FMI detected in the engine cylinder 9 pressure sensor.  When there is no failure FMI 31 is sent. In the case of multiple failures the most severe is communicated.";
CM_ SG_ 2364556030 EngCyl9SynchronousKnockLevel "Used to indicate the level of knock for engine cylinder 9. The level of knock is reported using a relative scale where 0% is least level of knock, and increasing levels indicate more knock until 100% indicates the most severe level of knock allowed ...";
CM_ SG_ 2364556030 EngCyl9PeakPress "Peak pressure in engine cylinder 9 in combustion cycle.";
CM_ SG_ 2364556030 EngCyl9HeatRelease "The amount of heat produced during combustion in engine cylinder 9.  The negative range is to cover thermodynamic behavior during misfire.";
CM_ BO_ 2364555774 "Engine Cylinder 8 Combustion Information
Used to communicate combustion information of Engine Cylinder 8. The PGN is transmitted at the end of every combustion in Cylinder 8.";
CM_ SG_ 2364555774 MaxPressIncreaseRate "The maximum slope, in degrees of crank angle, of the pressure increase in engine cylinder 8 during the combustion cycle.";
CM_ SG_ 2364555774 LowFreqKnockLvl "Indicates the level of low frequency knock for engine cylinder 8. This knock occurs at frequencies below the typical knock level reported on SPNs 1359 & 6426.  The level of low frequency knock is reported using a relative scale where 0% is least ...";
CM_ SG_ 2364555774 EngCyl8PressSensorPreliminaryFMI "Used to identify the applicable J1939-73 FMI detected in the engine cylinder 8 pressure sensor.  When there is no failure FMI 31 is sent. In the case of multiple failures the most severe is communicated.";
CM_ SG_ 2364555774 EngCyl8SynchronousKnockLevel "Used to indicate the level of knock for engine cylinder 8. The level of knock is reported using a relative scale where 0% is least level of knock, and increasing levels indicate more knock until 100% indicates the most severe level of knock allowed ...";
CM_ SG_ 2364555774 EngCyl8PeakPress "Peak pressure in engine cylinder 8 in combustion cycle.";
CM_ SG_ 2364555774 EngCyl8HeatRelease "The amount of heat produced during combustion in engine cylinder 8.  The negative range is to cover thermodynamic behavior during misfire.";
CM_ BO_ 2364555518 "Engine Cylinder 7 Combustion Information
Used to communicate combustion information of Engine Cylinder 7. The PGN is transmitted at the end of every combustion in Cylinder 7.";
CM_ SG_ 2364555518 MaxPressIncreaseRate "The maximum slope, in degrees of crank angle, of the pressure increase in engine cylinder 7 during the combustion cycle.";
CM_ SG_ 2364555518 LowFreqKnockLvl "Indicates the level of low frequency knock for engine cylinder 7. This knock occurs at frequencies below the typical knock level reported on SPNs 1358 & 6422.  The level of low frequency knock is reported using a relative scale where 0% is least ...";
CM_ SG_ 2364555518 EngCyl7PressSensorPreliminaryFMI "Used to identify the applicable J1939-73 FMI detected in the engine cylinder 7 pressure sensor.  When there is no failure FMI 31 is sent. In the case of multiple failures the most severe is communicated.";
CM_ SG_ 2364555518 EngCyl7SynchronousKnockLevel "Used to indicate the level of knock for engine cylinder 7. The level of knock is reported using a relative scale where 0% is least level of knock, and increasing levels indicate more knock until 100% indicates the most severe level of knock allowed ...";
CM_ SG_ 2364555518 EngCyl7PeakPress "Peak pressure in engine cylinder 7 in combustion cycle.";
CM_ SG_ 2364555518 EngCyl7HeatRelease "The amount of heat produced during combustion in engine cylinder 7.  The negative range is to cover thermodynamic behavior during misfire.";
CM_ BO_ 2364555262 "Engine Cylinder 6 Combustion Information
Used to communicate combustion information of Engine Cylinder 6. The PGN is transmitted at the end of every combustion in Cylinder 6.";
CM_ SG_ 2364555262 MaxPressIncreaseRate "The maximum slope, in degrees of crank angle, of the pressure increase in engine cylinder 6 during the combustion cycle.";
CM_ SG_ 2364555262 LowFreqKnockLvl "Indicates the level of low frequency knock for engine cylinder 6. This knock occurs at frequencies below the typical knock level reported on SPNs 1357 & 6418.  The level of low frequency knock is reported using a relative scale where 0% is least ...";
CM_ SG_ 2364555262 EngCyl6PressSensorPreliminaryFMI "Used to identify the applicable J1939-73 FMI detected in the engine cylinder 6 pressure sensor.  When there is no failure FMI 31 is sent. In the case of multiple failures the most severe is communicated.";
CM_ SG_ 2364555262 EngCyl6SynchronousKnockLevel "Used to indicate the level of knock for engine cylinder 6. The level of knock is reported using a relative scale where 0% is least level of knock, and increasing levels indicate more knock until 100% indicates the most severe level of knock allowed ...";
CM_ SG_ 2364555262 EngCyl6PeakPress "Peak pressure in engine cylinder 6 in combustion cycle.";
CM_ SG_ 2364555262 EngCyl6HeatRelease "The amount of heat produced during combustion in engine cylinder 6.  The negative range is to cover thermodynamic behavior during misfire.";
CM_ BO_ 2364555006 "Engine Cylinder 5 Combustion Information
Used to communicate combustion information of Engine Cylinder 5. The PGN is transmitted at the end of every combustion in Cylinder 5.";
CM_ SG_ 2364555006 MaxPressIncreaseRate "The maximum slope, in degrees of crank angle, of the pressure increase in engine cylinder 5 during the combustion cycle.";
CM_ SG_ 2364555006 LowFreqKnockLvl "Indicates the level of low frequency knock for engine cylinder 5. This knock occurs at frequencies below the typical knock level reported on SPNs 1356 & 6414.  The level of low frequency knock is reported using a relative scale where 0% is least ...";
CM_ SG_ 2364555006 EngCyl5PressSensorPreliminaryFMI "Used to identify the applicable J1939-73 FMI detected in the engine cylinder 5 pressure sensor.  When there is no failure FMI 31 is sent. In the case of multiple failures the most severe is communicated.";
CM_ SG_ 2364555006 EngCyl5SynchronousKnockLevel "Used to indicate the level of knock for engine cylinder 6. The level of knock is reported using a relative scale where 0% is least level of knock, and increasing levels indicate more knock until 100% indicates the most severe level of knock allowed ...";
CM_ SG_ 2364555006 EngCyl5PeakPress "Peak pressure in engine cylinder 5 in combustion cycle.";
CM_ SG_ 2364555006 EngCyl5HeatRelease "The amount of heat produced during combustion in engine cylinder 5.  The negative range is to cover thermodynamic behavior during misfire.";
CM_ BO_ 2364554750 "Engine Cylinder 4 Combustion Information
Used to communicate combustion information of Engine Cylinder 4. The PGN is transmitted at the end of every combustion in Cylinder 4.";
CM_ SG_ 2364554750 MaxPressIncreaseRate "The maximum slope, in degrees of crank angle, of the pressure increase in engine cylinder 4 during the combustion cycle.";
CM_ SG_ 2364554750 LowFreqKnockLvl "Indicates the level of low frequency knock for engine cylinder 4. This knock occurs at frequencies below the typical knock level reported on SPNs 1355 & 6410.  The level of low frequency knock is reported using a relative scale where 0% is least ...";
CM_ SG_ 2364554750 EngCyl4PressSensorPreliminaryFMI "Used to identify the applicable J1939-73 FMI detected in the engine cylinder 4 pressure sensor.  When there is no failure FMI 31 is sent. In the case of multiple failures the most severe is communicated.";
CM_ SG_ 2364554750 EngCyl4SynchronousKnockLevel "Used to indicate the level of knock for engine cylinder 4. The level of knock is reported using a relative scale where 0% is least level of knock, and increasing levels indicate more knock until 100% indicates the most severe level of knock allowed ...";
CM_ SG_ 2364554750 EngCyl4PeakPress "Peak pressure in engine cylinder 4 in combustion cycle.";
CM_ SG_ 2364554750 EngCyl4HeatRelease "The amount of heat produced during combustion in engine cylinder 4.  The negative range is to cover thermodynamic behavior during misfire.";
CM_ BO_ 2364554494 "Engine Cylinder 3 Combustion Information
Used to communicate combustion information of Engine Cylinder 3. The PGN is transmitted at the end of every combustion in Cylinder 3.";
CM_ SG_ 2364554494 MaxPressIncreaseRate "The maximum slope, in degrees of crank angle, of the pressure increase in engine cylinder 3 during the combustion cycle.";
CM_ SG_ 2364554494 LowFreqKnockLvl "Indicates the level of low frequency knock for engine cylinder 3. This knock occurs at frequencies below the typical knock level reported on SPNs 1354 & 6406.  The level of low frequency knock is reported using a relative scale where 0% is least ...";
CM_ SG_ 2364554494 EngCyl3PressSensorPreliminaryFMI "Used to identify the applicable J1939-73 FMI detected in the engine cylinder 3 pressure sensor.  When there is no failure FMI 31 is sent. In the case of multiple failures the most severe is communicated.";
CM_ SG_ 2364554494 EngCyl3SynchronousKnockLevel "Used to indicate the level of knock for engine cylinder 3. The level of knock is reported using a relative scale where 0% is least level of knock, and increasing levels indicate more knock until 100% indicates the most severe level of knock allowed ...";
CM_ SG_ 2364554494 EngCyl3PeakPress "Peak pressure in engine cylinder 3 in combustion cycle.";
CM_ SG_ 2364554494 EngCyl3HeatRelease "The amount of heat produced during combustion in engine cylinder 3.  The negative range is to cover thermodynamic behavior during misfire.";
CM_ BO_ 2364554238 "Engine Cylinder 2 Combustion Information
Used to communicate combustion information of Engine Cylinder 2. The PGN is transmitted at the end of every combustion in Cylinder 2.";
CM_ SG_ 2364554238 MaxPressIncreaseRate "The maximum slope, in degrees of crank angle, of the pressure increase in engine cylinder 2 during the combustion cycle.";
CM_ SG_ 2364554238 LowFreqKnockLvl "Indicates the level of low frequency knock for engine cylinder 2. This knock occurs at frequencies below the typical knock level reported on SPNs 1353 & 6402.  The level of low frequency knock is reported using a relative scale where 0% is least ...";
CM_ SG_ 2364554238 EngCyl2PressSensorPreliminaryFMI "Used to identify the applicable J1939-73 FMI detected in the engine cylinder 2 pressure sensor.  When there is no failure FMI 31 is sent. In the case of multiple failures the most severe is communicated.";
CM_ SG_ 2364554238 EngCyl2SynchronousKnockLevel "Used to indicate the level of knock for engine cylinder 2. The level of knock is reported using a relative scale where 0% is least level of knock, and increasing levels indicate more knock until 100% indicates the most severe level of knock allowed ...";
CM_ SG_ 2364554238 EngCyl2PeakPress "Peak pressure in engine cylinder 2 in combustion cycle.";
CM_ SG_ 2364554238 EngCyl2HeatRelease "The amount of heat produced during combustion in engine cylinder 2.  The negative range is to cover thermodynamic behavior during misfire.";
CM_ BO_ 2364553982 "Engine Cylinder 1 Combustion Information
Used to communicate combustion information of Engine Cylinder 1. The PGN is transmitted at the end of every combustion in Cylinder 1.";
CM_ SG_ 2364553982 MaxPressIncreaseRate "The maximum slope, in degrees of crank angle, of the pressure increase in engine cylinder 1 during the combustion cycle.";
CM_ SG_ 2364553982 LowFreqKnockLvl "Indicates the level of low frequency knock for engine cylinder 1. This knock occurs at frequencies below the typical knock level reported on SPNs 1352 & 6398. The level of low frequency knock is reported using a relative scale where 0% is least ...";
CM_ SG_ 2364553982 EngCyl1PressSensorPreliminaryFMI "Used to identify the applicable J1939-73 FMI detected in the engine cylinder 1 pressure sensor.  When there is no failure FMI 31 is sent. In the case of multiple failures the most severe is communicated.";
CM_ SG_ 2364553982 EngCyl1SynchronousKnockLevel "Used to indicate the level of knock for engine cylinder 1. The level of knock is reported using a relative scale where 0% is least level of knock, and increasing levels indicate more knock until 100% indicates the most severe level of knock allowed ...";
CM_ SG_ 2364553982 EngCyl1PeakPress "Peak pressure in engine cylinder 1 in combustion cycle.";
CM_ SG_ 2364553982 EngCyl1HeatRelease "The amount of heat produced during combustion in Engine cylinder 1. The negative range is to cover thermodynamic behavior during misfire.";
CM_ BO_ 2364553726 "Engine Air System Information
Used to transmit parameters related to air systems.";
CM_ SG_ 2364553726 EngTotalIntakeMassAirFlowRate "Mass Flow rate of air entering the engine. This also includes the amount of exhaust gas recirculated, if any.";
CM_ SG_ 2364553726 EngDesiredAirFuelRatio "Reports the desired Air Fuel ratio for the engine.

Air Fuel Ratio specifies the amount of air required to completely burn one unit of fuel in the engine to meet the required engine performance and emission standards.";
CM_ BO_ 2364553470 "Engine Torque / Fuel Request
Used to transmit requested information for engine torque and fuel rate.";
CM_ SG_ 2364553470 EngCylTorque "Calculated engine torque output per cylinder.";
CM_ SG_ 2364553470 EngCylDieselMassFlowRateCmd "Commanded Mass Flow rate of diesel fuel delivered to the engine normalized per cylinder.";
CM_ SG_ 2364553470 EngCylGasMassFlowRateCmd "Commanded Mass Flow rate of gaseous fuel delivered to the engine normalized per cylinder.";
CM_ SG_ 2364553470 EngGasFuelPercentageCmd "Percentage of Gaseous fuel used, in terms of % mass of fuel. 0% means no Gaseous fuel used and 100 % means completely gaseous fuel is used.
Gas substitution is the process for a dual fuel engine system of substituting gas, e.g. natural gas, for ...";
CM_ SG_ 2364553470 EngDualFuelModeCmd "Request to enable dual fuel mode.

00 = De-activate dual fuel mode
01 = Activate dual fuel mode
10 = Reserved
11 = Not available";
CM_ BO_ 2364553214 "Engine Turbocharger Blowoff Actuator 1
Used to transmit Engine Turbocharger Blowoff Actuator parameters";
CM_ SG_ 2364553214 EngTrbCmprssrBlwffActtr1OprtnStt "Used to identify the status of Engine Turbocharger Compressor Blowoff Actuator 1.
0000 - Normal
0001 - Alarm (fully operational but needs service)
0010 - Alarm High Severity (functional but transient performance may be reduced)
0011 - Derate ...";
CM_ SG_ 2364553214 EngTrbCmprssrBlowoffActuator1Pos "Actual position of the turbocharger compressor blowoff actuator, where 0% represents fully closed and 100% represents fully open.";
CM_ SG_ 2364553214 EngTrbCmprssrBlwffActtr1DsredPos "The requested position of the Engine Turbocharger Compressor Blowoff actuator by the engine ECU, where 0% represents bypass fully closed and 100% represents fully open.  This is the position that the device is attempting to achieve.";
CM_ SG_ 2364553214 EngTrbCmprssrBlwoffActuator1Temp "Temperature of the Engine Turbocharger Compressor Bypass Actuator 1 drive circuitry. Temperature excursions may affect the torque output.";
CM_ SG_ 2364553214 EngTrbCmprssrBlwffActtr1TmpSttus "Used to identify the status of the Engine Turbocharger Compresssor Blowoff Actuator 1 drive circuitry temperature. Temperature excursions may affect the torque output.
000 - High Most severe
001 - High Least severe
010 - In Range
011 - Low Least ...";
CM_ SG_ 2364553214 EngTrbCmprssrBlwffActtr1PrlmnryF "Used to identify the applicable J1939-73 FMI detected in the Engine Turbocharger Blowoff Actuator 1 by the manufacturer's software. When there is no failure FMI 31 is transmitted. When there are multiple failures, the most severe is transmitted.";
CM_ BO_ 2565874430 "Machine Selected Speed
Message that provides the current machine selected speed, direction, and source parameters.";
CM_ SG_ 2565874430 PersistentLimitStatus "Reports the tractor ECU's present limit status associated with a parameter whose commands are presistent  (i.e. hitch position).
000 - Not limited
001 - Operator limited/controlled (Request cannot be implemented)
010 - Limited high (only lower ...";
CM_ SG_ 2565874430 MachineSelectedSpeedSource "Indicates the speed source that is currently being reported in the machine speed parameter.
000 - Wheel-based speed
001 - Ground-based speed
010 - Navigation-based speed
011 - 'Blended' speed
100 - 'Simulated' speed
101 - 110 - Reserved
111 - ...";
CM_ SG_ 2565874430 MachineSelectedDirection "Indicates the current direction of travel of the machine.

00 - Reverse
01 - Forward
10 - Error indication
11 - Not available";
CM_ SG_ 2565874430 MachineSelectedDistance "Actual distance traveled by the machine based on the value of selected machine speed.  When distance exceeds 4211081.215 m, the value should be reset to zero and incremented as additional distance accrues.";
CM_ SG_ 2565874430 MachineSelectedSpeed "Reports the value of one of the currently available machine speeds (wheel, ground, or navigational-based) which the machine has determined to best represent the machine's speed.";
CM_ BO_ 2565873918 "Electronic Brake System #2/5
Message to transmit data of the towed vehicle to the towing vehicle. See ISO 11992-2.";
CM_ BO_ 2565873662 "Electronic Brake System #2/6
Message to transmit data of the towed vehicle to the towing vehicle. See ISO 11992-2.";
CM_ BO_ 2364546814 "Generator Control 2
Contains parameters that allow the generator control system to control the engine and to provide information about the generator control system";
CM_ SG_ 2364546814 GeneratorGoverningBias "Control signal used to govern the genset's speed or load (depending on isochronous or utility parallel operation, respectively)
NOTE:  If this method of engine control is used, the PGN 0 (TSC1) is not expected to be received by the engine ...";
CM_ BO_ 2565872638 "General Purpose Message #1/7
Message to transmit data of the towing vehicle to the towed vehicle. See ISO 11992-3.";
CM_ BO_ 2565340926 "Node-to-Virtual Terminal";
CM_ BO_ 2565275390 "Virtual Terminal-to-Node";
CM_ BO_ 2566767614 "Electronic Engine Controller 15";
CM_ SG_ 2566767614 AccelPedal2Channel3 "Sensor output 3 for the accelerator pedal #2 position when using a redundant-style sensor.  The ratio of actual accelerator pedal position to maximum pedal position. This is for the second occurrence of the accelerator pedal. Although it is used as ...";
CM_ SG_ 2566767614 AccelPedal2Channel2 "Sensor output 2 for the accelerator pedal #2 position when using a redundant-style sensor.  The ratio of actual accelerator pedal position to maximum pedal position. This is for the second occurrence of the accelerator pedal. Although it is used as ...";
CM_ SG_ 2566767614 AccelPedal1Channel3 "Sensor output 3 for the accelerator pedal #1 position when using a redundant-style sensor.  The ratio of actual accelerator pedal position to maximum pedal position. This is for the first occurrence of the accelerator pedal. Although it is used as ...";
CM_ SG_ 2566767614 AccelPedal1Channel2 "Sensor output 2 for the accelerator pedal #1 position when using a redundant-style sensor.  The ratio of actual accelerator pedal position to maximum pedal position. This is for the first occurrence of the accelerator pedal. Although it is used as ...";
CM_ BO_ 2559049470 "Engine State Requests";
CM_ SG_ 2559049470 DesiredEngFuelingState "Devices send this request to the engine controller to:
(a) Shut off engine fueling, but remain prepared to re-start quickly by not shutting down the control system, or
(b) Keep the engine running.
00 Fueling not desired (shut off engine fueling)
 ...";
CM_ SG_ 2559049470 RequestedFuelType "Engine controller receives this request from another control module to select the type of fuel to be used for engine operation.
0x00 - Not available - NONE
0x01 - Gasoline/petrol - GAS
0x02 - Methanol - METH
0x03 - Ethanol - ETH
0x04 - Diesel - ...";
CM_ SG_ 2559049470 EngGasFuelSupplyDesiredPress "Desired gage pressure of gaseous fuel supply to the engine.";
CM_ SG_ 2559049470 EngGasFuelUsageInhibited "Used to request that the engine should not be allowed to use gaseous fuel for engine cylinder combustion. This state is relevant for dual fuel systems and would be used when conditions are detected that make it unsafe or not appropriate to use ...";
CM_ BO_ 2349596414 "Advanced Emergency Braking System 2
Advanced Emergency Braking System message 2.";
CM_ SG_ 2349596414 AebSensSetgReq "AEB Sensitivity Settings Request";
CM_ SG_ 2349596414 AEBS2MessageChecksum "Used to check the message checksum of the transmitting (HMI) unit within the AEBS2 system.
Checksum = (Byte1 + Byte2 + Byte3 + Byte4 + Byte5 + Byte6 + Byte7 + (message counter & 0x0F) + message ID low byte + message ID mid low byte + message ID mid ...";
CM_ SG_ 2349596414 AEBS2MessageCounter "The message counter is increased with every transmitted AEBS2 message.  After reaching a value of 0xF the next value will be 0.";
CM_ SG_ 2349596414 DrvrActvtnDmndFrAdvncdEmrgncyBrk "According to the Vienna world convention on road traffic the driver must be provided with means to deactivate an Advanced Emergency Braking System. This command is to be transmitted from the respective HMI unit to the AEBS unit.
00 - the driver ...";
CM_ BO_ 2563702526 "Reserved for ISO 15765
KWP2000 Mixed physical addressing";
CM_ BO_ 2563636990 "Reserved for ISO 15765
KWP2000 Mixed functional addressing";
CM_ BO_ 2563571454 "Request for Repetition Rate
This message allows the system to adapt the bus bandwidth to the needs of the user of messages.";
CM_ SG_ 2563571454 DataDictionaryRow "This 4 bit parameter indicates the Row that is to be used within the specific Data Dictionary Table identified by the Implement Type. This is the Group (GRUP) in LBS documents.";
CM_ SG_ 2563571454 DataDictionaryColumn "This 4 bit parameter indicates the Column that is to be used within the specific Data Dictionary Table identified by the Implement Type. This is the Instance (INST) in LBS documents.";
CM_ SG_ 2563571454 ImplementType "This 4 bit parameter indicates which data dictionary page is to be used to locate the identity of the following data.";
CM_ SG_ 2563571454 ImplementPos "This 4 bit parameter of this message will indicate which Implement is referenced within a set of identical Implements.  The numbering is to start with 1 at the leftmost, foremost, bottom most implement.  The numbering will then increment from left ...";
CM_ SG_ 2563571454 DataFormat_ErrorCondition "This 2 bit parameter that indicates the format or availability of the data in the following Process Data Parameter.
00 Data format is Long Integer
01 Data format is Floating
10 Data format is unsigned Long Integer
11 Not Available or error
Data ...";
CM_ SG_ 2563571454 ProcessDataType "This 2 bit parameter indicates what the data in the following Process Data Parameters is to be used for. See Table A.2.
00 Data is Set Point
01 Data is Actual values
10 Message is Set Point request
11 Message is Actual value request
Data is Set ...";
CM_ SG_ 2563571454 ProcessDataModifier "This 3 bit parameter that indicates how the data in the following Process Data Parameters is to be used when combined with the Process Data Type parameter. See Table A.2.

NOTE: Process Data Type is included since MOD is a function of PD";
CM_ SG_ 2563571454 RepetitionRateParameter "This parameter defines the repetition rate of the specified PGN.";
CM_ BO_ 2563505918 "Process Data Message
The Process Data message has been defined as a destination specific message implying that the sender must decide which implement should receive the message.Working Set).";
CM_ SG_ 2563505918 ProcessVariableValue "This 4 byte parameter contains the actual data  for the Process Data Message.";
CM_ SG_ 2563505918 DataDictionaryRow "This 4 bit parameter indicates the Row that is to be used within the specific Data Dictionary Table identified by the Implement Type. This is the Group (GRUP) in LBS documents.";
CM_ SG_ 2563505918 DataDictionaryColumn "This 4 bit parameter indicates the Column that is to be used within the specific Data Dictionary Table identified by the Implement Type. This is the Instance (INST) in LBS documents.";
CM_ SG_ 2563505918 ImplementType "This 4 bit parameter indicates which data dictionary page is to be used to locate the identity of the following data.";
CM_ SG_ 2563505918 ImplementPos "This 4 bit parameter of this message will indicate which Implement is referenced within a set of identical Implements.  The numbering is to start with 1 at the leftmost, foremost, bottom most implement.  The numbering will then increment from left ...";
CM_ SG_ 2563505918 CountNumber "This parameter indicates which member of the set of possible entities is being referenced. The means of generating this Count Number is explained in the following clause.";
CM_ SG_ 2563505918 DataFormat_ErrorCondition "This 2 bit parameter that indicates the format or availability of the data in the following Process Data Parameter.
00 Data format is Long Integer
01 Data format is Floating
10 Data format is unsigned Long Integer
11 Not Available or error
Data ...";
CM_ SG_ 2563505918 ProcessDataType "This 2 bit parameter indicates what the data in the following Process Data Parameters is to be used for. See Table A.2.
00 Data is Set Point
01 Data is Actual values
10 Message is Set Point request
11 Message is Actual value request
Data is Set ...";
CM_ SG_ 2563505918 ProcessDataModifier "This 3 bit parameter that indicates how the data in the following Process Data Parameters is to be used when combined with the Process Data Type parameter. See Table A.2.

NOTE: Process Data Type is included since MOD is a function of PD";
CM_ BO_ 2563309310 "Extended Transport Protocol - Connection Management
Defined in ISO 11783-6  Annex L";
CM_ BO_ 2563243774 "Extended Transport Protocol - Data Transfer
Defined in ISO 11783-6  Annex L";
CM_ BO_ 2563178238 "General Purpose Valve Estimated Flow
This message provides the estimated flow of a general purpose valve.  Defined in ISO 11783-7.";
CM_ SG_ 2563178238 ValveFailSafeMode "Command for setting the fail safe mode of a general purpose valve.

00 Block
01 Float
10 Reserved
11 Don't Care";
CM_ SG_ 2563178238 ValveState "The measured state of the general purpose valve.   With float enabled, hydraulic fluid may flow to or from the tractor as driven by the implement.
0000            Blocked
0001            Extend
0010            Retract
0011            Floating
 ...";
CM_ SG_ 2563178238 RetractPortEstFlow "The value reported by the controller of flow through the extend port of an auxiliary valve of a tractor";
CM_ SG_ 2563178238 ExtendPortEstFlow "The value reported by the controller of flow through the extend port of an auxiliary valve of a tractor";
CM_ BO_ 2563112702 "General Purpose Valve Measured Flow
This message provides the measurement of a general purpose valve.  Defined in ISO11783-7.";
CM_ SG_ 2563112702 ReturnPortPress "The measured nominal pressure at the return port of an auxiliary valve of a tractor";
CM_ SG_ 2563112702 RetractPortPress "The measured nominal pressure at the retract port of an auxiliary valve of a tractor";
CM_ SG_ 2563112702 ExtendPortPress "The measured nominal pressure at the extend port of an auxiliary valve of a tractor";
CM_ SG_ 2563112702 RetractPortMeasuredFlow "The measured flow through the retract port of an auxiliary valve of a tractor";
CM_ SG_ 2563112702 ExtendPortMeasuredFlow "The measured flow through the extend port of an auxiliary valve of a tractor";
CM_ BO_ 2563047166 "General Purpose Valve Command
This message provides control of the flow through a general purpose valve.  Defined in ISO 11783-7.";
CM_ SG_ 2563047166 PortFlowCmd "The command to set the flow through the extend or retract port of an auxiliary valve of a tractor";
CM_ BO_ 2562785022 "Proprietarily Configurable Message #16
Proprietarily Configuration message for use in J1939-74.";
CM_ BO_ 2562719486 "Proprietarily Configurable Message #15
Proprietarily Configuration message for use in J1939-74.";
CM_ BO_ 2562653950 "Proprietarily Configurable Message #14
Proprietarily Configuration message for use in J1939-74.";
CM_ BO_ 2562588414 "Proprietarily Configurable Message #13
Proprietarily Configuration message for use in J1939-74.";
CM_ BO_ 2562522878 "Proprietarily Configurable Message #12
Proprietarily Configuration message for use in J1939-74.";
CM_ BO_ 2562457342 "Proprietarily Configurable Message #11
Proprietarily Configuration message for use in J1939-74.";
CM_ BO_ 2562391806 "Proprietarily Configurable Message #10
Proprietarily Configuration message for use in J1939-74.";
CM_ BO_ 2562326270 "Proprietarily Configurable Message #9
Proprietarily Configuration message for use in J1939-74.";
CM_ BO_ 2562260734 "Proprietarily Configurable Message #8
Proprietarily Configuration message for use in J1939-74.";
CM_ BO_ 2562195198 "Proprietarily Configurable Message #7
Proprietarily Configuration message for use in J1939-74.";
CM_ BO_ 2562129662 "Proprietarily Configurable Message #6
Proprietarily Configuration message for use in J1939-74.";
CM_ BO_ 2562064126 "Proprietarily Configurable Message #5
Proprietarily Configuration message for use in J1939-74.";
CM_ BO_ 2561998590 "Proprietarily Configurable Message #4
Proprietarily Configuration message for use in J1939-74.";
CM_ BO_ 2561933054 "Proprietarily Configurable Message #3
Proprietarily Configuration message for use in J1939-74.";
CM_ BO_ 2561867518 "Proprietarily Configurable Message #2
Proprietarily Configuration message for use in J1939-74.";
CM_ BO_ 2561801982 "Proprietarily Configurable Message #1
Proprietarily Configuration message for use in J1939-74.";
CM_ BO_ 2561736446 "Configuration Identification Message
Message used to identify the data content (by SPN) of one of the configurable messages
(identified by PGN).";
CM_ BO_ 2561670910 "Parameter Locate Message
This message is designed to cause other CAs to respond with the identity of any message that they send in which the particular parameter (identified by specific SPN) is contained";
CM_ BO_ 2561539838 "Agricultural Guidance System Command
Steering command expressed as desired curvature";
CM_ BO_ 2561474302 "Agricultural Guidance Machine Info
Machine system feedback detailing status of machine relative to guidance operation";
CM_ BO_ 2561408766 "File Server to Client (ECU) message
Used for obtaining status of the client, volume handling, file access, file handling and directory handling.  Description of messages is given in ISO 11783 Part 13.";
CM_ BO_ 2560294654 "General Purpose Message #1/8
Message to transmit data of the towing vehicle to the towed vehicle. See ISO 11992-3.";
BA_DEF_ SG_  "SigType" ENUM  "Default","Range","RangeSigned","ASCII","Discrete","Control","ReferencePGN","DTC","StringDelimiter","StringLength","StringLengthControl","MessageCounter","MessageChecksum";
BA_DEF_ SG_  "GenSigStartValue" INT 0 2147483647;
BA_DEF_ SG_  "GenSigSendType" ENUM  "Cyclic","OnWrite","OnWriteWithRepetition","OnChange","OnChangeWithRepetition","IfActive","IfActiveWithRepetition","NoSigSendType";
BA_DEF_ SG_  "GenSigILSupport" ENUM  "No","Yes";
BA_DEF_ SG_  "GenSigEVName" STRING ;
BA_DEF_ SG_  "SPN" INT 0 524287;
BA_DEF_ BO_  "TpJ1939VarDlc" ENUM  "No","Yes";
BA_DEF_ BO_  "GenMsgCycleTimeFast" INT 0 3600000;
BA_DEF_ BO_  "GenMsgStartDelayTime" INT 0 100000;
BA_DEF_ BO_  "GenMsgILSupport" ENUM  "No","Yes";
BA_DEF_ BO_  "GenMsgDelayTime" INT 0 1000;
BA_DEF_ BO_  "GenMsgRequestable" INT 0 1;
BA_DEF_ BO_  "GenMsgSendType" ENUM  "cyclic","NotUsed","NotUsed","NotUsed","NotUsed","NotUsed","NotUsed","IfActive","noMsgSendType";
BA_DEF_ BO_  "VFrameFormat" ENUM  "StandardCAN","ExtendedCAN","reserved","J1939PG";
BA_DEF_ BO_  "GenMsgCycleTime" INT 0 3600000;
BA_DEF_ BO_  "SendOnChange" ENUM  "No","Yes";
BA_DEF_ SG_  "SystemSignalLongSymbol" STRING ;
BA_DEF_DEF_  "SigType" "Default";
BA_DEF_DEF_  "GenSigStartValue" 0;
BA_DEF_DEF_  "GenSigSendType" "NoSigSendType";
BA_DEF_DEF_  "GenSigILSupport" "Yes";
BA_DEF_DEF_  "GenSigEVName" "Env@Nodename_@Signame";
BA_DEF_DEF_  "SPN" 0;
BA_DEF_DEF_  "TpJ1939VarDlc" "No";
BA_DEF_DEF_  "GenMsgCycleTimeFast" 0;
BA_DEF_DEF_  "GenMsgStartDelayTime" 0;
BA_DEF_DEF_  "GenMsgILSupport" "Yes";
BA_DEF_DEF_  "GenMsgDelayTime" 0;
BA_DEF_DEF_  "GenMsgRequestable" 1;
BA_DEF_DEF_  "GenMsgSendType" "noMsgSendType";
BA_DEF_DEF_  "VFrameFormat" "J1939PG";
BA_DEF_DEF_  "GenMsgCycleTime" 0;
BA_DEF_DEF_  "SendOnChange" "No";
BA_DEF_DEF_  "SystemSignalLongSymbol" "";
BA_ "TpJ1939VarDlc" BO_ 2566691326 1;
BA_ "GenMsgCycleTime" BO_ 2499582206 500;
BA_ "GenMsgSendType" BO_ 2499582206 0;
BA_ "GenMsgCycleTime" BO_ 2566690814 500;
BA_ "GenMsgSendType" BO_ 2566690814 0;
BA_ "GenMsgDelayTime" BO_ 2566690814 20;
BA_ "GenMsgCycleTime" BO_ 2566690558 100;
BA_ "GenMsgSendType" BO_ 2566690558 0;
BA_ "GenMsgCycleTime" BO_ 2365363710 100;
BA_ "GenMsgSendType" BO_ 2365363710 0;
BA_ "GenMsgCycleTime" BO_ 2566690046 1000;
BA_ "GenMsgSendType" BO_ 2566690046 0;
BA_ "GenMsgCycleTime" BO_ 2499580158 500;
BA_ "GenMsgSendType" BO_ 2499580158 0;
BA_ "GenMsgCycleTime" BO_ 2432471038 100;
BA_ "GenMsgSendType" BO_ 2432471038 0;
BA_ "TpJ1939VarDlc" BO_ 2566688254 1;
BA_ "GenMsgCycleTime" BO_ 2297455358 10;
BA_ "GenMsgSendType" BO_ 2297455358 0;
BA_ "GenMsgCycleTime" BO_ 2365428734 100;
BA_ "GenMsgSendType" BO_ 2365428734 0;
BA_ "TpJ1939VarDlc" BO_ 2566702846 1;
BA_ "TpJ1939VarDlc" BO_ 2566703102 1;
BA_ "TpJ1939VarDlc" BO_ 2566705918 1;
BA_ "TpJ1939VarDlc" BO_ 2566705662 1;
BA_ "GenMsgCycleTime" BO_ 2349465342 100;
BA_ "GenMsgSendType" BO_ 2349465342 0;
BA_ "GenMsgCycleTime" BO_ 2364553726 20;
BA_ "GenMsgSendType" BO_ 2364553726 0;
BA_ "GenMsgCycleTime" BO_ 2364553470 20;
BA_ "GenMsgSendType" BO_ 2364553470 0;
BA_ "GenMsgCycleTime" BO_ 2364553214 100;
BA_ "GenMsgSendType" BO_ 2364553214 0;
BA_ "GenMsgCycleTime" BO_ 2364546814 20;
BA_ "GenMsgSendType" BO_ 2364546814 0;
BA_ "GenMsgCycleTime" BO_ 2559049470 1000;
BA_ "GenMsgSendType" BO_ 2559049470 0;
BA_ "GenMsgDelayTime" BO_ 2559049470 100;
BA_ "GenMsgCycleTime" BO_ 2349596414 50;
BA_ "GenMsgSendType" BO_ 2349596414 0;
BA_ "GenMsgDelayTime" BO_ 2349596414 10;
BA_ "GenMsgRequestable" BO_ 2563702526 0;
BA_ "GenMsgRequestable" BO_ 2563636990 0;
BA_ "GenMsgRequestable" BO_ 2563309310 0;
BA_ "GenMsgRequestable" BO_ 2563243774 0;
BA_ "SPN" SG_ 2566692094 Joystick1Lamp10Status 6347;
BA_ "SigType" SG_ 2566692094 Joystick1Lamp10Status 5;
BA_ "SPN" SG_ 2566692094 Joystick1Lamp9Status 6346;
BA_ "SigType" SG_ 2566692094 Joystick1Lamp9Status 5;
BA_ "SPN" SG_ 2566692094 Joystick1Lamp8Status 6345;
BA_ "SigType" SG_ 2566692094 Joystick1Lamp8Status 5;
BA_ "SPN" SG_ 2566692094 Joystick1Lamp7Status 6344;
BA_ "SigType" SG_ 2566692094 Joystick1Lamp7Status 5;
BA_ "SPN" SG_ 2566692094 Joystick1Lamp6Status 6343;
BA_ "SigType" SG_ 2566692094 Joystick1Lamp6Status 5;
BA_ "SPN" SG_ 2566692094 Joystick1Lamp5Status 6342;
BA_ "SigType" SG_ 2566692094 Joystick1Lamp5Status 5;
BA_ "SPN" SG_ 2566692094 Joystick1Lamp4Status 6341;
BA_ "SigType" SG_ 2566692094 Joystick1Lamp4Status 5;
BA_ "SPN" SG_ 2566692094 Joystick1Lamp3Status 6340;
BA_ "SigType" SG_ 2566692094 Joystick1Lamp3Status 5;
BA_ "SPN" SG_ 2566692094 Joystick1Lamp2Status 6339;
BA_ "SigType" SG_ 2566692094 Joystick1Lamp2Status 5;
BA_ "SPN" SG_ 2566692094 Joystick1Lamp1Status 6338;
BA_ "SigType" SG_ 2566692094 Joystick1Lamp1Status 5;
BA_ "SPN" SG_ 2566691838 Joystick2Lamp10Status 6357;
BA_ "SigType" SG_ 2566691838 Joystick2Lamp10Status 5;
BA_ "SPN" SG_ 2566691838 Joystick2Lamp9Status 6356;
BA_ "SigType" SG_ 2566691838 Joystick2Lamp9Status 5;
BA_ "SPN" SG_ 2566691838 Joystick2Lamp8Status 6355;
BA_ "SigType" SG_ 2566691838 Joystick2Lamp8Status 5;
BA_ "SPN" SG_ 2566691838 Joystick2Lamp7Status 6354;
BA_ "SigType" SG_ 2566691838 Joystick2Lamp7Status 5;
BA_ "SPN" SG_ 2566691838 Joystick2Lamp6Status 6353;
BA_ "SigType" SG_ 2566691838 Joystick2Lamp6Status 5;
BA_ "SPN" SG_ 2566691838 Joystick2Lamp5Status 6352;
BA_ "SigType" SG_ 2566691838 Joystick2Lamp5Status 5;
BA_ "SPN" SG_ 2566691838 Joystick2Lamp4Status 6351;
BA_ "SigType" SG_ 2566691838 Joystick2Lamp4Status 5;
BA_ "SPN" SG_ 2566691838 Joystick2Lamp3Status 6350;
BA_ "SigType" SG_ 2566691838 Joystick2Lamp3Status 5;
BA_ "SPN" SG_ 2566691838 Joystick2Lamp2Status 6349;
BA_ "SigType" SG_ 2566691838 Joystick2Lamp2Status 5;
BA_ "SPN" SG_ 2566691838 Joystick2Lamp1Status 6348;
BA_ "SigType" SG_ 2566691838 Joystick2Lamp1Status 5;
BA_ "SPN" SG_ 2566691582 Joystick3Lamp10Status 6367;
BA_ "SigType" SG_ 2566691582 Joystick3Lamp10Status 5;
BA_ "SPN" SG_ 2566691582 Joystick3Lamp9Status 6366;
BA_ "SigType" SG_ 2566691582 Joystick3Lamp9Status 5;
BA_ "SPN" SG_ 2566691582 Joystick3Lamp8Status 6365;
BA_ "SigType" SG_ 2566691582 Joystick3Lamp8Status 5;
BA_ "SPN" SG_ 2566691582 Joystick3Lamp7Status 6364;
BA_ "SigType" SG_ 2566691582 Joystick3Lamp7Status 5;
BA_ "SPN" SG_ 2566691582 Joystick3Lamp6Status 6363;
BA_ "SigType" SG_ 2566691582 Joystick3Lamp6Status 5;
BA_ "SPN" SG_ 2566691582 Joystick3Lamp5Status 6362;
BA_ "SigType" SG_ 2566691582 Joystick3Lamp5Status 5;
BA_ "SPN" SG_ 2566691582 Joystick3Lamp4Status 6361;
BA_ "SigType" SG_ 2566691582 Joystick3Lamp4Status 5;
BA_ "SPN" SG_ 2566691582 Joystick3Lamp3Status 6360;
BA_ "SigType" SG_ 2566691582 Joystick3Lamp3Status 5;
BA_ "SPN" SG_ 2566691582 Joystick3Lamp2Status 6359;
BA_ "SigType" SG_ 2566691582 Joystick3Lamp2Status 5;
BA_ "SPN" SG_ 2566691582 Joystick3Lamp1Status 6358;
BA_ "SigType" SG_ 2566691582 Joystick3Lamp1Status 5;
BA_ "SPN" SG_ 2566691326 AssemblyUnitIdentification 6369;
BA_ "SigType" SG_ 2566691326 AssemblyUnitIdentification 8;
BA_ "SPN" SG_ 2566691326 NmbrOfAssmblyUntIdntfctionFields 6368;
BA_ "SigType" SG_ 2566691326 NmbrOfAssmblyUntIdntfctionFields 1;
BA_ "SPN" SG_ 2499582206 SftTpSpdLmtRmnngCntnsIntrvlDstnc 6914;
BA_ "SigType" SG_ 2499582206 SftTpSpdLmtRmnngCntnsIntrvlDstnc 1;
BA_ "SPN" SG_ 2499582206 SoftTopSpeedLimitResetDistance 6373;
BA_ "SigType" SG_ 2499582206 SoftTopSpeedLimitResetDistance 1;
BA_ "SPN" SG_ 2499582206 SftTpSpeedLimitRemainingDistance 6372;
BA_ "SigType" SG_ 2499582206 SftTpSpeedLimitRemainingDistance 1;
BA_ "SPN" SG_ 2499582206 SoftTopLifetimeLimitExceeded 6371;
BA_ "SigType" SG_ 2499582206 SoftTopLifetimeLimitExceeded 5;
BA_ "SPN" SG_ 2499582206 SoftTopSpeedLimitActive 6370;
BA_ "SigType" SG_ 2499582206 SoftTopSpeedLimitActive 5;
BA_ "SPN" SG_ 2566690814 CrabSteerModeActuatorState 6381;
BA_ "SigType" SG_ 2566690814 CrabSteerModeActuatorState 4;
BA_ "SPN" SG_ 2566690814 CircleSteerModeActuatorState 6380;
BA_ "SigType" SG_ 2566690814 CircleSteerModeActuatorState 4;
BA_ "SPN" SG_ 2566690814 VourWheelSteerActuatorState 6379;
BA_ "SigType" SG_ 2566690814 VourWheelSteerActuatorState 4;
BA_ "SPN" SG_ 2566690814 TwoWheelSteerActuatorState 6378;
BA_ "SigType" SG_ 2566690814 TwoWheelSteerActuatorState 4;
BA_ "SPN" SG_ 2566690814 RearSteerAxleCenteredStatus 6377;
BA_ "SigType" SG_ 2566690814 RearSteerAxleCenteredStatus 5;
BA_ "SPN" SG_ 2566690814 FrontSteerAxleCenteredStatus 6376;
BA_ "SigType" SG_ 2566690814 FrontSteerAxleCenteredStatus 5;
BA_ "SPN" SG_ 2566690814 SteerModeSwitch 6375;
BA_ "SPN" SG_ 2566690558 CommonRailOilAbsPress 7721;
BA_ "SigType" SG_ 2566690558 CommonRailOilAbsPress 1;
BA_ "SPN" SG_ 2566690558 CommonRailOilPress 7720;
BA_ "SigType" SG_ 2566690558 CommonRailOilPress 1;
BA_ "SPN" SG_ 2566690558 EngPreFilterOilPress 7470;
BA_ "SigType" SG_ 2566690558 EngPreFilterOilPress 1;
BA_ "SPN" SG_ 2566690558 EngExhaustPress1ExRange 6384;
BA_ "SigType" SG_ 2566690558 EngExhaustPress1ExRange 1;
BA_ "SPN" SG_ 2365363710 EngCylPrssMonitor2PreliminaryFMI 6391;
BA_ "SPN" SG_ 2365363710 EngCylPrssMonitor1PreliminaryFMI 6390;
BA_ "SPN" SG_ 2566690046 AfterrunCompleteThisCycle 6482;
BA_ "SigType" SG_ 2566690046 AfterrunCompleteThisCycle 4;
BA_ "SPN" SG_ 2566690046 DEFDoserPurgeCompleteLastCycle 6481;
BA_ "SigType" SG_ 2566690046 DEFDoserPurgeCompleteLastCycle 4;
BA_ "SPN" SG_ 2566690046 DEFDoserPurgeCompleteThisCycle 6480;
BA_ "SigType" SG_ 2566690046 DEFDoserPurgeCompleteThisCycle 4;
BA_ "SPN" SG_ 2566690046 DEFDoserCldnCompleteLastCycle 6479;
BA_ "SigType" SG_ 2566690046 DEFDoserCldnCompleteLastCycle 4;
BA_ "SPN" SG_ 2566690046 DEFDoserCldnCompleteThisCycle 6478;
BA_ "SigType" SG_ 2566690046 DEFDoserCldnCompleteThisCycle 4;
BA_ "SPN" SG_ 2566690046 DEFDoserPurgeInterruptCount 6477;
BA_ "SigType" SG_ 2566690046 DEFDoserPurgeInterruptCount 1;
BA_ "SPN" SG_ 2566690046 DEFDoserCldnInterruptCount 6476;
BA_ "SigType" SG_ 2566690046 DEFDoserCldnInterruptCount 1;
BA_ "SPN" SG_ 2566689790 EngPrechamberFuelDesiredAbsPress 6574;
BA_ "SigType" SG_ 2566689790 EngPrechamberFuelDesiredAbsPress 1;
BA_ "SPN" SG_ 2566689790 EngPrechamberFuelAbsPress 6573;
BA_ "SigType" SG_ 2566689790 EngPrechamberFuelAbsPress 1;
BA_ "SPN" SG_ 2566689790 EngMinChamberFuelDesiredAbsPress 6572;
BA_ "SigType" SG_ 2566689790 EngMinChamberFuelDesiredAbsPress 1;
BA_ "SPN" SG_ 2566689790 EngMainChamberFuelAbsPress 6571;
BA_ "SigType" SG_ 2566689790 EngMainChamberFuelAbsPress 1;
BA_ "SPN" SG_ 2566689534 EngPrechamberDesiredAirFuelRatio 6578;
BA_ "SigType" SG_ 2566689534 EngPrechamberDesiredAirFuelRatio 1;
BA_ "SPN" SG_ 2566689534 EngPrechamberAirFuelRatio 6577;
BA_ "SigType" SG_ 2566689534 EngPrechamberAirFuelRatio 1;
BA_ "SPN" SG_ 2566689534 EngMinChamberDesiredAirFuelRatio 6576;
BA_ "SigType" SG_ 2566689534 EngMinChamberDesiredAirFuelRatio 1;
BA_ "SPN" SG_ 2566689534 EngMainChamberAirFuelRatio 6575;
BA_ "SigType" SG_ 2566689534 EngMainChamberAirFuelRatio 1;
BA_ "SPN" SG_ 2566689278 EngExhaustDesiredNOx 6580;
BA_ "SigType" SG_ 2566689278 EngExhaustDesiredNOx 1;
BA_ "SPN" SG_ 2566689278 EngExhaustNOx 6579;
BA_ "SigType" SG_ 2566689278 EngExhaustNOx 1;
BA_ "SPN" SG_ 2499580158 EngInjectorMeteringRail2Press2 6592;
BA_ "SigType" SG_ 2499580158 EngInjectorMeteringRail2Press2 1;
BA_ "SPN" SG_ 2499580158 EngInjectorMeteringRail2Press1 6591;
BA_ "SigType" SG_ 2499580158 EngInjectorMeteringRail2Press1 1;
BA_ "SPN" SG_ 2499580158 EngInjectorMeteringRail1Press2 6590;
BA_ "SigType" SG_ 2499580158 EngInjectorMeteringRail1Press2 1;
BA_ "SPN" SG_ 2499580158 EngInjectorMeteringRail1Press1 6589;
BA_ "SigType" SG_ 2499580158 EngInjectorMeteringRail1Press1 1;
BA_ "SPN" SG_ 2432471038 GasFuelAccumulatorTemp 6815;
BA_ "SigType" SG_ 2432471038 GasFuelAccumulatorTemp 1;
BA_ "SPN" SG_ 2432471038 EngFuelVaporizer1DischargeTemp 6610;
BA_ "SigType" SG_ 2432471038 EngFuelVaporizer1DischargeTemp 1;
BA_ "SPN" SG_ 2432471038 EngGasFuelSupplyPress 6646;
BA_ "SigType" SG_ 2432471038 EngGasFuelSupplyPress 1;
BA_ "SPN" SG_ 2566688254 ProductIdentificationModel 6701;
BA_ "SigType" SG_ 2566688254 ProductIdentificationModel 8;
BA_ "SPN" SG_ 2566688254 ProductIdentificationBrand 6700;
BA_ "SigType" SG_ 2566688254 ProductIdentificationBrand 8;
BA_ "SPN" SG_ 2566688254 ProductIdentificationCode 6699;
BA_ "SigType" SG_ 2566688254 ProductIdentificationCode 8;
BA_ "SPN" SG_ 2364567038 EngGsFlVlve20StartOfActuationCmd 6697;
BA_ "SigType" SG_ 2364567038 EngGsFlVlve20StartOfActuationCmd 1;
BA_ "SPN" SG_ 2364567038 EngGsFlVlve19StartOfActuationCmd 6696;
BA_ "SigType" SG_ 2364567038 EngGsFlVlve19StartOfActuationCmd 1;
BA_ "SPN" SG_ 2364567038 EngGsFlVlve18StartOfActuationCmd 6695;
BA_ "SigType" SG_ 2364567038 EngGsFlVlve18StartOfActuationCmd 1;
BA_ "SPN" SG_ 2364567038 EngGsFlVlve17StartOfActuationCmd 6694;
BA_ "SigType" SG_ 2364567038 EngGsFlVlve17StartOfActuationCmd 1;
BA_ "SPN" SG_ 2364566782 EngGsFlVlve16StartOfActuationCmd 6693;
BA_ "SigType" SG_ 2364566782 EngGsFlVlve16StartOfActuationCmd 1;
BA_ "SPN" SG_ 2364566782 EngGsFlVlve15StartOfActuationCmd 6692;
BA_ "SigType" SG_ 2364566782 EngGsFlVlve15StartOfActuationCmd 1;
BA_ "SPN" SG_ 2364566782 EngGsFlVlve14StartOfActuationCmd 6691;
BA_ "SigType" SG_ 2364566782 EngGsFlVlve14StartOfActuationCmd 1;
BA_ "SPN" SG_ 2364566782 EngGsFlVlve13StartOfActuationCmd 6690;
BA_ "SigType" SG_ 2364566782 EngGsFlVlve13StartOfActuationCmd 1;
BA_ "SPN" SG_ 2364566526 EngGsFlVlve12StartOfActuationCmd 6689;
BA_ "SigType" SG_ 2364566526 EngGsFlVlve12StartOfActuationCmd 1;
BA_ "SPN" SG_ 2364566526 EngGsFlVlve11StartOfActuationCmd 6688;
BA_ "SigType" SG_ 2364566526 EngGsFlVlve11StartOfActuationCmd 1;
BA_ "SPN" SG_ 2364566526 EngGsFlVlve10StartOfActuationCmd 6687;
BA_ "SigType" SG_ 2364566526 EngGsFlVlve10StartOfActuationCmd 1;
BA_ "SPN" SG_ 2364566526 EngGsFlValve9StartOfActuationCmd 6686;
BA_ "SigType" SG_ 2364566526 EngGsFlValve9StartOfActuationCmd 1;
BA_ "SPN" SG_ 2364566270 EngGsFlValve8StartOfActuationCmd 6685;
BA_ "SigType" SG_ 2364566270 EngGsFlValve8StartOfActuationCmd 1;
BA_ "SPN" SG_ 2364566270 EngGsFlValve7StartOfActuationCmd 6684;
BA_ "SigType" SG_ 2364566270 EngGsFlValve7StartOfActuationCmd 1;
BA_ "SPN" SG_ 2364566270 EngGsFlValve6StartOfActuationCmd 6683;
BA_ "SigType" SG_ 2364566270 EngGsFlValve6StartOfActuationCmd 1;
BA_ "SPN" SG_ 2364566270 EngGsFlValve5StartOfActuationCmd 6682;
BA_ "SigType" SG_ 2364566270 EngGsFlValve5StartOfActuationCmd 1;
BA_ "SPN" SG_ 2364566014 EngGsFlValve4StartOfActuationCmd 6681;
BA_ "SigType" SG_ 2364566014 EngGsFlValve4StartOfActuationCmd 1;
BA_ "SPN" SG_ 2364566014 EngGsFlValve3StartOfActuationCmd 6680;
BA_ "SigType" SG_ 2364566014 EngGsFlValve3StartOfActuationCmd 1;
BA_ "SPN" SG_ 2364566014 EngGsFlValve2StartOfActuationCmd 6679;
BA_ "SigType" SG_ 2364566014 EngGsFlValve2StartOfActuationCmd 1;
BA_ "SPN" SG_ 2364566014 EngGsFlValve1StartOfActuationCmd 6678;
BA_ "SigType" SG_ 2364566014 EngGsFlValve1StartOfActuationCmd 1;
BA_ "SPN" SG_ 2364565758 EngGasFuelValve20DurationCmd 6677;
BA_ "SigType" SG_ 2364565758 EngGasFuelValve20DurationCmd 1;
BA_ "SPN" SG_ 2364565758 EngGasFuelValve19DurationCmd 6676;
BA_ "SigType" SG_ 2364565758 EngGasFuelValve19DurationCmd 1;
BA_ "SPN" SG_ 2364565758 EngGasFuelValve18DurationCmd 6675;
BA_ "SigType" SG_ 2364565758 EngGasFuelValve18DurationCmd 1;
BA_ "SPN" SG_ 2364565758 EngGasFuelValve17DurationCmd 6674;
BA_ "SigType" SG_ 2364565758 EngGasFuelValve17DurationCmd 1;
BA_ "SPN" SG_ 2364565502 EngGasFuelValve16DurationCmd 6673;
BA_ "SigType" SG_ 2364565502 EngGasFuelValve16DurationCmd 1;
BA_ "SPN" SG_ 2364565502 EngGasFuelValve15DurationCmd 6672;
BA_ "SigType" SG_ 2364565502 EngGasFuelValve15DurationCmd 1;
BA_ "SPN" SG_ 2364565502 EngGasFuelValve14DurationCmd 6671;
BA_ "SigType" SG_ 2364565502 EngGasFuelValve14DurationCmd 1;
BA_ "SPN" SG_ 2364565502 EngGasFuelValve13DurationCmd 6670;
BA_ "SigType" SG_ 2364565502 EngGasFuelValve13DurationCmd 1;
BA_ "SPN" SG_ 2364565246 EngGasFuelValve12DurationCmd 6669;
BA_ "SigType" SG_ 2364565246 EngGasFuelValve12DurationCmd 1;
BA_ "SPN" SG_ 2364565246 EngGasFuelValve11DurationCmd 6668;
BA_ "SigType" SG_ 2364565246 EngGasFuelValve11DurationCmd 1;
BA_ "SPN" SG_ 2364565246 EngGasFuelValve10DurationCmd 6667;
BA_ "SigType" SG_ 2364565246 EngGasFuelValve10DurationCmd 1;
BA_ "SPN" SG_ 2364565246 EngGasFuelValve9DurationCmd 6666;
BA_ "SigType" SG_ 2364565246 EngGasFuelValve9DurationCmd 1;
BA_ "SPN" SG_ 2364564990 EngGasFuelValve8DurationCmd 6665;
BA_ "SigType" SG_ 2364564990 EngGasFuelValve8DurationCmd 1;
BA_ "SPN" SG_ 2364564990 EngGasFuelValve7DurationCmd 6664;
BA_ "SigType" SG_ 2364564990 EngGasFuelValve7DurationCmd 1;
BA_ "SPN" SG_ 2364564990 EngGasFuelValve6DurationCmd 6663;
BA_ "SigType" SG_ 2364564990 EngGasFuelValve6DurationCmd 1;
BA_ "SPN" SG_ 2364564990 EngGasFuelValve5DurationCmd 6662;
BA_ "SigType" SG_ 2364564990 EngGasFuelValve5DurationCmd 1;
BA_ "SPN" SG_ 2364564734 EngGasFuelValve4DurationCmd 6661;
BA_ "SigType" SG_ 2364564734 EngGasFuelValve4DurationCmd 1;
BA_ "SPN" SG_ 2364564734 EngGasFuelValve3DurationCmd 6660;
BA_ "SigType" SG_ 2364564734 EngGasFuelValve3DurationCmd 1;
BA_ "SPN" SG_ 2364564734 EngGasFuelValve2DurationCmd 6659;
BA_ "SigType" SG_ 2364564734 EngGasFuelValve2DurationCmd 1;
BA_ "SPN" SG_ 2364564734 EngGasFuelValve1DurationCmd 6658;
BA_ "SigType" SG_ 2364564734 EngGasFuelValve1DurationCmd 1;
BA_ "SPN" SG_ 2364564478 EngGsFlVlvNmnlStrtOfActuationCmd 6657;
BA_ "SigType" SG_ 2364564478 EngGsFlVlvNmnlStrtOfActuationCmd 1;
BA_ "SPN" SG_ 2364564478 EngGsFuelValveNominalDurationCmd 6656;
BA_ "SigType" SG_ 2364564478 EngGsFuelValveNominalDurationCmd 1;
BA_ "SPN" SG_ 2297455358 TransDirectionalOutputShaftSpeed 6585;
BA_ "SigType" SG_ 2297455358 TransDirectionalOutputShaftSpeed 1;
BA_ "SPN" SG_ 2297455358 TransHydrostaticLoop2Press 6584;
BA_ "SigType" SG_ 2297455358 TransHydrostaticLoop2Press 1;
BA_ "SPN" SG_ 2297455358 TransHydrostaticLoop1Press 6583;
BA_ "SigType" SG_ 2297455358 TransHydrostaticLoop1Press 1;
BA_ "SPN" SG_ 2498781694 EngCyl20AvrageCombustionDuration 6562;
BA_ "SigType" SG_ 2498781694 EngCyl20AvrageCombustionDuration 1;
BA_ "SPN" SG_ 2498781694 EngCyl20AvrgCntrOfCmbstionTiming 6561;
BA_ "SigType" SG_ 2498781694 EngCyl20AvrgCntrOfCmbstionTiming 1;
BA_ "SPN" SG_ 2498781694 EngCyl20AvrgStrtOfCmbstionTiming 6560;
BA_ "SigType" SG_ 2498781694 EngCyl20AvrgStrtOfCmbstionTiming 1;
BA_ "SPN" SG_ 2498781694 EngCyl20IndctdMeanEffectivePress 6559;
BA_ "SigType" SG_ 2498781694 EngCyl20IndctdMeanEffectivePress 1;
BA_ "SPN" SG_ 2498781438 EngCyl19AvrageCombustionDuration 6558;
BA_ "SigType" SG_ 2498781438 EngCyl19AvrageCombustionDuration 1;
BA_ "SPN" SG_ 2498781438 EngCyl19AvrgCntrOfCmbstionTiming 6557;
BA_ "SigType" SG_ 2498781438 EngCyl19AvrgCntrOfCmbstionTiming 1;
BA_ "SPN" SG_ 2498781438 EngCyl19AvrgStrtOfCmbstionTiming 6556;
BA_ "SigType" SG_ 2498781438 EngCyl19AvrgStrtOfCmbstionTiming 1;
BA_ "SPN" SG_ 2498781438 EngCyl19IndctdMeanEffectivePress 6555;
BA_ "SigType" SG_ 2498781438 EngCyl19IndctdMeanEffectivePress 1;
BA_ "SPN" SG_ 2498781182 EngCyl18AvrageCombustionDuration 6554;
BA_ "SigType" SG_ 2498781182 EngCyl18AvrageCombustionDuration 1;
BA_ "SPN" SG_ 2498781182 EngCyl18AvrgCntrOfCmbstionTiming 6553;
BA_ "SigType" SG_ 2498781182 EngCyl18AvrgCntrOfCmbstionTiming 1;
BA_ "SPN" SG_ 2498781182 EngCyl18AvrgStrtOfCmbstionTiming 6552;
BA_ "SigType" SG_ 2498781182 EngCyl18AvrgStrtOfCmbstionTiming 1;
BA_ "SPN" SG_ 2498781182 EngCyl18IndctdMeanEffectivePress 6551;
BA_ "SigType" SG_ 2498781182 EngCyl18IndctdMeanEffectivePress 1;
BA_ "SPN" SG_ 2498780926 EngCyl17AvrageCombustionDuration 6550;
BA_ "SigType" SG_ 2498780926 EngCyl17AvrageCombustionDuration 1;
BA_ "SPN" SG_ 2498780926 EngCyl17AvrgCntrOfCmbstionTiming 6549;
BA_ "SigType" SG_ 2498780926 EngCyl17AvrgCntrOfCmbstionTiming 1;
BA_ "SPN" SG_ 2498780926 EngCyl17AvrgStrtOfCmbstionTiming 6548;
BA_ "SigType" SG_ 2498780926 EngCyl17AvrgStrtOfCmbstionTiming 1;
BA_ "SPN" SG_ 2498780926 EngCyl17IndctdMeanEffectivePress 6547;
BA_ "SigType" SG_ 2498780926 EngCyl17IndctdMeanEffectivePress 1;
BA_ "SPN" SG_ 2498780670 EngCyl16AvrageCombustionDuration 6546;
BA_ "SigType" SG_ 2498780670 EngCyl16AvrageCombustionDuration 1;
BA_ "SPN" SG_ 2498780670 EngCyl16AvrgCntrOfCmbstionTiming 6545;
BA_ "SigType" SG_ 2498780670 EngCyl16AvrgCntrOfCmbstionTiming 1;
BA_ "SPN" SG_ 2498780670 EngCyl16AvrgStrtOfCmbstionTiming 6544;
BA_ "SigType" SG_ 2498780670 EngCyl16AvrgStrtOfCmbstionTiming 1;
BA_ "SPN" SG_ 2498780670 EngCyl16IndctdMeanEffectivePress 6543;
BA_ "SigType" SG_ 2498780670 EngCyl16IndctdMeanEffectivePress 1;
BA_ "SPN" SG_ 2498780414 EngCyl15AvrageCombustionDuration 6542;
BA_ "SigType" SG_ 2498780414 EngCyl15AvrageCombustionDuration 1;
BA_ "SPN" SG_ 2498780414 EngCyl15AvrgCntrOfCmbstionTiming 6541;
BA_ "SigType" SG_ 2498780414 EngCyl15AvrgCntrOfCmbstionTiming 1;
BA_ "SPN" SG_ 2498780414 EngCyl15AvrgStrtOfCmbstionTiming 6540;
BA_ "SigType" SG_ 2498780414 EngCyl15AvrgStrtOfCmbstionTiming 1;
BA_ "SPN" SG_ 2498780414 EngCyl15IndctdMeanEffectivePress 6539;
BA_ "SigType" SG_ 2498780414 EngCyl15IndctdMeanEffectivePress 1;
BA_ "SPN" SG_ 2498780158 EngCyl14AvrageCombustionDuration 6538;
BA_ "SigType" SG_ 2498780158 EngCyl14AvrageCombustionDuration 1;
BA_ "SPN" SG_ 2498780158 EngCyl14AvrgCntrOfCmbstionTiming 6537;
BA_ "SigType" SG_ 2498780158 EngCyl14AvrgCntrOfCmbstionTiming 1;
BA_ "SPN" SG_ 2498780158 EngCyl14AvrgStrtOfCmbstionTiming 6536;
BA_ "SigType" SG_ 2498780158 EngCyl14AvrgStrtOfCmbstionTiming 1;
BA_ "SPN" SG_ 2498780158 EngCyl14IndctdMeanEffectivePress 6535;
BA_ "SigType" SG_ 2498780158 EngCyl14IndctdMeanEffectivePress 1;
BA_ "SPN" SG_ 2498779902 EngCyl13AvrageCombustionDuration 6534;
BA_ "SigType" SG_ 2498779902 EngCyl13AvrageCombustionDuration 1;
BA_ "SPN" SG_ 2498779902 EngCyl13AvrgCntrOfCmbstionTiming 6533;
BA_ "SigType" SG_ 2498779902 EngCyl13AvrgCntrOfCmbstionTiming 1;
BA_ "SPN" SG_ 2498779902 EngCyl13AvrgStrtOfCmbstionTiming 6532;
BA_ "SigType" SG_ 2498779902 EngCyl13AvrgStrtOfCmbstionTiming 1;
BA_ "SPN" SG_ 2498779902 EngCyl13IndctdMeanEffectivePress 6531;
BA_ "SigType" SG_ 2498779902 EngCyl13IndctdMeanEffectivePress 1;
BA_ "SPN" SG_ 2498779646 EngCyl12AvrageCombustionDuration 6530;
BA_ "SigType" SG_ 2498779646 EngCyl12AvrageCombustionDuration 1;
BA_ "SPN" SG_ 2498779646 EngCyl12AvrgCntrOfCmbstionTiming 6529;
BA_ "SigType" SG_ 2498779646 EngCyl12AvrgCntrOfCmbstionTiming 1;
BA_ "SPN" SG_ 2498779646 EngCyl12AvrgStrtOfCmbstionTiming 6528;
BA_ "SigType" SG_ 2498779646 EngCyl12AvrgStrtOfCmbstionTiming 1;
BA_ "SPN" SG_ 2498779646 EngCyl12IndctdMeanEffectivePress 6527;
BA_ "SigType" SG_ 2498779646 EngCyl12IndctdMeanEffectivePress 1;
BA_ "SPN" SG_ 2498779390 EngCyl11AvrageCombustionDuration 6526;
BA_ "SigType" SG_ 2498779390 EngCyl11AvrageCombustionDuration 1;
BA_ "SPN" SG_ 2498779390 EngCyl11AvrgCntrOfCmbstionTiming 6525;
BA_ "SigType" SG_ 2498779390 EngCyl11AvrgCntrOfCmbstionTiming 1;
BA_ "SPN" SG_ 2498779390 EngCyl11AvrgStrtOfCmbstionTiming 6524;
BA_ "SigType" SG_ 2498779390 EngCyl11AvrgStrtOfCmbstionTiming 1;
BA_ "SPN" SG_ 2498779390 EngCyl11IndctdMeanEffectivePress 6523;
BA_ "SigType" SG_ 2498779390 EngCyl11IndctdMeanEffectivePress 1;
BA_ "SPN" SG_ 2498779134 EngCyl10AvrageCombustionDuration 6522;
BA_ "SigType" SG_ 2498779134 EngCyl10AvrageCombustionDuration 1;
BA_ "SPN" SG_ 2498779134 EngCyl10AvrgCntrOfCmbstionTiming 6521;
BA_ "SigType" SG_ 2498779134 EngCyl10AvrgCntrOfCmbstionTiming 1;
BA_ "SPN" SG_ 2498779134 EngCyl10AvrgStrtOfCmbstionTiming 6520;
BA_ "SigType" SG_ 2498779134 EngCyl10AvrgStrtOfCmbstionTiming 1;
BA_ "SPN" SG_ 2498779134 EngCyl10IndctdMeanEffectivePress 6519;
BA_ "SigType" SG_ 2498779134 EngCyl10IndctdMeanEffectivePress 1;
BA_ "SPN" SG_ 2498778878 EngCyl9AverageCombustionDuration 6518;
BA_ "SigType" SG_ 2498778878 EngCyl9AverageCombustionDuration 1;
BA_ "SPN" SG_ 2498778878 EngCyl9AvrgCntrOfCmbustionTiming 6517;
BA_ "SigType" SG_ 2498778878 EngCyl9AvrgCntrOfCmbustionTiming 1;
BA_ "SPN" SG_ 2498778878 EngCyl9AvrgStrtOfCmbustionTiming 6516;
BA_ "SigType" SG_ 2498778878 EngCyl9AvrgStrtOfCmbustionTiming 1;
BA_ "SPN" SG_ 2498778878 EngCyl9IndctedMeanEffectivePress 6515;
BA_ "SigType" SG_ 2498778878 EngCyl9IndctedMeanEffectivePress 1;
BA_ "SPN" SG_ 2365428734 GenFrequencySelection 4080;
BA_ "SPN" SG_ 2365428734 GenGoverningSpeedCommand 4079;
BA_ "SigType" SG_ 2365428734 GenGoverningSpeedCommand 5;
BA_ "SPN" SG_ 2365428734 GenAlternatorEfficiency 4078;
BA_ "SigType" SG_ 2365428734 GenAlternatorEfficiency 1;
BA_ "SPN" SG_ 2365428734 GenNotReadyToAutoParaState 3568;
BA_ "SigType" SG_ 2365428734 GenNotReadyToAutoParaState 5;
BA_ "SPN" SG_ 2365428734 GenCtrlNotInAutoStartState 3567;
BA_ "SigType" SG_ 2365428734 GenCtrlNotInAutoStartState 5;
BA_ "SPN" SG_ 2365428734 RequestedEngineControlMode 3542;
BA_ "SigType" SG_ 2365428734 RequestedEngineControlMode 4;
BA_ "SPN" SG_ 2365428734 EngSpeedGovernorDroop 5568;
BA_ "SigType" SG_ 2365428734 EngSpeedGovernorDroop 1;
BA_ "SPN" SG_ 2365428734 EngSpeedGovernorGainAdjust 5567;
BA_ "SigType" SG_ 2365428734 EngSpeedGovernorGainAdjust 1;
BA_ "SPN" SG_ 2566702846 EngOBDWarmUpSequence 5843;
BA_ "SigType" SG_ 2566702846 EngOBDWarmUpSequence 5;
BA_ "SPN" SG_ 2566703102 CertificationEngineFamilyName 5845;
BA_ "SPN" SG_ 2566703102 ModelYear 5844;
BA_ "SigType" SG_ 2566703102 ModelYear 3;
BA_ "SigType" SG_ 2566705918 DTC1 7;
BA_ "SPN" SG_ 2566705918 FlashProtectLamp 3041;
BA_ "SigType" SG_ 2566705918 FlashProtectLamp 5;
BA_ "SPN" SG_ 2566705918 FlashAmberWarningLamp 3040;
BA_ "SigType" SG_ 2566705918 FlashAmberWarningLamp 5;
BA_ "SPN" SG_ 2566705918 FlashRedStopLamp 3039;
BA_ "SigType" SG_ 2566705918 FlashRedStopLamp 5;
BA_ "SPN" SG_ 2566705918 FlashMalfuncIndicatorLamp 3038;
BA_ "SigType" SG_ 2566705918 FlashMalfuncIndicatorLamp 5;
BA_ "SPN" SG_ 2566705918 ProtectLampStatus 987;
BA_ "SigType" SG_ 2566705918 ProtectLampStatus 5;
BA_ "SPN" SG_ 2566705918 AmberWarningLampStatus 624;
BA_ "SigType" SG_ 2566705918 AmberWarningLampStatus 5;
BA_ "SPN" SG_ 2566705918 RedStopLampState 623;
BA_ "SigType" SG_ 2566705918 RedStopLampState 4;
BA_ "SPN" SG_ 2566705918 MalfunctionIndicatorLampStatus 1213;
BA_ "SigType" SG_ 2566705918 MalfunctionIndicatorLampStatus 5;
BA_ "SigType" SG_ 2566705918 DTC5 7;
BA_ "SigType" SG_ 2566705918 DTC4 7;
BA_ "SigType" SG_ 2566705918 DTC3 7;
BA_ "SigType" SG_ 2566705918 DTC2 7;
BA_ "SigType" SG_ 2566705662 DTC1 7;
BA_ "SPN" SG_ 2566705662 FlashProtectLamp 3041;
BA_ "SigType" SG_ 2566705662 FlashProtectLamp 5;
BA_ "SPN" SG_ 2566705662 FlashAmberWarningLamp 3040;
BA_ "SigType" SG_ 2566705662 FlashAmberWarningLamp 5;
BA_ "SPN" SG_ 2566705662 FlashRedStopLamp 3039;
BA_ "SigType" SG_ 2566705662 FlashRedStopLamp 5;
BA_ "SPN" SG_ 2566705662 FlashMalfuncIndicatorLamp 3038;
BA_ "SigType" SG_ 2566705662 FlashMalfuncIndicatorLamp 5;
BA_ "SPN" SG_ 2566705662 ProtectLampStatus 987;
BA_ "SigType" SG_ 2566705662 ProtectLampStatus 5;
BA_ "SPN" SG_ 2566705662 AmberWarningLampStatus 624;
BA_ "SigType" SG_ 2566705662 AmberWarningLampStatus 5;
BA_ "SPN" SG_ 2566705662 RedStopLampState 623;
BA_ "SigType" SG_ 2566705662 RedStopLampState 4;
BA_ "SPN" SG_ 2566705662 MalfunctionIndicatorLampStatus 1213;
BA_ "SigType" SG_ 2566705662 MalfunctionIndicatorLampStatus 5;
BA_ "SigType" SG_ 2566705662 DTC5 7;
BA_ "SigType" SG_ 2566705662 DTC4 7;
BA_ "SigType" SG_ 2566705662 DTC3 7;
BA_ "SigType" SG_ 2566705662 DTC2 7;
BA_ "SPN" SG_ 2349465342 StaticRollAngleStatus 5583;
BA_ "SPN" SG_ 2349465342 StaticRollAngle 5582;
BA_ "GenSigStartValue" SG_ 2349465342 StaticRollAngle 35;
BA_ "SigType" SG_ 2349465342 StaticRollAngle 1;
BA_ "SPN" SG_ 2498777086 EngCyl2AverageCombustionDuration 6490;
BA_ "SigType" SG_ 2498777086 EngCyl2AverageCombustionDuration 1;
BA_ "SPN" SG_ 2498777086 EngCyl2AvrgCntrOfCmbustionTiming 6489;
BA_ "SigType" SG_ 2498777086 EngCyl2AvrgCntrOfCmbustionTiming 1;
BA_ "SPN" SG_ 2498777086 EngCyl2AvrgStrtOfCmbustionTiming 6488;
BA_ "SigType" SG_ 2498777086 EngCyl2AvrgStrtOfCmbustionTiming 1;
BA_ "SPN" SG_ 2498777086 EngCyl2IndctedMeanEffectivePress 6487;
BA_ "SigType" SG_ 2498777086 EngCyl2IndctedMeanEffectivePress 1;
BA_ "SPN" SG_ 2498776830 EngCyl1AverageCombustionDuration 6486;
BA_ "SigType" SG_ 2498776830 EngCyl1AverageCombustionDuration 1;
BA_ "SPN" SG_ 2498776830 EngCyl1AvrgCntrOfCmbustionTiming 6485;
BA_ "SigType" SG_ 2498776830 EngCyl1AvrgCntrOfCmbustionTiming 1;
BA_ "SPN" SG_ 2498776830 EngCyl1AvrgStrtOfCmbustionTiming 6484;
BA_ "SigType" SG_ 2498776830 EngCyl1AvrgStrtOfCmbustionTiming 1;
BA_ "SPN" SG_ 2498776830 EngCyl1IndctedMeanEffectivePress 6483;
BA_ "SigType" SG_ 2498776830 EngCyl1IndctedMeanEffectivePress 1;
BA_ "SPN" SG_ 2364558846 MaxPressIncreaseRate 7648;
BA_ "SigType" SG_ 2364558846 MaxPressIncreaseRate 1;
BA_ "SPN" SG_ 2364558846 LowFreqKnockLvl 7628;
BA_ "SigType" SG_ 2364558846 LowFreqKnockLvl 1;
BA_ "SPN" SG_ 2364558846 EngCyl20PrssSensorPreliminaryFMI 6475;
BA_ "SPN" SG_ 2364558846 EngCyl20SynchronousKnockLevel 6474;
BA_ "SigType" SG_ 2364558846 EngCyl20SynchronousKnockLevel 1;
BA_ "SPN" SG_ 2364558846 EngCyl20PeakPress 6473;
BA_ "SigType" SG_ 2364558846 EngCyl20PeakPress 1;
BA_ "SPN" SG_ 2364558846 EngCyl20HeatRelease 6472;
BA_ "SigType" SG_ 2364558846 EngCyl20HeatRelease 1;
BA_ "SPN" SG_ 2364558590 MaxPressIncreaseRate 7647;
BA_ "SigType" SG_ 2364558590 MaxPressIncreaseRate 1;
BA_ "SPN" SG_ 2364558590 LowFreqKnockLvl 7627;
BA_ "SigType" SG_ 2364558590 LowFreqKnockLvl 1;
BA_ "SPN" SG_ 2364558590 EngCyl19PrssSensorPreliminaryFMI 6471;
BA_ "SPN" SG_ 2364558590 EngCyl19SynchronousKnockLevel 6470;
BA_ "SigType" SG_ 2364558590 EngCyl19SynchronousKnockLevel 1;
BA_ "SPN" SG_ 2364558590 EngCyl19PeakPress 6469;
BA_ "SigType" SG_ 2364558590 EngCyl19PeakPress 1;
BA_ "SPN" SG_ 2364558590 EngCyl19HeatRelease 6468;
BA_ "SigType" SG_ 2364558590 EngCyl19HeatRelease 1;
BA_ "SPN" SG_ 2364558334 MaxPressIncreaseRate 7646;
BA_ "SigType" SG_ 2364558334 MaxPressIncreaseRate 1;
BA_ "SPN" SG_ 2364558334 LowFreqKnockLvl 7626;
BA_ "SigType" SG_ 2364558334 LowFreqKnockLvl 1;
BA_ "SPN" SG_ 2364558334 EngCyl18PrssSensorPreliminaryFMI 6467;
BA_ "SPN" SG_ 2364558334 EngCyl18SynchronousKnockLevel 6466;
BA_ "SigType" SG_ 2364558334 EngCyl18SynchronousKnockLevel 1;
BA_ "SPN" SG_ 2364558334 EngCyl18PeakPress 6465;
BA_ "SigType" SG_ 2364558334 EngCyl18PeakPress 1;
BA_ "SPN" SG_ 2364558334 EngCyl18HeatRelease 6464;
BA_ "SigType" SG_ 2364558334 EngCyl18HeatRelease 1;
BA_ "SPN" SG_ 2364558078 MaxPressIncreaseRate 7645;
BA_ "SigType" SG_ 2364558078 MaxPressIncreaseRate 1;
BA_ "SPN" SG_ 2364558078 LowFreqKnockLvl 7625;
BA_ "SigType" SG_ 2364558078 LowFreqKnockLvl 1;
BA_ "SPN" SG_ 2364558078 EngCyl17PrssSensorPreliminaryFMI 6463;
BA_ "SPN" SG_ 2364558078 EngCyl17SynchronousKnockLevel 6462;
BA_ "SigType" SG_ 2364558078 EngCyl17SynchronousKnockLevel 1;
BA_ "SPN" SG_ 2364558078 EngCyl17PeakPress 6461;
BA_ "SigType" SG_ 2364558078 EngCyl17PeakPress 1;
BA_ "SPN" SG_ 2364558078 EngCyl17HeatRelease 6460;
BA_ "SigType" SG_ 2364558078 EngCyl17HeatRelease 1;
BA_ "SPN" SG_ 2364557822 MaxPressIncreaseRate 7644;
BA_ "SigType" SG_ 2364557822 MaxPressIncreaseRate 1;
BA_ "SPN" SG_ 2364557822 LowFreqKnockLvl 7624;
BA_ "SigType" SG_ 2364557822 LowFreqKnockLvl 1;
BA_ "SPN" SG_ 2364557822 EngCyl16PrssSensorPreliminaryFMI 6459;
BA_ "SPN" SG_ 2364557822 EngCyl16SynchronousKnockLevel 6458;
BA_ "SigType" SG_ 2364557822 EngCyl16SynchronousKnockLevel 1;
BA_ "SPN" SG_ 2364557822 EngCyl16PeakPress 6457;
BA_ "SigType" SG_ 2364557822 EngCyl16PeakPress 1;
BA_ "SPN" SG_ 2364557822 EngCyl16HeatRelease 6456;
BA_ "SigType" SG_ 2364557822 EngCyl16HeatRelease 1;
BA_ "SPN" SG_ 2364557566 MaxPressIncreaseRate 7643;
BA_ "SigType" SG_ 2364557566 MaxPressIncreaseRate 1;
BA_ "SPN" SG_ 2364557566 LowFreqKnockLvl 7623;
BA_ "SigType" SG_ 2364557566 LowFreqKnockLvl 1;
BA_ "SPN" SG_ 2364557566 EngCyl15PrssSensorPreliminaryFMI 6455;
BA_ "SPN" SG_ 2364557566 EngCyl15SynchronousKnockLevel 6454;
BA_ "SigType" SG_ 2364557566 EngCyl15SynchronousKnockLevel 1;
BA_ "SPN" SG_ 2364557566 EngCyl15PeakPress 6453;
BA_ "SigType" SG_ 2364557566 EngCyl15PeakPress 1;
BA_ "SPN" SG_ 2364557566 EngCyl15HeatRelease 6452;
BA_ "SigType" SG_ 2364557566 EngCyl15HeatRelease 1;
BA_ "SPN" SG_ 2364557310 MaxPressIncreaseRate 7642;
BA_ "SigType" SG_ 2364557310 MaxPressIncreaseRate 1;
BA_ "SPN" SG_ 2364557310 LowFreqKnockLvl 7622;
BA_ "SigType" SG_ 2364557310 LowFreqKnockLvl 1;
BA_ "SPN" SG_ 2364557310 EngCyl14PrssSensorPreliminaryFMI 6451;
BA_ "SPN" SG_ 2364557310 EngCyl14SynchronousKnockLevel 6450;
BA_ "SigType" SG_ 2364557310 EngCyl14SynchronousKnockLevel 1;
BA_ "SPN" SG_ 2364557310 EngCyl14PeakPress 6449;
BA_ "SigType" SG_ 2364557310 EngCyl14PeakPress 1;
BA_ "SPN" SG_ 2364557310 EngCyl14HeatRelease 6448;
BA_ "SigType" SG_ 2364557310 EngCyl14HeatRelease 1;
BA_ "SPN" SG_ 2364557054 MaxPressIncreaseRate 7641;
BA_ "SigType" SG_ 2364557054 MaxPressIncreaseRate 1;
BA_ "SPN" SG_ 2364557054 LowFreqKnockLvl 7621;
BA_ "SigType" SG_ 2364557054 LowFreqKnockLvl 1;
BA_ "SPN" SG_ 2364557054 EngCyl13PrssSensorPreliminaryFMI 6447;
BA_ "SPN" SG_ 2364557054 EngCyl13SynchronousKnockLevel 6446;
BA_ "SigType" SG_ 2364557054 EngCyl13SynchronousKnockLevel 1;
BA_ "SPN" SG_ 2364557054 EngCyl13PeakPress 6445;
BA_ "SigType" SG_ 2364557054 EngCyl13PeakPress 1;
BA_ "SPN" SG_ 2364557054 EngCyl13HeatRelease 6444;
BA_ "SigType" SG_ 2364557054 EngCyl13HeatRelease 1;
BA_ "SPN" SG_ 2364556798 MaxPressIncreaseRate 7640;
BA_ "SigType" SG_ 2364556798 MaxPressIncreaseRate 1;
BA_ "SPN" SG_ 2364556798 LowFreqKnockLvl 7620;
BA_ "SigType" SG_ 2364556798 LowFreqKnockLvl 1;
BA_ "SPN" SG_ 2364556798 EngCyl12PrssSensorPreliminaryFMI 6443;
BA_ "SPN" SG_ 2364556798 EngCyl12SynchronousKnockLevel 6442;
BA_ "SigType" SG_ 2364556798 EngCyl12SynchronousKnockLevel 1;
BA_ "SPN" SG_ 2364556798 EngCyl12PeakPress 6441;
BA_ "SigType" SG_ 2364556798 EngCyl12PeakPress 1;
BA_ "SPN" SG_ 2364556798 EngCyl12HeatRelease 6440;
BA_ "SigType" SG_ 2364556798 EngCyl12HeatRelease 1;
BA_ "SPN" SG_ 2364556542 MaxPressIncreaseRate 7639;
BA_ "SigType" SG_ 2364556542 MaxPressIncreaseRate 1;
BA_ "SPN" SG_ 2364556542 LowFreqKnockLvl 7619;
BA_ "SigType" SG_ 2364556542 LowFreqKnockLvl 1;
BA_ "SPN" SG_ 2364556542 EngCyl11PrssSensorPreliminaryFMI 6439;
BA_ "SPN" SG_ 2364556542 EngCyl11SynchronousKnockLevel 6438;
BA_ "SigType" SG_ 2364556542 EngCyl11SynchronousKnockLevel 1;
BA_ "SPN" SG_ 2364556542 EngCyl11PeakPress 6437;
BA_ "SigType" SG_ 2364556542 EngCyl11PeakPress 1;
BA_ "SPN" SG_ 2364556542 EngCyl11HeatRelease 6436;
BA_ "SigType" SG_ 2364556542 EngCyl11HeatRelease 1;
BA_ "SPN" SG_ 2364556286 MaxPressIncreaseRate 7638;
BA_ "SigType" SG_ 2364556286 MaxPressIncreaseRate 1;
BA_ "SPN" SG_ 2364556286 LowFreqKnockLvl 7618;
BA_ "SigType" SG_ 2364556286 LowFreqKnockLvl 1;
BA_ "SPN" SG_ 2364556286 EngCyl10PrssSensorPreliminaryFMI 6435;
BA_ "SPN" SG_ 2364556286 EngCyl10SynchronousKnockLevel 6434;
BA_ "SigType" SG_ 2364556286 EngCyl10SynchronousKnockLevel 1;
BA_ "SPN" SG_ 2364556286 EngCyl10PeakPress 6433;
BA_ "SigType" SG_ 2364556286 EngCyl10PeakPress 1;
BA_ "SPN" SG_ 2364556286 EngCyl10HeatRelease 6432;
BA_ "SigType" SG_ 2364556286 EngCyl10HeatRelease 1;
BA_ "SPN" SG_ 2364556030 MaxPressIncreaseRate 7637;
BA_ "SigType" SG_ 2364556030 MaxPressIncreaseRate 1;
BA_ "SPN" SG_ 2364556030 LowFreqKnockLvl 7617;
BA_ "SigType" SG_ 2364556030 LowFreqKnockLvl 1;
BA_ "SPN" SG_ 2364556030 EngCyl9PressSensorPreliminaryFMI 6431;
BA_ "SPN" SG_ 2364556030 EngCyl9SynchronousKnockLevel 6430;
BA_ "SigType" SG_ 2364556030 EngCyl9SynchronousKnockLevel 1;
BA_ "SPN" SG_ 2364556030 EngCyl9PeakPress 6429;
BA_ "SigType" SG_ 2364556030 EngCyl9PeakPress 1;
BA_ "SPN" SG_ 2364556030 EngCyl9HeatRelease 6428;
BA_ "SigType" SG_ 2364556030 EngCyl9HeatRelease 1;
BA_ "SPN" SG_ 2364555774 MaxPressIncreaseRate 7636;
BA_ "SigType" SG_ 2364555774 MaxPressIncreaseRate 1;
BA_ "SPN" SG_ 2364555774 LowFreqKnockLvl 7616;
BA_ "SigType" SG_ 2364555774 LowFreqKnockLvl 1;
BA_ "SPN" SG_ 2364555774 EngCyl8PressSensorPreliminaryFMI 6427;
BA_ "SPN" SG_ 2364555774 EngCyl8SynchronousKnockLevel 6426;
BA_ "SigType" SG_ 2364555774 EngCyl8SynchronousKnockLevel 1;
BA_ "SPN" SG_ 2364555774 EngCyl8PeakPress 6425;
BA_ "SigType" SG_ 2364555774 EngCyl8PeakPress 1;
BA_ "SPN" SG_ 2364555774 EngCyl8HeatRelease 6424;
BA_ "SigType" SG_ 2364555774 EngCyl8HeatRelease 1;
BA_ "SPN" SG_ 2364555518 MaxPressIncreaseRate 7635;
BA_ "SigType" SG_ 2364555518 MaxPressIncreaseRate 1;
BA_ "SPN" SG_ 2364555518 LowFreqKnockLvl 7615;
BA_ "SigType" SG_ 2364555518 LowFreqKnockLvl 1;
BA_ "SPN" SG_ 2364555518 EngCyl7PressSensorPreliminaryFMI 6423;
BA_ "SPN" SG_ 2364555518 EngCyl7SynchronousKnockLevel 6422;
BA_ "SigType" SG_ 2364555518 EngCyl7SynchronousKnockLevel 1;
BA_ "SPN" SG_ 2364555518 EngCyl7PeakPress 6421;
BA_ "SigType" SG_ 2364555518 EngCyl7PeakPress 1;
BA_ "SPN" SG_ 2364555518 EngCyl7HeatRelease 6420;
BA_ "SigType" SG_ 2364555518 EngCyl7HeatRelease 1;
BA_ "SPN" SG_ 2364555262 MaxPressIncreaseRate 7634;
BA_ "SigType" SG_ 2364555262 MaxPressIncreaseRate 1;
BA_ "SPN" SG_ 2364555262 LowFreqKnockLvl 7614;
BA_ "SigType" SG_ 2364555262 LowFreqKnockLvl 1;
BA_ "SPN" SG_ 2364555262 EngCyl6PressSensorPreliminaryFMI 6419;
BA_ "SPN" SG_ 2364555262 EngCyl6SynchronousKnockLevel 6418;
BA_ "SigType" SG_ 2364555262 EngCyl6SynchronousKnockLevel 1;
BA_ "SPN" SG_ 2364555262 EngCyl6PeakPress 6417;
BA_ "SigType" SG_ 2364555262 EngCyl6PeakPress 1;
BA_ "SPN" SG_ 2364555262 EngCyl6HeatRelease 6416;
BA_ "SigType" SG_ 2364555262 EngCyl6HeatRelease 1;
BA_ "SPN" SG_ 2364555006 MaxPressIncreaseRate 7633;
BA_ "SigType" SG_ 2364555006 MaxPressIncreaseRate 1;
BA_ "SPN" SG_ 2364555006 LowFreqKnockLvl 7613;
BA_ "SigType" SG_ 2364555006 LowFreqKnockLvl 1;
BA_ "SPN" SG_ 2364555006 EngCyl5PressSensorPreliminaryFMI 6415;
BA_ "SPN" SG_ 2364555006 EngCyl5SynchronousKnockLevel 6414;
BA_ "SigType" SG_ 2364555006 EngCyl5SynchronousKnockLevel 1;
BA_ "SPN" SG_ 2364555006 EngCyl5PeakPress 6413;
BA_ "SigType" SG_ 2364555006 EngCyl5PeakPress 1;
BA_ "SPN" SG_ 2364555006 EngCyl5HeatRelease 6412;
BA_ "SigType" SG_ 2364555006 EngCyl5HeatRelease 1;
BA_ "SPN" SG_ 2364554750 MaxPressIncreaseRate 7632;
BA_ "SigType" SG_ 2364554750 MaxPressIncreaseRate 1;
BA_ "SPN" SG_ 2364554750 LowFreqKnockLvl 7612;
BA_ "SigType" SG_ 2364554750 LowFreqKnockLvl 1;
BA_ "SPN" SG_ 2364554750 EngCyl4PressSensorPreliminaryFMI 6411;
BA_ "SPN" SG_ 2364554750 EngCyl4SynchronousKnockLevel 6410;
BA_ "SigType" SG_ 2364554750 EngCyl4SynchronousKnockLevel 1;
BA_ "SPN" SG_ 2364554750 EngCyl4PeakPress 6409;
BA_ "SigType" SG_ 2364554750 EngCyl4PeakPress 1;
BA_ "SPN" SG_ 2364554750 EngCyl4HeatRelease 6408;
BA_ "SigType" SG_ 2364554750 EngCyl4HeatRelease 1;
BA_ "SPN" SG_ 2364554494 MaxPressIncreaseRate 7631;
BA_ "SigType" SG_ 2364554494 MaxPressIncreaseRate 1;
BA_ "SPN" SG_ 2364554494 LowFreqKnockLvl 7611;
BA_ "SigType" SG_ 2364554494 LowFreqKnockLvl 1;
BA_ "SPN" SG_ 2364554494 EngCyl3PressSensorPreliminaryFMI 6407;
BA_ "SPN" SG_ 2364554494 EngCyl3SynchronousKnockLevel 6406;
BA_ "SigType" SG_ 2364554494 EngCyl3SynchronousKnockLevel 1;
BA_ "SPN" SG_ 2364554494 EngCyl3PeakPress 6405;
BA_ "SigType" SG_ 2364554494 EngCyl3PeakPress 1;
BA_ "SPN" SG_ 2364554494 EngCyl3HeatRelease 6404;
BA_ "SigType" SG_ 2364554494 EngCyl3HeatRelease 1;
BA_ "SPN" SG_ 2364554238 MaxPressIncreaseRate 7630;
BA_ "SigType" SG_ 2364554238 MaxPressIncreaseRate 1;
BA_ "SPN" SG_ 2364554238 LowFreqKnockLvl 7610;
BA_ "SigType" SG_ 2364554238 LowFreqKnockLvl 1;
BA_ "SPN" SG_ 2364554238 EngCyl2PressSensorPreliminaryFMI 6403;
BA_ "SPN" SG_ 2364554238 EngCyl2SynchronousKnockLevel 6402;
BA_ "SigType" SG_ 2364554238 EngCyl2SynchronousKnockLevel 1;
BA_ "SPN" SG_ 2364554238 EngCyl2PeakPress 6401;
BA_ "SigType" SG_ 2364554238 EngCyl2PeakPress 1;
BA_ "SPN" SG_ 2364554238 EngCyl2HeatRelease 6400;
BA_ "SigType" SG_ 2364554238 EngCyl2HeatRelease 1;
BA_ "SPN" SG_ 2364553982 MaxPressIncreaseRate 7629;
BA_ "SigType" SG_ 2364553982 MaxPressIncreaseRate 1;
BA_ "SPN" SG_ 2364553982 LowFreqKnockLvl 7609;
BA_ "SigType" SG_ 2364553982 LowFreqKnockLvl 1;
BA_ "SPN" SG_ 2364553982 EngCyl1PressSensorPreliminaryFMI 6399;
BA_ "SPN" SG_ 2364553982 EngCyl1SynchronousKnockLevel 6398;
BA_ "SigType" SG_ 2364553982 EngCyl1SynchronousKnockLevel 1;
BA_ "SPN" SG_ 2364553982 EngCyl1PeakPress 6397;
BA_ "SigType" SG_ 2364553982 EngCyl1PeakPress 1;
BA_ "SPN" SG_ 2364553982 EngCyl1HeatRelease 6396;
BA_ "SigType" SG_ 2364553982 EngCyl1HeatRelease 1;
BA_ "SPN" SG_ 2364553726 EngTotalIntakeMassAirFlowRate 6393;
BA_ "SigType" SG_ 2364553726 EngTotalIntakeMassAirFlowRate 1;
BA_ "SPN" SG_ 2364553726 EngDesiredAirFuelRatio 6392;
BA_ "SigType" SG_ 2364553726 EngDesiredAirFuelRatio 1;
BA_ "SPN" SG_ 2364553470 EngCylTorque 6389;
BA_ "SigType" SG_ 2364553470 EngCylTorque 1;
BA_ "SPN" SG_ 2364553470 EngCylDieselMassFlowRateCmd 6388;
BA_ "SigType" SG_ 2364553470 EngCylDieselMassFlowRateCmd 1;
BA_ "SPN" SG_ 2364553470 EngCylGasMassFlowRateCmd 6387;
BA_ "SigType" SG_ 2364553470 EngCylGasMassFlowRateCmd 1;
BA_ "SPN" SG_ 2364553470 EngGasFuelPercentageCmd 6386;
BA_ "SigType" SG_ 2364553470 EngGasFuelPercentageCmd 1;
BA_ "SPN" SG_ 2364553470 EngDualFuelModeCmd 6792;
BA_ "SigType" SG_ 2364553470 EngDualFuelModeCmd 5;
BA_ "SPN" SG_ 2364553214 EngTrbCmprssrBlwffActtr1OprtnStt 6316;
BA_ "SPN" SG_ 2364553214 EngTrbCmprssrBlowoffActuator1Pos 6315;
BA_ "SigType" SG_ 2364553214 EngTrbCmprssrBlowoffActuator1Pos 1;
BA_ "SPN" SG_ 2364553214 EngTrbCmprssrBlwffActtr1DsredPos 6314;
BA_ "SigType" SG_ 2364553214 EngTrbCmprssrBlwffActtr1DsredPos 1;
BA_ "SPN" SG_ 2364553214 EngTrbCmprssrBlwoffActuator1Temp 6313;
BA_ "SigType" SG_ 2364553214 EngTrbCmprssrBlwoffActuator1Temp 1;
BA_ "SPN" SG_ 2364553214 EngTrbCmprssrBlwffActtr1TmpSttus 6312;
BA_ "SPN" SG_ 2364553214 EngTrbCmprssrBlwffActtr1PrlmnryF 6311;
BA_ "SPN" SG_ 2565874430 PersistentLimitStatus 4307;
BA_ "SPN" SG_ 2565874430 MachineSelectedSpeedSource 4308;
BA_ "SPN" SG_ 2565874430 MachineSelectedDirection 4309;
BA_ "SigType" SG_ 2565874430 MachineSelectedDirection 4;
BA_ "SPN" SG_ 2565874430 MachineSelectedDistance 4306;
BA_ "SPN" SG_ 2565874430 MachineSelectedSpeed 4305;
BA_ "SPN" SG_ 2364546814 GeneratorGoverningBias 3938;
BA_ "SigType" SG_ 2364546814 GeneratorGoverningBias 1;
BA_ "SPN" SG_ 2566767614 AccelPedal2Channel3 2626;
BA_ "SigType" SG_ 2566767614 AccelPedal2Channel3 1;
BA_ "SPN" SG_ 2566767614 AccelPedal2Channel2 2625;
BA_ "SigType" SG_ 2566767614 AccelPedal2Channel2 1;
BA_ "SPN" SG_ 2566767614 AccelPedal1Channel3 2624;
BA_ "SigType" SG_ 2566767614 AccelPedal1Channel3 1;
BA_ "SPN" SG_ 2566767614 AccelPedal1Channel2 2623;
BA_ "SigType" SG_ 2566767614 AccelPedal1Channel2 1;
BA_ "SPN" SG_ 2559049470 DesiredEngFuelingState 5793;
BA_ "SigType" SG_ 2559049470 DesiredEngFuelingState 5;
BA_ "SPN" SG_ 2559049470 RequestedFuelType 6317;
BA_ "SPN" SG_ 2559049470 EngGasFuelSupplyDesiredPress 6715;
BA_ "SigType" SG_ 2559049470 EngGasFuelSupplyDesiredPress 1;
BA_ "SPN" SG_ 2559049470 EngGasFuelUsageInhibited 6833;
BA_ "SigType" SG_ 2559049470 EngGasFuelUsageInhibited 4;
BA_ "SPN" SG_ 2349596414 AEBS2MessageChecksum 5683;
BA_ "SigType" SG_ 2349596414 AEBS2MessageChecksum 12;
BA_ "SPN" SG_ 2349596414 AEBS2MessageCounter 5682;
BA_ "SigType" SG_ 2349596414 AEBS2MessageCounter 11;
BA_ "SPN" SG_ 2349596414 DrvrActvtnDmndFrAdvncdEmrgncyBrk 5681;
BA_ "SigType" SG_ 2349596414 DrvrActvtnDmndFrAdvncdEmrgncyBrk 5;
BA_ "SPN" SG_ 2563571454 DataDictionaryRow 2427;
BA_ "SPN" SG_ 2563571454 DataDictionaryColumn 2428;
BA_ "SPN" SG_ 2563571454 ImplementType 2425;
BA_ "SPN" SG_ 2563571454 ImplementPos 2426;
BA_ "SPN" SG_ 2563571454 DataFormat_ErrorCondition 2419;
BA_ "SigType" SG_ 2563571454 DataFormat_ErrorCondition 4;
BA_ "SPN" SG_ 2563571454 ProcessDataType 2420;
BA_ "SigType" SG_ 2563571454 ProcessDataType 4;
BA_ "SPN" SG_ 2563571454 ProcessDataModifier 2421;
BA_ "SPN" SG_ 2563571454 RepetitionRateParameter 2418;
BA_ "SPN" SG_ 2563505918 ProcessVariableValue 2429;
BA_ "SPN" SG_ 2563505918 DataDictionaryRow 2427;
BA_ "SPN" SG_ 2563505918 DataDictionaryColumn 2428;
BA_ "SPN" SG_ 2563505918 ImplementType 2425;
BA_ "SPN" SG_ 2563505918 ImplementPos 2426;
BA_ "SPN" SG_ 2563505918 CountNumber 2422;
BA_ "SPN" SG_ 2563505918 DataFormat_ErrorCondition 2419;
BA_ "SigType" SG_ 2563505918 DataFormat_ErrorCondition 4;
BA_ "SPN" SG_ 2563505918 ProcessDataType 2420;
BA_ "SigType" SG_ 2563505918 ProcessDataType 4;
BA_ "SPN" SG_ 2563505918 ProcessDataModifier 2421;
BA_ "SPN" SG_ 2563178238 ValveFailSafeMode 2934;
BA_ "SigType" SG_ 2563178238 ValveFailSafeMode 4;
BA_ "SPN" SG_ 2563178238 ValveState 2932;
BA_ "SPN" SG_ 2563178238 RetractPortEstFlow 2940;
BA_ "SPN" SG_ 2563178238 ExtendPortEstFlow 2939;
BA_ "SPN" SG_ 2563112702 ReturnPortPress 2943;
BA_ "SPN" SG_ 2563112702 RetractPortPress 2942;
BA_ "SPN" SG_ 2563112702 ExtendPortPress 2941;
BA_ "SPN" SG_ 2563112702 RetractPortMeasuredFlow 2938;
BA_ "SPN" SG_ 2563112702 ExtendPortMeasuredFlow 2937;
BA_ "SPN" SG_ 2563047166 PortFlowCmd 2944;
VAL_ 2566692094 Joystick1Lamp10Status 3 "Not available" 2 "Flashing" 1 "On" 0 "Off" ;
VAL_ 2566692094 Joystick1Lamp9Status 3 "Not available" 2 "Flashing" 1 "On" 0 "Off" ;
VAL_ 2566692094 Joystick1Lamp8Status 3 "Not available" 2 "Flashing" 1 "On" 0 "Off" ;
VAL_ 2566692094 Joystick1Lamp7Status 3 "Not available" 2 "Flashing" 1 "On" 0 "Off" ;
VAL_ 2566692094 Joystick1Lamp6Status 3 "Not available" 2 "Flashing" 1 "On" 0 "Off" ;
VAL_ 2566692094 Joystick1Lamp5Status 3 "Not available" 2 "Flashing" 1 "On" 0 "Off" ;
VAL_ 2566692094 Joystick1Lamp4Status 3 "Not available" 2 "Flashing" 1 "On" 0 "Off" ;
VAL_ 2566692094 Joystick1Lamp3Status 3 "Not available" 2 "Flashing" 1 "On" 0 "Off" ;
VAL_ 2566692094 Joystick1Lamp2Status 3 "Not available" 2 "Flashing" 1 "On" 0 "Off" ;
VAL_ 2566692094 Joystick1Lamp1Status 3 "Not available" 2 "Flashing" 1 "On" 0 "Off" ;
VAL_ 2566691838 Joystick2Lamp10Status 3 "Not available" 2 "Flashing" 1 "On" 0 "Off" ;
VAL_ 2566691838 Joystick2Lamp9Status 3 "Not available" 2 "Flashing" 1 "On" 0 "Off" ;
VAL_ 2566691838 Joystick2Lamp8Status 3 "Not available" 2 "Flashing" 1 "On" 0 "Off" ;
VAL_ 2566691838 Joystick2Lamp7Status 3 "Not available" 2 "Flashing" 1 "On" 0 "Off" ;
VAL_ 2566691838 Joystick2Lamp6Status 3 "Not available" 2 "Flashing" 1 "On" 0 "Off" ;
VAL_ 2566691838 Joystick2Lamp5Status 1 "On" 0 "Off" 3 "Not available" 2 "Flashing" ;
VAL_ 2566691838 Joystick2Lamp4Status 3 "Not available" 2 "Flashing" 1 "On" 0 "Off" ;
VAL_ 2566691838 Joystick2Lamp3Status 3 "Not available" 2 "Flashing" 1 "On" 0 "Off" ;
VAL_ 2566691838 Joystick2Lamp2Status 3 "Not available" 2 "Flashing" 1 "On" 0 "Off" ;
VAL_ 2566691838 Joystick2Lamp1Status 3 "Not available" 2 "Flashing" 1 "On" 0 "Off" ;
VAL_ 2566691582 Joystick3Lamp10Status 3 "Not available" 2 "Flashing" 1 "On" 0 "Off" ;
VAL_ 2566691582 Joystick3Lamp9Status 3 "Not available" 2 "Flashing" 1 "On" 0 "Off" ;
VAL_ 2566691582 Joystick3Lamp8Status 3 "Not available" 2 "Flashing" 1 "On" 0 "Off" ;
VAL_ 2566691582 Joystick3Lamp7Status 3 "Not available" 2 "Flashing" 1 "On" 0 "Off" ;
VAL_ 2566691582 Joystick3Lamp6Status 3 "Not available" 2 "Flashing" 1 "On" 0 "Off" ;
VAL_ 2566691582 Joystick3Lamp5Status 3 "Not available" 2 "Flashing" 1 "On" 0 "Off" ;
VAL_ 2566691582 Joystick3Lamp4Status 3 "Not available" 2 "Flashing" 1 "On" 0 "Off" ;
VAL_ 2566691582 Joystick3Lamp3Status 3 "Not available" 2 "Flashing" 1 "On" 0 "Off" ;
VAL_ 2566691582 Joystick3Lamp2Status 3 "Not available" 2 "Flashing" 1 "On" 0 "Off" ;
VAL_ 2566691582 Joystick3Lamp1Status 3 "Not available" 2 "Flashing" 1 "On" 0 "Off" ;
VAL_ 2499582206 SoftTopLifetimeLimitExceeded 3 "Not Available" 2 "Reserved" 1 "Soft top ratio limit has been exceeded" 0 "Soft top ratio limit has not been exceeded" ;
VAL_ 2499582206 SoftTopSpeedLimitActive 3 "Not Available" 2 "Reserved" 1 "Soft Top Speed Limit is Active" 0 "Soft Top Speed Limit is Inactive" ;
VAL_ 2566690814 CrabSteerModeActuatorState 3 "Not Available" 2 "Error" 1 "Crab Steer Mode actuator active" 0 "Crab Steer Mode actuator inactive" ;
VAL_ 2566690814 CircleSteerModeActuatorState 3 "Not Available" 2 "Error" 1 "Circle Steer Mode actuator active" 0 "Circle Steer Mode actuator inactive" ;
VAL_ 2566690814 VourWheelSteerActuatorState 3 "Not Available" 2 "Error" 1 "4 Wheel Steer actuator active" 0 "4 Wheel Steer actuator inactive" ;
VAL_ 2566690814 TwoWheelSteerActuatorState 3 "Not Available" 2 "Error" 1 "2 Wheel Steer actuator active" 0 "2 Wheel Steer actuator inactive" ;
VAL_ 2566690814 RearSteerAxleCenteredStatus 3 "Not Available" 2 "Error" 1 "Rear Axle Not Centered" 0 "Rear Axle Centered" ;
VAL_ 2566690814 FrontSteerAxleCenteredStatus 3 "Not Available" 2 "Error" 1 "Front Axle Not Centered" 0 "Front Axle Centered" ;
VAL_ 2566690814 SteerModeSwitch 7 "Not Available" 6 "Error" 3 "Crab Steer Mode" 1 "Circle Steer Mode" 0 "2 Wheel Steer Mode" ;
VAL_ 2566690046 AfterrunCompleteThisCycle 3 "Not Supported" 2 "Error" 1 "Complete" 0 "Not complete" ;
VAL_ 2566690046 DEFDoserPurgeCompleteLastCycle 3 "Not Supported" 2 "Error" 1 "Complete" 0 "Not complete" ;
VAL_ 2566690046 DEFDoserPurgeCompleteThisCycle 3 "Not Supported" 2 "Error" 1 "Complete" 0 "Not complete" ;
VAL_ 2566690046 DEFDoserCldnCompleteLastCycle 3 "Not Supported" 2 "Error" 1 "Complete" 0 "Not complete" ;
VAL_ 2566690046 DEFDoserCldnCompleteThisCycle 3 "Not Supported" 2 "Error" 1 "Complete" 0 "Not complete" ;
VAL_ 2365428734 GenFrequencySelection 14 "Unknown" 2 "400 Hz" 1 "60 Hz" 0 "50 Hz" ;
VAL_ 2365428734 GenGoverningSpeedCommand 3 "Don't care / take no action" 2 "Reserved" 1 "Low Idle Speed" 0 "Rated Speed" ;
VAL_ 2365428734 GenNotReadyToAutoParaState 3 "not available" 2 "error" 1 "active" 0 "inactive" ;
VAL_ 2365428734 GenCtrlNotInAutoStartState 3 "not available" 2 "error" 1 "active" 0 "inactive" ;
VAL_ 2566702846 EngOBDWarmUpSequence 3 "Not supported or not available" 2 "SAE reserved" 1 "A warm-up cycle has occurred on this engine start" 0 "A warm-up cycle has not occurred on this engine start" ;
VAL_ 2566705918 FlashProtectLamp 3 "Unavailable / Do Not Flash" 2 "Reserved" 1 "Fast Flash" 0 "Slow Flash" ;
VAL_ 2566705918 FlashAmberWarningLamp 3 "Unavailable / Do Not Flash" 2 "Reserved" 1 "Fast Flash" 0 "Slow Flash" ;
VAL_ 2566705918 FlashRedStopLamp 3 "Unavailable / Do Not Flash" 2 "Reserved" 1 "Fast Flash" 0 "Slow Flash" ;
VAL_ 2566705918 FlashMalfuncIndicatorLamp 3 "Unavailable / Do Not Flash" 2 "Class C DTC  " 1 "Fast Flash" 0 "Slow Flash" ;
VAL_ 2566705918 ProtectLampStatus 3 "Not available" 2 "Reserved" 1 "Lamp On" 0 "Lamp Off" ;
VAL_ 2566705918 AmberWarningLampStatus 3 "Not available" 2 "Reserved" 1 "Lamp On" 0 "Lamp Off" ;
VAL_ 2566705918 RedStopLampState 3 "Not available" 2 "Reserved" 1 "Lamp On" 0 "Lamp Off" ;
VAL_ 2566705918 MalfunctionIndicatorLampStatus 3 "Not available" 2 "Short MIL for WWH OBD" 1 "Lamp On" 0 "Lamp Off" ;
VAL_ 2566705662 FlashProtectLamp 3 "Unavailable / Do Not Flash" 2 "Reserved" 1 "Fast Flash" 0 "Slow Flash" ;
VAL_ 2566705662 FlashAmberWarningLamp 3 "Unavailable / Do Not Flash" 2 "Reserved" 1 "Fast Flash" 0 "Slow Flash" ;
VAL_ 2566705662 FlashRedStopLamp 3 "Unavailable / Do Not Flash" 2 "Reserved" 1 "Fast Flash" 0 "Slow Flash" ;
VAL_ 2566705662 FlashMalfuncIndicatorLamp 3 "Unavailable / Do Not Flash" 2 "Class C DTC  " 1 "Fast Flash" 0 "Slow Flash" ;
VAL_ 2566705662 ProtectLampStatus 3 "Not available" 2 "Reserved" 1 "Lamp On" 0 "Lamp Off" ;
VAL_ 2566705662 AmberWarningLampStatus 3 "Not available" 2 "Reserved" 1 "Lamp On" 0 "Lamp Off" ;
VAL_ 2566705662 RedStopLampState 3 "Not available" 2 "Reserved" 1 "Lamp On" 0 "Lamp Off" ;
VAL_ 2566705662 MalfunctionIndicatorLampStatus 3 "Not available" 2 "Short MIL for WWH OBD" 1 "Lamp On" 0 "Lamp Off" ;
VAL_ 2349465342 StaticRollAngleStatus 7 "Not available" 6 "Error" 5 "Reserved" 4 "Angle Data Invalid" 3 "Sensor Reboots" 2 "Sensor Defect" 1 "Sensor OK" 0 "Sensor Busy" ;
VAL_ 2364553470 EngDualFuelModeCmd 3 "Not available" 2 "Reserved" 1 "Activate dual fuel mode" 0 "De-activate dual fuel mode" ;
VAL_ 2364553214 EngTrbCmprssrBlwffActtr1OprtnStt 15 "Not available" 14 "Error" 6 "Calibration in Progress" 5 "Uncontrolled Shutdown Active" 4 "Controlled Shutdown Active" 3 "Derate Active" 2 "Alarm High Severity" 1 "Alarm" 0 "Normal" ;
VAL_ 2364553214 EngTrbCmprssrBlwffActtr1TmpSttus 7 "Not available" 6 "Error" 5 "Not Defined" 4 "Low Most severe" 3 "Low Least severe" 2 "In Range" 1 "High Least severe" 0 "High Most severe" ;
VAL_ 2565874430 PersistentLimitStatus 7 "Not available" 6 "Non-recoverable fault" 3 "Limited low" 2 "Limited high" 1 "Operator limited/controlled" 0 "Not limited" ;
VAL_ 2565874430 MachineSelectedSpeedSource 7 "Not available" 4 "'Simulated' speed" 3 "'Blended' speed" 2 "Navigation-based speed" 1 "Ground-based speed" 0 "Wheel-based speed" ;
VAL_ 2565874430 MachineSelectedDirection 2 "Error indication" 1 "Forward" 0 "Reverse" 3 "Not available" ;
VAL_ 2559049470 DesiredEngFuelingState 3 "Don't care / Take no action" 2 "Parameter supported" 1 "Fueling desired" 0 "Fueling not desired" ;
VAL_ 2559049470 RequestedFuelType 255 "Not supported" 254 "Reserved for use in SPN 5837" 24 "Reserved for use in SPN 5837" 23 "Natural Gas" 7 "Propane" 6 "Compressed Natural Gas" 5 "Liquefied Petroleum Gas" 4 "Diesel" 3 "Ethanol" 2 "Methanol" 1 "Gasoline/petrol" 0 "Not available" ;
VAL_ 2559049470 EngGasFuelUsageInhibited 3 "Not available" 2 "Error" 1 "Gaseous Fuel Usage Inhibited" 0 "Gaseous Fuel Usage Not Inhibited" ;
VAL_ 2349596414 AebSensSetgReq 3 "NA" 2 "Late" 1 "Standard" 0 "Early" ;
VAL_ 2349596414 DrvrActvtnDmndFrAdvncdEmrgncyBrk 3 "don't' care / take no action" 2 "reserved" 1 "the driver wants the Advanced Emergency Braking System to warn or intervene if necessary" 0 "the driver does not want the Advanced Emergency Braking System to warn or intervene at any time" ;
VAL_ 2563571454 DataFormat_ErrorCondition 3 "Not Available or error" 2 "Data format is unsigned Long Integer" 1 "Data format is Floating" 0 "Data format is Long Integer" ;
VAL_ 2563571454 ProcessDataType 3 "Message is Actual value request" 2 "Message is Set Point request" 1 "Data is Actual values" 0 "Data is Set Point" ;
VAL_ 2563505918 DataFormat_ErrorCondition 3 "Not Available or error" 2 "Data format is unsigned Long Integer" 1 "Data format is Floating" 0 "Data format is Long Integer" ;
VAL_ 2563505918 ProcessDataType 3 "Message is Actual value request" 2 "Message is Set Point request" 1 "Data is Actual values" 0 "Data is Set Point" ;
VAL_ 2563178238 ValveFailSafeMode 3 "Don't Care" 2 "Reserved" 1 "Float" 0 "Block" ;
VAL_ 2563178238 ValveState 15 "Don't Care" 3 "Floating" 2 "Retract" 1 "Extend" 0 "Blocked" ;
